VERSION ""

NS_ :

BS_:

BU_: AGSM BCM BSM CADM DMSM DTCM ECM EVCU2 GNMM HCP IPC RFHM SGW TCM
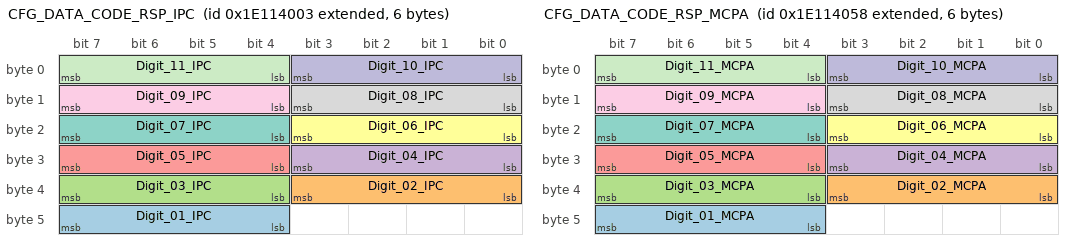
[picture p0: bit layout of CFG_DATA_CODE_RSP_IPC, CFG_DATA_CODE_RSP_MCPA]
BO_ 2651930627 CFG_DATA_CODE_RSP_IPC: 6 IPC
 SG_ Digit_01_IPC : 47|4@0+ (1,0) [0|15] "-" BCM
 SG_ Digit_02_IPC : 35|4@0+ (1,0) [0|15] "-" BCM
 SG_ Digit_03_IPC : 39|4@0+ (1,0) [0|15] "-" BCM
 SG_ Digit_04_IPC : 27|4@0+ (1,0) [0|15] "-" BCM
 SG_ Digit_05_IPC : 31|4@0+ (1,0) [0|15] "-" BCM
 SG_ Digit_06_IPC : 19|4@0+ (1,0) [0|15] "-" BCM
 SG_ Digit_07_IPC : 23|4@0+ (1,0) [0|15] "-" BCM
 SG_ Digit_08_IPC : 11|4@0+ (1,0) [0|15] "-" BCM
 SG_ Digit_09_IPC : 15|4@0+ (1,0) [0|15] "-" BCM
 SG_ Digit_10_IPC : 3|4@0+ (1,0) [0|15] "-" BCM
 SG_ Digit_11_IPC : 7|4@0+ (1,0) [0|15] "-" BCM

BO_ 2651930712 CFG_DATA_CODE_RSP_MCPA: 6 EVCU2
 SG_ Digit_01_MCPA : 47|4@0+ (1,0) [0|15] "-" BCM
 SG_ Digit_02_MCPA : 35|4@0+ (1,0) [0|15] "-" BCM
 SG_ Digit_03_MCPA : 39|4@0+ (1,0) [0|15] "-" BCM
 SG_ Digit_04_MCPA : 27|4@0+ (1,0) [0|15] "-" BCM
 SG_ Digit_05_MCPA : 31|4@0+ (1,0) [0|15] "-" BCM
 SG_ Digit_06_MCPA : 19|4@0+ (1,0) [0|15] "-" BCM
 SG_ Digit_07_MCPA : 23|4@0+ (1,0) [0|15] "-" BCM
 SG_ Digit_08_MCPA : 11|4@0+ (1,0) [0|15] "-" BCM
 SG_ Digit_09_MCPA : 15|4@0+ (1,0) [0|15] "-" BCM
 SG_ Digit_10_MCPA : 3|4@0+ (1,0) [0|15] "-" BCM
 SG_ Digit_11_MCPA : 7|4@0+ (1,0) [0|15] "-" BCM

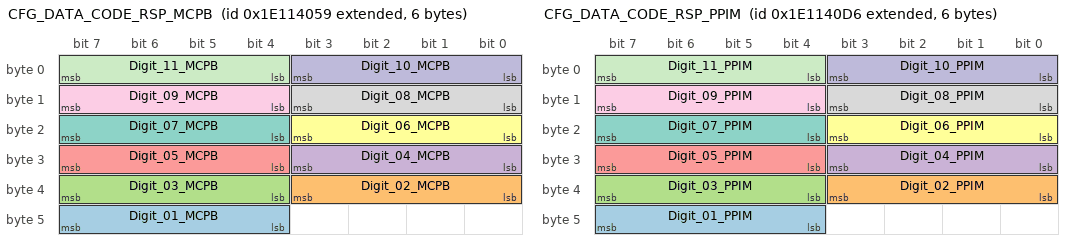
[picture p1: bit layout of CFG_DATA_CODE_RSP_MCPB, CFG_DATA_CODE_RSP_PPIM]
BO_ 2651930713 CFG_DATA_CODE_RSP_MCPB: 6 EVCU2
 SG_ Digit_01_MCPB : 47|4@0+ (1,0) [0|15] "-" BCM
 SG_ Digit_02_MCPB : 35|4@0+ (1,0) [0|15] "-" BCM
 SG_ Digit_03_MCPB : 39|4@0+ (1,0) [0|15] "-" BCM
 SG_ Digit_04_MCPB : 27|4@0+ (1,0) [0|15] "-" BCM
 SG_ Digit_05_MCPB : 31|4@0+ (1,0) [0|15] "-" BCM
 SG_ Digit_06_MCPB : 19|4@0+ (1,0) [0|15] "-" BCM
 SG_ Digit_07_MCPB : 23|4@0+ (1,0) [0|15] "-" BCM
 SG_ Digit_08_MCPB : 11|4@0+ (1,0) [0|15] "-" BCM
 SG_ Digit_09_MCPB : 15|4@0+ (1,0) [0|15] "-" BCM
 SG_ Digit_10_MCPB : 3|4@0+ (1,0) [0|15] "-" BCM
 SG_ Digit_11_MCPB : 7|4@0+ (1,0) [0|15] "-" BCM

BO_ 2651930838 CFG_DATA_CODE_RSP_PPIM: 6 EVCU2
 SG_ Digit_01_PPIM : 47|4@0+ (1,0) [0|15] "-" BCM
 SG_ Digit_02_PPIM : 35|4@0+ (1,0) [0|15] "-" BCM
 SG_ Digit_03_PPIM : 39|4@0+ (1,0) [0|15] "-" BCM
 SG_ Digit_04_PPIM : 27|4@0+ (1,0) [0|15] "-" BCM
 SG_ Digit_05_PPIM : 31|4@0+ (1,0) [0|15] "-" BCM
 SG_ Digit_06_PPIM : 19|4@0+ (1,0) [0|15] "-" BCM
 SG_ Digit_07_PPIM : 23|4@0+ (1,0) [0|15] "-" BCM
 SG_ Digit_08_PPIM : 11|4@0+ (1,0) [0|15] "-" BCM
 SG_ Digit_09_PPIM : 15|4@0+ (1,0) [0|15] "-" BCM
 SG_ Digit_10_PPIM : 3|4@0+ (1,0) [0|15] "-" BCM
 SG_ Digit_11_PPIM : 7|4@0+ (1,0) [0|15] "-" BCM

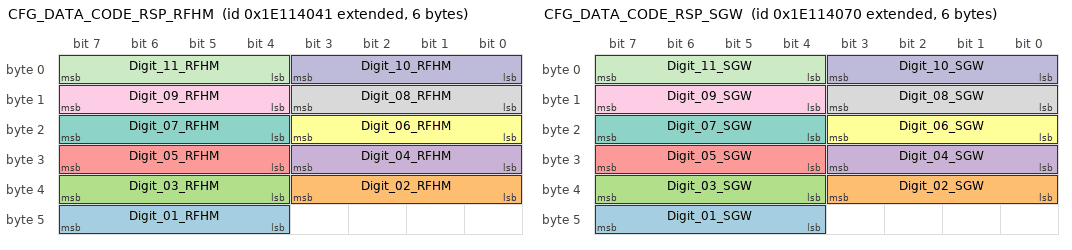
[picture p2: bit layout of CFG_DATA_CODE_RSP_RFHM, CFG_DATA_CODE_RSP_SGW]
BO_ 2651930689 CFG_DATA_CODE_RSP_RFHM: 6 RFHM
 SG_ Digit_01_RFHM : 47|4@0+ (1,0) [0|15] "-" BCM
 SG_ Digit_02_RFHM : 35|4@0+ (1,0) [0|15] "-" BCM
 SG_ Digit_03_RFHM : 39|4@0+ (1,0) [0|15] "-" BCM
 SG_ Digit_04_RFHM : 27|4@0+ (1,0) [0|15] "-" BCM
 SG_ Digit_05_RFHM : 31|4@0+ (1,0) [0|15] "-" BCM
 SG_ Digit_06_RFHM : 19|4@0+ (1,0) [0|15] "-" BCM
 SG_ Digit_07_RFHM : 23|4@0+ (1,0) [0|15] "-" BCM
 SG_ Digit_08_RFHM : 11|4@0+ (1,0) [0|15] "-" BCM
 SG_ Digit_09_RFHM : 15|4@0+ (1,0) [0|15] "-" BCM
 SG_ Digit_10_RFHM : 3|4@0+ (1,0) [0|15] "-" BCM
 SG_ Digit_11_RFHM : 7|4@0+ (1,0) [0|15] "-" BCM

BO_ 2651930736 CFG_DATA_CODE_RSP_SGW: 6 SGW
 SG_ Digit_01_SGW : 47|4@0+ (1,0) [0|15] "-" BCM
 SG_ Digit_02_SGW : 35|4@0+ (1,0) [0|15] "-" BCM
 SG_ Digit_03_SGW : 39|4@0+ (1,0) [0|15] "-" BCM
 SG_ Digit_04_SGW : 27|4@0+ (1,0) [0|15] "-" BCM
 SG_ Digit_05_SGW : 31|4@0+ (1,0) [0|15] "-" BCM
 SG_ Digit_06_SGW : 19|4@0+ (1,0) [0|15] "-" BCM
 SG_ Digit_07_SGW : 23|4@0+ (1,0) [0|15] "-" BCM
 SG_ Digit_08_SGW : 11|4@0+ (1,0) [0|15] "-" BCM
 SG_ Digit_09_SGW : 15|4@0+ (1,0) [0|15] "-" BCM
 SG_ Digit_10_SGW : 3|4@0+ (1,0) [0|15] "-" BCM
 SG_ Digit_11_SGW : 7|4@0+ (1,0) [0|15] "-" BCM

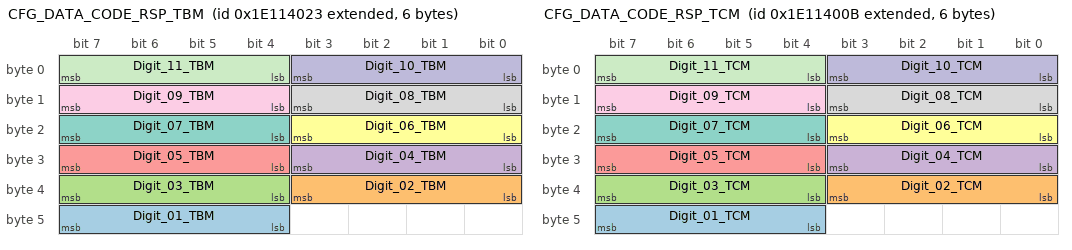
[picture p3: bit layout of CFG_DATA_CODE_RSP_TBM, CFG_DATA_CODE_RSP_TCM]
BO_ 2651930659 CFG_DATA_CODE_RSP_TBM: 6 SGW
 SG_ Digit_01_TBM : 47|4@0+ (1,0) [0|15] "-" BCM
 SG_ Digit_02_TBM : 35|4@0+ (1,0) [0|15] "-" BCM
 SG_ Digit_03_TBM : 39|4@0+ (1,0) [0|15] "-" BCM
 SG_ Digit_04_TBM : 27|4@0+ (1,0) [0|15] "-" BCM
 SG_ Digit_05_TBM : 31|4@0+ (1,0) [0|15] "-" BCM
 SG_ Digit_06_TBM : 19|4@0+ (1,0) [0|15] "-" BCM
 SG_ Digit_07_TBM : 23|4@0+ (1,0) [0|15] "-" BCM
 SG_ Digit_08_TBM : 11|4@0+ (1,0) [0|15] "-" BCM
 SG_ Digit_09_TBM : 15|4@0+ (1,0) [0|15] "-" BCM
 SG_ Digit_10_TBM : 3|4@0+ (1,0) [0|15] "-" BCM
 SG_ Digit_11_TBM : 7|4@0+ (1,0) [0|15] "-" BCM

BO_ 2651930635 CFG_DATA_CODE_RSP_TCM: 6 TCM
 SG_ Digit_01_TCM : 47|4@0+ (1,0) [0|15] "-" BCM
 SG_ Digit_02_TCM : 35|4@0+ (1,0) [0|15] "-" BCM
 SG_ Digit_03_TCM : 39|4@0+ (1,0) [0|15] "-" BCM
 SG_ Digit_04_TCM : 27|4@0+ (1,0) [0|15] "-" BCM
 SG_ Digit_05_TCM : 31|4@0+ (1,0) [0|15] "-" BCM
 SG_ Digit_06_TCM : 19|4@0+ (1,0) [0|15] "-" BCM
 SG_ Digit_07_TCM : 23|4@0+ (1,0) [0|15] "-" BCM
 SG_ Digit_08_TCM : 11|4@0+ (1,0) [0|15] "-" BCM
 SG_ Digit_09_TCM : 15|4@0+ (1,0) [0|15] "-" BCM
 SG_ Digit_10_TCM : 3|4@0+ (1,0) [0|15] "-" BCM
 SG_ Digit_11_TCM : 7|4@0+ (1,0) [0|15] "-" BCM

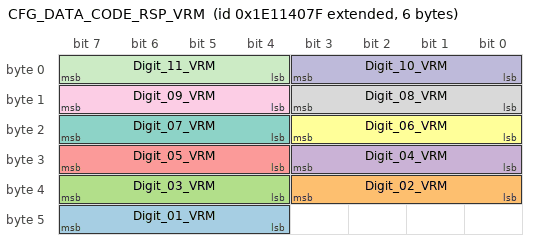
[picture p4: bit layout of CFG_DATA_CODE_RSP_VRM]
BO_ 2651930751 CFG_DATA_CODE_RSP_VRM: 6 SGW
 SG_ Digit_01_VRM : 47|4@0+ (1,0) [0|15] "-" BCM
 SG_ Digit_02_VRM : 35|4@0+ (1,0) [0|15] "-" BCM
 SG_ Digit_03_VRM : 39|4@0+ (1,0) [0|15] "-" BCM
 SG_ Digit_04_VRM : 27|4@0+ (1,0) [0|15] "-" BCM
 SG_ Digit_05_VRM : 31|4@0+ (1,0) [0|15] "-" BCM
 SG_ Digit_06_VRM : 19|4@0+ (1,0) [0|15] "-" BCM
 SG_ Digit_07_VRM : 23|4@0+ (1,0) [0|15] "-" BCM
 SG_ Digit_08_VRM : 11|4@0+ (1,0) [0|15] "-" BCM
 SG_ Digit_09_VRM : 15|4@0+ (1,0) [0|15] "-" BCM
 SG_ Digit_10_VRM : 3|4@0+ (1,0) [0|15] "-" BCM
 SG_ Digit_11_VRM : 7|4@0+ (1,0) [0|15] "-" BCM

BO_ 1457 CHARGE_SCHEDULE_HCP1: 32 EVCU2
 SG_ Charge_Schedule_Type1_Sts : 98|2@0+ (1,0) [0|3] "" SGW
 SG_ Charge_Schedule_Type2_Sts : 107|2@0+ (1,0) [0|3] "" SGW
 SG_ ChargeUntilFull1_Sts : 8|1@0+ (1,0) [0|1] "-" SGW
 SG_ ChargeUntilFull2_Sts : 32|1@0+ (1,0) [0|1] "-" SGW
 SG_ End_Time_Hr1_Sts : 39|5@0+ (1,0) [0|23] "Hours" SGW
 SG_ End_Time_Hr2_Sts : 71|5@0+ (1,0) [0|23] "Hours" SGW
 SG_ End_Time_Min1_Sts : 27|4@0+ (5,0) [0|55] "min" SGW
 SG_ End_Time_Min2_Sts : 79|4@0+ (5,0) [0|55] "min" SGW
 SG_ External_ChargeTarget1_Sts : 120|4@0+ (5,50) [50|125] "%" SGW
 SG_ External_ChargeTarget2_Sts : 132|4@0+ (5,50) [50|125] "%" SGW
 SG_ Immediate_ChargeTarget1_Sts : 117|4@0+ (5,0) [0|15] "%" SGW
 SG_ Immediate_ChargeTarget2_Sts : 124|4@0+ (5,0) [0|15] "%" SGW
 SG_ Schedule_Confirmed1 : 16|1@0+ (1,0) [0|1] "-" SGW
 SG_ Schedule_Confirmed2 : 48|1@0+ (1,0) [0|1] "-" SGW
 SG_ Schedule_Day1_Sts : 7|8@0+ (1,0) [0|255] "-" SGW
 SG_ Schedule_Day2_Sts : 47|8@0+ (1,0) [0|255] "-" SGW
 SG_ Start_Time_Hr1_Sts : 22|5@0+ (1,0) [0|23] "Hours" SGW
 SG_ Start_Time_Hr2_Sts : 54|5@0+ (1,0) [0|23] "Hours" SGW
 SG_ Start_Time_Min1_Sts : 31|4@0+ (5,0) [0|55] "min" SGW
 SG_ Start_Time_Min2_Sts : 63|4@0+ (5,0) [0|55] "min" SGW

BO_ 1464 CHARGE_SCHEDULE_HU1: 32 SGW
 SG_ Charge_Schedule_Type1 : 98|2@0+ (1,0) [0|3] "" EVCU2
 SG_ Charge_Schedule_Type2 : 106|2@0+ (1,0) [0|3] "" EVCU2
 SG_ ChargeUntilFull1 : 8|1@0+ (1,0) [0|1] "-" EVCU2
 SG_ ChargeUntilFull2 : 32|1@0+ (1,0) [0|1] "-" EVCU2
 SG_ Enable_Schedule1 : 72|1@0+ (1,0) [0|1] "-" EVCU2
 SG_ Enable_Schedule2 : 73|1@0+ (1,0) [0|1] "-" EVCU2
 SG_ End_Time_Hr1 : 39|5@0+ (1,0) [0|23] "Hours" EVCU2
 SG_ End_Time_Hr2 : 71|5@0+ (1,0) [0|23] "Hours" EVCU2
 SG_ End_Time_Min1 : 27|4@0+ (5,0) [0|55] "min" EVCU2
 SG_ End_Time_Min2 : 79|4@0+ (5,0) [0|55] "min" EVCU2
 SG_ External_ChargeTarget1 : 143|4@0+ (5,50) [50|125] "%" EVCU2
 SG_ External_ChargeTarget2 : 139|4@0+ (5,50) [50|125] "%" EVCU2
 SG_ Immediate_ChargeTarget1 : 135|4@0+ (5,0) [0|75] "%" EVCU2
 SG_ Immediate_ChargeTarget2 : 131|4@0+ (5,0) [0|75] "%" EVCU2
 SG_ Schedule_Day1 : 7|8@0+ (1,0) [0|255] "-" EVCU2
 SG_ Schedule_Day2 : 47|8@0+ (1,0) [0|255] "-" EVCU2
 SG_ Start_Time_Hr1 : 22|5@0+ (1,0) [0|23] "Hours" EVCU2
 SG_ Start_Time_Hr2 : 54|5@0+ (1,0) [0|23] "Hours" EVCU2
 SG_ Start_Time_Min1 : 31|4@0+ (5,0) [0|55] "min" EVCU2
 SG_ Start_Time_Min2 : 63|4@0+ (5,0) [0|55] "min" EVCU2
 SG_ Submit_Schedule1 : 16|1@0+ (1,0) [0|1] "-" EVCU2
 SG_ Submit_Schedule2 : 48|1@0+ (1,0) [0|1] "-" EVCU2

BO_ 1459 CHARGE_SCHEDULE_NEXT: 32 EVCU2
 SG_ Next_Charge_End_Time_Hr : 12|5@0+ (1,0) [0|30] "Hours" IPC,SGW
 SG_ Next_Charge_End_Time_Min : 39|4@0+ (5,0) [0|55] "min" IPC,SGW
 SG_ Next_Charge_EndDay : 31|4@0+ (1,0) [0|15] "-" IPC,SGW
 SG_ Next_Charge_Start_Time_Hr : 20|5@0+ (1,0) [0|23] "Hours" IPC,SGW
 SG_ Next_Charge_Start_Time_Min : 35|4@0+ (5,0) [0|55] "min" IPC,SGW
 SG_ Next_Charge_StartDay : 27|4@0+ (1,0) [0|15] "-" IPC,SGW
 SG_ Next_Climate_Day : 183|4@0+ (1,0) [0|15] "" SGW
 SG_ Next_Climate_Time_Hr : 172|5@0+ (1,0) [0|23] "Hours" SGW
 SG_ Next_Climate_Time_Min : 163|4@0+ (5,0) [0|55] "min" SGW
 SG_ Next_SchCabin_Temp : 4|5@0+ (0.5,16) [16|31] "°C" Vector__XXX
 SG_ Nxt_Charge_Schedule_Type : 58|2@0+ (1,0) [0|3] "" SGW
 SG_ Nxt_Ext_Charge_End_Time_Hr : 63|5@0+ (1,0) [0|31] "hours" SGW
 SG_ Nxt_Ext_Charge_End_Time_Min : 51|4@0+ (5,0) [0|75] "minutes" SGW
 SG_ Nxt_External_Charge_EndDay : 55|4@0+ (1,0) [0|15] "" SGW
 SG_ Nxt_External_Charge_ExternalTgt : 43|4@0+ (5,50) [50|125] "%" SGW
 SG_ Nxt_External_Charge_ImmediateTgt : 47|4@0+ (5,0) [0|75] "%" SGW

BO_ 1468 CLIMATE_SCHEDULE_HCP1: 32 EVCU2
 SG_ AllowClimateSchd1_Sts : 3|2@0+ (1,0) [0|2] "-" SGW
 SG_ AllowClimateSchd2_Sts : 1|2@0+ (1,0) [0|2] "-" SGW
 SG_ Climate_Cabin_Temp1_Sts : 39|5@0+ (0.5,16) [16|31] "°C" SGW
 SG_ Climate_Cabin_Temp2_Sts : 63|5@0+ (0.5,16) [16|31] "°C" SGW
 SG_ ClimateSchd1_Day_Sts : 47|8@0+ (1,0) [0|254] "-" SGW
 SG_ ClimateSchd1_Departure_Hr_Sts : 23|5@0+ (1,0) [0|30] "Hours" SGW
 SG_ ClimateSchd1_Departure_Min_Sts : 15|4@0+ (5,0) [0|70] "min" SGW
 SG_ ClimateSchd2_Day_Sts : 55|8@0+ (1,0) [0|254] "-" SGW
 SG_ ClimateSchd2_Departure_Hr_Sts : 31|5@0+ (1,0) [0|30] "Hours" SGW
 SG_ ClimateSchd2_Departure_Min_Sts : 11|4@0+ (5,0) [0|70] "min" SGW
 SG_ Enable_ClimateSchd1_Sts : 7|1@0+ (1,0) [0|1] "-" SGW
 SG_ Enable_ClimateSchd2_Sts : 6|1@0+ (1,0) [0|1] "-" SGW

BO_ 1471 CLIMATE_SCHEDULE_HU1: 32 SGW
 SG_ AllowClimateSchd1 : 3|2@0+ (1,0) [0|2] "-" EVCU2
 SG_ AllowClimateSchd2 : 1|2@0+ (1,0) [0|2] "-" EVCU2
 SG_ Climate_Cabin_Temp1 : 39|5@0+ (0.5,16) [16|31] "°C" EVCU2
 SG_ Climate_Cabin_Temp2 : 63|5@0+ (0.5,16) [16|31] "°C" EVCU2
 SG_ ClimateSchd1_Day : 47|8@0+ (1,0) [0|254] "-" EVCU2
 SG_ ClimateSchd1_Departure_Hr : 23|5@0+ (1,0) [0|30] "Hours" EVCU2
 SG_ ClimateSchd1_Departure_Min : 15|4@0+ (5,0) [0|70] "min" EVCU2
 SG_ ClimateSchd2_Day : 55|8@0+ (1,0) [0|254] "-" EVCU2
 SG_ ClimateSchd2_Departure_Hr : 31|5@0+ (1,0) [0|30] "Hours" EVCU2
 SG_ ClimateSchd2_Departure_Min : 11|4@0+ (5,0) [0|70] "min" EVCU2
 SG_ Enable_ClimateSchd1 : 7|1@0+ (1,0) [0|1] "-" EVCU2
 SG_ Enable_ClimateSchd2 : 6|1@0+ (1,0) [0|1] "-" EVCU2
 SG_ Submit_ClimateSchd1 : 5|1@0+ (1,0) [0|1] "-" EVCU2
 SG_ Submit_ClimateSchd2 : 4|1@0+ (1,0) [0|1] "-" EVCU2

CM_ SG_ 1457 Charge_Schedule_Type1_Sts "ECVU/HCP Schedule 1 Currently Set Charge Schedule Type";
CM_ SG_ 1457 Charge_Schedule_Type2_Sts "ECVU/HCP Schedule 2 Currently Set Charge Schedule Type";
CM_ SG_ 1457 ChargeUntilFull1_Sts "Charge until battery is fully charged with schedule 1";
CM_ SG_ 1457 ChargeUntilFull2_Sts "Charge until battery is fully charged with schedule 2 confirmation";
CM_ SG_ 1457 End_Time_Hr1_Sts "End Time of schedule 1 (hours in 24 hrs. format)";
CM_ SG_ 1457 End_Time_Hr2_Sts "End Time of schedule  2 (hours in 24 hrs. format) feedback";
CM_ SG_ 1457 End_Time_Min1_Sts "End Time of schedule 1(Minutes)";
CM_ SG_ 1457 End_Time_Min2_Sts "End Time of schedule  2 (Minutes) feedback";
CM_ SG_ 1457 External_ChargeTarget1_Sts "ECVU/HCP Schedule 1 Currently Set External Charge Target Value";
CM_ SG_ 1457 External_ChargeTarget2_Sts "ECVU/HCP Schedule 2 Currently Set External Charge Target Value";
CM_ SG_ 1457 Immediate_ChargeTarget1_Sts "ECVU/HCP Schedule 1 Currently Set Immediate Charge Target Value";
CM_ SG_ 1457 Immediate_ChargeTarget2_Sts "ECVU/HCP Schedule 2 Currently Set Immediate Charge Target Value
0 to 50% with 5% Increment";
CM_ SG_ 1457 Schedule_Confirmed1 "Confirm the requested schedule 1";
CM_ SG_ 1457 Schedule_Confirmed2 "Confirm the requested schedule 2";
CM_ SG_ 1457 Schedule_Day1_Sts "Schedule#1 Day for charging or cabin conditioning";
CM_ SG_ 1457 Schedule_Day2_Sts "Scheduled#2 Day for charging or cabin conditioning confirmation";
CM_ SG_ 1457 Start_Time_Hr1_Sts "Start Time of schedule  1 (hours in 24 hrs. format)";
CM_ SG_ 1457 Start_Time_Hr2_Sts "Start Time of schedule  2(hours in 24 hrs. format) feedback";
CM_ SG_ 1457 Start_Time_Min1_Sts "Start Time of schedule  1 (minutes)";
CM_ SG_ 1457 Start_Time_Min2_Sts "Start Time of schedule  2 (minutes) feedback";
CM_ SG_ 1464 Charge_Schedule_Type1 "HU Schedule 1 Setter Signal for Changing the Current Charge Schedule Type";
CM_ SG_ 1464 Charge_Schedule_Type2 "HU Schedule 2 Setter Signal for Changing the Current Charge Schedule Type";
CM_ SG_ 1464 ChargeUntilFull1 "Charge until battery is fully charged with schedule 1";
CM_ SG_ 1464 ChargeUntilFull2 "Charge until battery is fully charged with schedule 2";
CM_ SG_ 1464 Enable_Schedule1 "Schedule 1 checkbox enabled";
CM_ SG_ 1464 Enable_Schedule2 "Schedule 2 checkbox enabled";
CM_ SG_ 1464 End_Time_Hr1 "End Time of schedule 1 (hours in 24 hrs. format)";
CM_ SG_ 1464 End_Time_Hr2 "End Time of schedule  2 (hours in 24 hrs. format)";
CM_ SG_ 1464 End_Time_Min1 "End Time of schedule 1(Minutes)";
CM_ SG_ 1464 End_Time_Min2 "End Time of schedule  2(Minutes)";
CM_ SG_ 1464 External_ChargeTarget1 "HU Schedule 1 Setter Signal for Changing the Current External Charge Target Value 50 to 100% with 5% Increment";
CM_ SG_ 1464 External_ChargeTarget2 "HU Schedule 2 Setter Signal for Changing the Current External Charge Target Value";
CM_ SG_ 1464 Immediate_ChargeTarget1 "HU Schedule 1 Setter Signal for Changing the Current Immediate Charge Target Value";
CM_ SG_ 1464 Immediate_ChargeTarget2 "HU Schedule 2 Setter Signal for Changing the Current Immediate Charge Target Value";
CM_ SG_ 1464 Schedule_Day1 "Schedule#1 Day for charging or cabin conditioning";
CM_ SG_ 1464 Schedule_Day2 "Schedule#2 Day for charging or cabin conditioning";
CM_ SG_ 1464 Start_Time_Hr1 "Start Time of schedule  1 (hours in 24 hrs. format)";
CM_ SG_ 1464 Start_Time_Hr2 "Start Time of schedule  2(hours in 24 hrs. format)";
CM_ SG_ 1464 Start_Time_Min1 "Start Time of schedule  1 (minutes)";
CM_ SG_ 1464 Start_Time_Min2 "Start Time of schedule  2 (minutes)";
CM_ SG_ 1464 Submit_Schedule1 "Schedule 1 submitted";
CM_ SG_ 1464 Submit_Schedule2 "Schedule 2 submitted";
CM_ SG_ 1459 Next_Charge_End_Time_Hr "End time of next charge schedule window (hours, in 24hr format).";
CM_ SG_ 1459 Next_Charge_End_Time_Min "End time of next charge schedule window (in minutes).";
CM_ SG_ 1459 Next_Charge_EndDay "Next schedule end day to stop charging.";
CM_ SG_ 1459 Next_Charge_Start_Time_Hr "Start time of next charge schedule window (hours, in 24hr format).";
CM_ SG_ 1459 Next_Charge_Start_Time_Min "Start time of next charge schedule window (in minutes).";
CM_ SG_ 1459 Next_Charge_StartDay "Next schedule start day for charging.";
CM_ SG_ 1459 Next_Climate_Day "Next climate scheduled departure day";
CM_ SG_ 1459 Next_Climate_Time_Hr "Next climate scheduled departure time (hours, in 24hr format).";
CM_ SG_ 1459 Next_Climate_Time_Min "Next climate scheduled departure time (minutes).";
CM_ SG_ 1459 Next_SchCabin_Temp "Next Schedule cabin temperature";
CM_ SG_ 1459 Nxt_Charge_Schedule_Type "Standard, External or Both Charging of the Next Schedule";
CM_ SG_ 1459 Nxt_Ext_Charge_End_Time_Hr "End Hour for Next available External Charge";
CM_ SG_ 1459 Nxt_Ext_Charge_End_Time_Min "End Min for Next available External Charge";
CM_ SG_ 1459 Nxt_External_Charge_EndDay "End Day for Next available External Charge";
CM_ SG_ 1459 Nxt_External_Charge_ExternalTgt "Next Charge Display for Customer set External Target Display 50 to 100% with 5% Increment";
CM_ SG_ 1459 Nxt_External_Charge_ImmediateTgt "Next Charge Display for Customer set Immediate Target Display";
CM_ SG_ 1468 AllowClimateSchd1_Sts "Climate Scheduling1 Options";
CM_ SG_ 1468 AllowClimateSchd2_Sts "Climate Scheduling2 Options";
CM_ SG_ 1468 Climate_Cabin_Temp1_Sts "Schedule1 cabin temperature";
CM_ SG_ 1468 Climate_Cabin_Temp2_Sts "Schedule1 cabin temperature";
CM_ SG_ 1468 ClimateSchd1_Day_Sts "Scheduled#1 Day for cabin conditioning confirmation";
CM_ SG_ 1468 ClimateSchd1_Departure_Hr_Sts "Departure time of schedule 1 (hours in 24 hrs. format)";
CM_ SG_ 1468 ClimateSchd1_Departure_Min_Sts "Departure time of schedule 1(Minutes)";
CM_ SG_ 1468 ClimateSchd2_Day_Sts "Scheduled#2 Day for cabin conditioning confirmation";
CM_ SG_ 1468 ClimateSchd2_Departure_Hr_Sts "Departure time of schedule 2 (hours in 24 hrs. format)";
CM_ SG_ 1468 ClimateSchd2_Departure_Min_Sts "Departure time of schedule 2(Minutes)";
CM_ SG_ 1468 Enable_ClimateSchd1_Sts "Climate Schedule 1 checkbox enable status";
CM_ SG_ 1468 Enable_ClimateSchd2_Sts "Climate Schedule 2 checkbox enable status";
CM_ SG_ 1471 AllowClimateSchd1 "Climate Scheduling1 Options";
CM_ SG_ 1471 AllowClimateSchd2 "Climate Scheduling2 Options";
CM_ SG_ 1471 Climate_Cabin_Temp1 "Schedule1 cabin temperature";
CM_ SG_ 1471 Climate_Cabin_Temp2 "Schedule2 cabin temperature";
CM_ SG_ 1471 ClimateSchd1_Day "Schedule#1 Day for cabin conditioning";
CM_ SG_ 1471 ClimateSchd1_Departure_Hr "Departure time of schedule 1 (hours in 24 hrs. format)";
CM_ SG_ 1471 ClimateSchd1_Departure_Min "Departure time of schedule 1(Minutes)";
CM_ SG_ 1471 ClimateSchd2_Day "Scheduled#2 Day for cabin conditioning";
CM_ SG_ 1471 ClimateSchd2_Departure_Hr "Departure time of schedule 2 (hours in 24 hrs. format)";
CM_ SG_ 1471 ClimateSchd2_Departure_Min "Departure time of schedule 2(Minutes)";
CM_ SG_ 1471 Enable_ClimateSchd1 "Climate Schedule 1 checkbox enabled";
CM_ SG_ 1471 Enable_ClimateSchd2 "Climate Schedule 2 checkbox enabled";
CM_ SG_ 1471 Submit_ClimateSchd1 "Climate Schedule 1 submitted";
CM_ SG_ 1471 Submit_ClimateSchd2 "Climate Schedule 2 submitted";

BA_DEF_ SG_ "GenSigStartValue" INT 0 2147483647;
BA_DEF_ SG_ "GenSigInactiveValue" INT 0 2147483647;
BA_DEF_ SG_ "GenSigSendType" ENUM "NotUsed","OnWrite","OnWriteWithRepetition","OnChange","OnChangeWithRepetition","IfActive","IfActiveWithRepetition","NoSigSendType";
BA_DEF_ SG_ "SystemSignalLongSymbol" STRING ;
BA_DEF_ SG_ "GenSigTimeoutTime_AGSM" INT 0 65535;
BA_DEF_ SG_ "GenSigTimeoutTime_BCM" INT 0 65535;
BA_DEF_ SG_ "GenSigTimeoutTime_BSM" INT 0 65535;
BA_DEF_ SG_ "GenSigTimeoutTime_CADM" INT 0 65535;
BA_DEF_ SG_ "GenSigTimeoutTime_DMSM" INT 0 65535;
BA_DEF_ SG_ "GenSigTimeoutTime_DTCM" INT 0 65535;
BA_DEF_ SG_ "GenSigTimeoutTime_ECM" INT 0 65535;
BA_DEF_ SG_ "GenSigTimeoutTime_EVCU2" INT 0 65535;
BA_DEF_ SG_ "GenSigTimeoutTime_GNMM" INT 0 65535;
BA_DEF_ SG_ "GenSigTimeoutTime_HCP" INT 0 65535;
BA_DEF_ SG_ "GenSigTimeoutTime_IPC" INT 0 65535;
BA_DEF_ SG_ "GenSigTimeoutTime_RFHM" INT 0 65535;
BA_DEF_ SG_ "GenSigTimeoutTime_SGW" INT 0 65535;
BA_DEF_ SG_ "GenSigTimeoutTime_TCM" INT 0 65535;
BA_DEF_ BO_ "DiagRequest" ENUM "No","Yes";
BA_DEF_ BO_ "Type" ENUM "P","C","PE","COC","PE_Cntrl","E","E_Cntrl","OC","S","BAF","DC","EM","MM","ISO-TP","-";
BA_DEF_ BO_ "DiagResponse" ENUM "No","Yes";
BA_DEF_ BO_ "NmMessage" ENUM "No","Yes";
BA_DEF_ BO_ "GenMsgSendType" ENUM "Cyclic","NotUsed","NotUsed","NotUsed","NotUsed","NotUsed","NotUsed","NotUsed","NoMsgSendType";
BA_DEF_ BO_ "GenMsgNrOfRepetition" INT 0 255;
BA_DEF_ BO_ "GenMsgILSupport" ENUM "No","Yes";
BA_DEF_ BO_ "GenMsgStartDelayTime" INT 0 65535;
BA_DEF_ BO_ "GenMsgCycleTimeFast" INT 0 65535;
BA_DEF_ BO_ "GenMsgCycleTime" INT 0 65535;
BA_DEF_ BO_ "GenMsgDelayTime" INT 0 65535;
BA_DEF_ BO_ "NmAsrMessage" ENUM "No","Yes";
BA_DEF_ BO_ "DiagState" ENUM "No","Yes";
BA_DEF_ BO_ "DiagConnection" HEX 0 65535;
BA_DEF_ BO_ "VFrameFormat" ENUM "StandardCAN","ExtendedCAN","reserved","reserved","reserved","reserved","reserved","reserved","reserved","reserved","reserved","reserved","reserved","reserved","StandardCAN_FD","ExtendedCAN_FD";
BA_DEF_ BO_ "CANFD_BRS" ENUM "No","Yes";
BA_DEF_DEF_ "DiagRequest" "No";
BA_DEF_DEF_ "Type" "-";
BA_DEF_DEF_ "DiagResponse" "No";
BA_DEF_DEF_ "NmMessage" "No";
BA_DEF_DEF_ "GenMsgSendType" "NoMsgSendType";
BA_DEF_DEF_ "GenMsgNrOfRepetition" 0;
BA_DEF_DEF_ "GenMsgILSupport" "No";
BA_DEF_DEF_ "GenMsgStartDelayTime" 0;
BA_DEF_DEF_ "GenMsgCycleTimeFast" 0;
BA_DEF_DEF_ "GenMsgCycleTime" 0;
BA_DEF_DEF_ "GenMsgDelayTime" 0;
BA_DEF_DEF_ "NmAsrMessage" "No";
BA_DEF_DEF_ "DiagState" "No";
BA_DEF_DEF_ "DiagConnection" 0;
BA_DEF_DEF_ "VFrameFormat" "StandardCAN_FD";
BA_DEF_DEF_ "CANFD_BRS" "No";
BA_DEF_DEF_ "GenSigStartValue" 0;
BA_DEF_DEF_ "GenSigInactiveValue" 0;
BA_DEF_DEF_ "GenSigSendType" "NoSigSendType";
BA_DEF_DEF_ "SystemSignalLongSymbol" "";
BA_DEF_DEF_ "GenSigTimeoutTime_AGSM" 2500;
BA_DEF_DEF_ "GenSigTimeoutTime_BCM" 2500;
BA_DEF_DEF_ "GenSigTimeoutTime_BSM" 2500;
BA_DEF_DEF_ "GenSigTimeoutTime_CADM" 2500;
BA_DEF_DEF_ "GenSigTimeoutTime_DMSM" 2500;
BA_DEF_DEF_ "GenSigTimeoutTime_DTCM" 2500;
BA_DEF_DEF_ "GenSigTimeoutTime_ECM" 2500;
BA_DEF_DEF_ "GenSigTimeoutTime_EVCU2" 2500;
BA_DEF_DEF_ "GenSigTimeoutTime_GNMM" 2500;
BA_DEF_DEF_ "GenSigTimeoutTime_HCP" 2500;
BA_DEF_DEF_ "GenSigTimeoutTime_IPC" 2500;
BA_DEF_DEF_ "GenSigTimeoutTime_RFHM" 2500;
BA_DEF_DEF_ "GenSigTimeoutTime_SGW" 2500;
BA_DEF_DEF_ "GenSigTimeoutTime_TCM" 2500;
BA_ "Type" BO_ 2651930627 11;
BA_ "GenMsgILSupport" BO_ 2651930627 1;
BA_ "VFrameFormat" BO_ 2651930627 15;
BA_ "CANFD_BRS" BO_ 2651930627 1;
BA_ "Type" BO_ 2651930712 11;
BA_ "GenMsgILSupport" BO_ 2651930712 1;
BA_ "VFrameFormat" BO_ 2651930712 15;
BA_ "CANFD_BRS" BO_ 2651930712 1;
BA_ "Type" BO_ 2651930713 11;
BA_ "GenMsgILSupport" BO_ 2651930713 1;
BA_ "VFrameFormat" BO_ 2651930713 15;
BA_ "CANFD_BRS" BO_ 2651930713 1;
BA_ "Type" BO_ 2651930838 11;
BA_ "GenMsgILSupport" BO_ 2651930838 1;
BA_ "VFrameFormat" BO_ 2651930838 15;
BA_ "CANFD_BRS" BO_ 2651930838 1;
BA_ "Type" BO_ 2651930689 11;
BA_ "GenMsgILSupport" BO_ 2651930689 1;
BA_ "VFrameFormat" BO_ 2651930689 15;
BA_ "CANFD_BRS" BO_ 2651930689 1;
BA_ "Type" BO_ 2651930736 11;
BA_ "GenMsgILSupport" BO_ 2651930736 1;
BA_ "VFrameFormat" BO_ 2651930736 15;
BA_ "CANFD_BRS" BO_ 2651930736 1;
BA_ "Type" BO_ 2651930659 11;
BA_ "GenMsgILSupport" BO_ 2651930659 1;
BA_ "VFrameFormat" BO_ 2651930659 15;
BA_ "CANFD_BRS" BO_ 2651930659 1;
BA_ "Type" BO_ 2651930635 11;
BA_ "GenMsgILSupport" BO_ 2651930635 1;
BA_ "VFrameFormat" BO_ 2651930635 15;
BA_ "CANFD_BRS" BO_ 2651930635 1;
BA_ "Type" BO_ 2651930751 11;
BA_ "GenMsgILSupport" BO_ 2651930751 1;
BA_ "VFrameFormat" BO_ 2651930751 15;
BA_ "CANFD_BRS" BO_ 2651930751 1;
BA_ "Type" BO_ 1457 3;
BA_ "GenMsgSendType" BO_ 1457 0;
BA_ "GenMsgILSupport" BO_ 1457 1;
BA_ "GenMsgCycleTime" BO_ 1457 1000;
BA_ "GenMsgDelayTime" BO_ 1457 20;
BA_ "CANFD_BRS" BO_ 1457 1;
BA_ "Type" BO_ 1464 3;
BA_ "GenMsgSendType" BO_ 1464 0;
BA_ "GenMsgILSupport" BO_ 1464 1;
BA_ "GenMsgStartDelayTime" BO_ 1464 230;
BA_ "GenMsgCycleTime" BO_ 1464 1000;
BA_ "GenMsgDelayTime" BO_ 1464 20;
BA_ "CANFD_BRS" BO_ 1464 1;
BA_ "Type" BO_ 1459 3;
BA_ "GenMsgSendType" BO_ 1459 0;
BA_ "GenMsgILSupport" BO_ 1459 1;
BA_ "GenMsgCycleTime" BO_ 1459 1000;
BA_ "GenMsgDelayTime" BO_ 1459 20;
BA_ "CANFD_BRS" BO_ 1459 1;
BA_ "Type" BO_ 1468 3;
BA_ "GenMsgSendType" BO_ 1468 0;
BA_ "GenMsgILSupport" BO_ 1468 1;
BA_ "GenMsgCycleTime" BO_ 1468 1000;
BA_ "CANFD_BRS" BO_ 1468 1;
BA_ "Type" BO_ 1471 3;
BA_ "GenMsgSendType" BO_ 1471 0;
BA_ "GenMsgILSupport" BO_ 1471 1;
BA_ "GenMsgCycleTime" BO_ 1471 1000;
BA_ "CANFD_BRS" BO_ 1471 1;
BA_ "GenSigSendType" SG_ 2651930627 Digit_01_IPC 1;
BA_ "GenSigTimeoutTime_AGSM" SG_ 2651930627 Digit_01_IPC 0;
BA_ "GenSigTimeoutTime_BSM" SG_ 2651930627 Digit_01_IPC 0;
BA_ "GenSigTimeoutTime_CADM" SG_ 2651930627 Digit_01_IPC 0;
BA_ "GenSigTimeoutTime_DMSM" SG_ 2651930627 Digit_01_IPC 0;
BA_ "GenSigTimeoutTime_DTCM" SG_ 2651930627 Digit_01_IPC 0;
BA_ "GenSigTimeoutTime_ECM" SG_ 2651930627 Digit_01_IPC 0;
BA_ "GenSigTimeoutTime_EVCU2" SG_ 2651930627 Digit_01_IPC 0;
BA_ "GenSigTimeoutTime_GNMM" SG_ 2651930627 Digit_01_IPC 0;
BA_ "GenSigTimeoutTime_HCP" SG_ 2651930627 Digit_01_IPC 0;
BA_ "GenSigTimeoutTime_IPC" SG_ 2651930627 Digit_01_IPC 0;
BA_ "GenSigTimeoutTime_RFHM" SG_ 2651930627 Digit_01_IPC 0;
BA_ "GenSigTimeoutTime_SGW" SG_ 2651930627 Digit_01_IPC 0;
BA_ "GenSigTimeoutTime_TCM" SG_ 2651930627 Digit_01_IPC 0;
BA_ "GenSigTimeoutTime_AGSM" SG_ 2651930627 Digit_02_IPC 0;
BA_ "GenSigTimeoutTime_BSM" SG_ 2651930627 Digit_02_IPC 0;
BA_ "GenSigTimeoutTime_CADM" SG_ 2651930627 Digit_02_IPC 0;
BA_ "GenSigTimeoutTime_DMSM" SG_ 2651930627 Digit_02_IPC 0;
BA_ "GenSigTimeoutTime_DTCM" SG_ 2651930627 Digit_02_IPC 0;
BA_ "GenSigTimeoutTime_ECM" SG_ 2651930627 Digit_02_IPC 0;
BA_ "GenSigTimeoutTime_EVCU2" SG_ 2651930627 Digit_02_IPC 0;
BA_ "GenSigTimeoutTime_GNMM" SG_ 2651930627 Digit_02_IPC 0;
BA_ "GenSigTimeoutTime_HCP" SG_ 2651930627 Digit_02_IPC 0;
BA_ "GenSigTimeoutTime_IPC" SG_ 2651930627 Digit_02_IPC 0;
BA_ "GenSigTimeoutTime_RFHM" SG_ 2651930627 Digit_02_IPC 0;
BA_ "GenSigTimeoutTime_SGW" SG_ 2651930627 Digit_02_IPC 0;
BA_ "GenSigTimeoutTime_TCM" SG_ 2651930627 Digit_02_IPC 0;
BA_ "GenSigTimeoutTime_AGSM" SG_ 2651930627 Digit_03_IPC 0;
BA_ "GenSigTimeoutTime_BSM" SG_ 2651930627 Digit_03_IPC 0;
BA_ "GenSigTimeoutTime_CADM" SG_ 2651930627 Digit_03_IPC 0;
BA_ "GenSigTimeoutTime_DMSM" SG_ 2651930627 Digit_03_IPC 0;
BA_ "GenSigTimeoutTime_DTCM" SG_ 2651930627 Digit_03_IPC 0;
BA_ "GenSigTimeoutTime_ECM" SG_ 2651930627 Digit_03_IPC 0;
BA_ "GenSigTimeoutTime_EVCU2" SG_ 2651930627 Digit_03_IPC 0;
BA_ "GenSigTimeoutTime_GNMM" SG_ 2651930627 Digit_03_IPC 0;
BA_ "GenSigTimeoutTime_HCP" SG_ 2651930627 Digit_03_IPC 0;
BA_ "GenSigTimeoutTime_IPC" SG_ 2651930627 Digit_03_IPC 0;
BA_ "GenSigTimeoutTime_RFHM" SG_ 2651930627 Digit_03_IPC 0;
BA_ "GenSigTimeoutTime_SGW" SG_ 2651930627 Digit_03_IPC 0;
BA_ "GenSigTimeoutTime_TCM" SG_ 2651930627 Digit_03_IPC 0;
BA_ "GenSigTimeoutTime_AGSM" SG_ 2651930627 Digit_04_IPC 0;
BA_ "GenSigTimeoutTime_BSM" SG_ 2651930627 Digit_04_IPC 0;
BA_ "GenSigTimeoutTime_CADM" SG_ 2651930627 Digit_04_IPC 0;
BA_ "GenSigTimeoutTime_DMSM" SG_ 2651930627 Digit_04_IPC 0;
BA_ "GenSigTimeoutTime_DTCM" SG_ 2651930627 Digit_04_IPC 0;
BA_ "GenSigTimeoutTime_ECM" SG_ 2651930627 Digit_04_IPC 0;
BA_ "GenSigTimeoutTime_EVCU2" SG_ 2651930627 Digit_04_IPC 0;
BA_ "GenSigTimeoutTime_GNMM" SG_ 2651930627 Digit_04_IPC 0;
BA_ "GenSigTimeoutTime_HCP" SG_ 2651930627 Digit_04_IPC 0;
BA_ "GenSigTimeoutTime_IPC" SG_ 2651930627 Digit_04_IPC 0;
BA_ "GenSigTimeoutTime_RFHM" SG_ 2651930627 Digit_04_IPC 0;
BA_ "GenSigTimeoutTime_SGW" SG_ 2651930627 Digit_04_IPC 0;
BA_ "GenSigTimeoutTime_TCM" SG_ 2651930627 Digit_04_IPC 0;
BA_ "GenSigTimeoutTime_AGSM" SG_ 2651930627 Digit_05_IPC 0;
BA_ "GenSigTimeoutTime_BSM" SG_ 2651930627 Digit_05_IPC 0;
BA_ "GenSigTimeoutTime_CADM" SG_ 2651930627 Digit_05_IPC 0;
BA_ "GenSigTimeoutTime_DMSM" SG_ 2651930627 Digit_05_IPC 0;
BA_ "GenSigTimeoutTime_DTCM" SG_ 2651930627 Digit_05_IPC 0;
BA_ "GenSigTimeoutTime_ECM" SG_ 2651930627 Digit_05_IPC 0;
BA_ "GenSigTimeoutTime_EVCU2" SG_ 2651930627 Digit_05_IPC 0;
BA_ "GenSigTimeoutTime_GNMM" SG_ 2651930627 Digit_05_IPC 0;
BA_ "GenSigTimeoutTime_HCP" SG_ 2651930627 Digit_05_IPC 0;
BA_ "GenSigTimeoutTime_IPC" SG_ 2651930627 Digit_05_IPC 0;
BA_ "GenSigTimeoutTime_RFHM" SG_ 2651930627 Digit_05_IPC 0;
BA_ "GenSigTimeoutTime_SGW" SG_ 2651930627 Digit_05_IPC 0;
BA_ "GenSigTimeoutTime_TCM" SG_ 2651930627 Digit_05_IPC 0;
BA_ "GenSigTimeoutTime_AGSM" SG_ 2651930627 Digit_06_IPC 0;
BA_ "GenSigTimeoutTime_BSM" SG_ 2651930627 Digit_06_IPC 0;
BA_ "GenSigTimeoutTime_CADM" SG_ 2651930627 Digit_06_IPC 0;
BA_ "GenSigTimeoutTime_DMSM" SG_ 2651930627 Digit_06_IPC 0;
BA_ "GenSigTimeoutTime_DTCM" SG_ 2651930627 Digit_06_IPC 0;
BA_ "GenSigTimeoutTime_ECM" SG_ 2651930627 Digit_06_IPC 0;
BA_ "GenSigTimeoutTime_EVCU2" SG_ 2651930627 Digit_06_IPC 0;
BA_ "GenSigTimeoutTime_GNMM" SG_ 2651930627 Digit_06_IPC 0;
BA_ "GenSigTimeoutTime_HCP" SG_ 2651930627 Digit_06_IPC 0;
BA_ "GenSigTimeoutTime_IPC" SG_ 2651930627 Digit_06_IPC 0;
BA_ "GenSigTimeoutTime_RFHM" SG_ 2651930627 Digit_06_IPC 0;
BA_ "GenSigTimeoutTime_SGW" SG_ 2651930627 Digit_06_IPC 0;
BA_ "GenSigTimeoutTime_TCM" SG_ 2651930627 Digit_06_IPC 0;
BA_ "GenSigTimeoutTime_AGSM" SG_ 2651930627 Digit_07_IPC 0;
BA_ "GenSigTimeoutTime_BSM" SG_ 2651930627 Digit_07_IPC 0;
BA_ "GenSigTimeoutTime_CADM" SG_ 2651930627 Digit_07_IPC 0;
BA_ "GenSigTimeoutTime_DMSM" SG_ 2651930627 Digit_07_IPC 0;
BA_ "GenSigTimeoutTime_DTCM" SG_ 2651930627 Digit_07_IPC 0;
BA_ "GenSigTimeoutTime_ECM" SG_ 2651930627 Digit_07_IPC 0;
BA_ "GenSigTimeoutTime_EVCU2" SG_ 2651930627 Digit_07_IPC 0;
BA_ "GenSigTimeoutTime_GNMM" SG_ 2651930627 Digit_07_IPC 0;
BA_ "GenSigTimeoutTime_HCP" SG_ 2651930627 Digit_07_IPC 0;
BA_ "GenSigTimeoutTime_IPC" SG_ 2651930627 Digit_07_IPC 0;
BA_ "GenSigTimeoutTime_RFHM" SG_ 2651930627 Digit_07_IPC 0;
BA_ "GenSigTimeoutTime_SGW" SG_ 2651930627 Digit_07_IPC 0;
BA_ "GenSigTimeoutTime_TCM" SG_ 2651930627 Digit_07_IPC 0;
BA_ "GenSigTimeoutTime_AGSM" SG_ 2651930627 Digit_08_IPC 0;
BA_ "GenSigTimeoutTime_BSM" SG_ 2651930627 Digit_08_IPC 0;
BA_ "GenSigTimeoutTime_CADM" SG_ 2651930627 Digit_08_IPC 0;
BA_ "GenSigTimeoutTime_DMSM" SG_ 2651930627 Digit_08_IPC 0;
BA_ "GenSigTimeoutTime_DTCM" SG_ 2651930627 Digit_08_IPC 0;
BA_ "GenSigTimeoutTime_ECM" SG_ 2651930627 Digit_08_IPC 0;
BA_ "GenSigTimeoutTime_EVCU2" SG_ 2651930627 Digit_08_IPC 0;
BA_ "GenSigTimeoutTime_GNMM" SG_ 2651930627 Digit_08_IPC 0;
BA_ "GenSigTimeoutTime_HCP" SG_ 2651930627 Digit_08_IPC 0;
BA_ "GenSigTimeoutTime_IPC" SG_ 2651930627 Digit_08_IPC 0;
BA_ "GenSigTimeoutTime_RFHM" SG_ 2651930627 Digit_08_IPC 0;
BA_ "GenSigTimeoutTime_SGW" SG_ 2651930627 Digit_08_IPC 0;
BA_ "GenSigTimeoutTime_TCM" SG_ 2651930627 Digit_08_IPC 0;
BA_ "GenSigTimeoutTime_AGSM" SG_ 2651930627 Digit_09_IPC 0;
BA_ "GenSigTimeoutTime_BSM" SG_ 2651930627 Digit_09_IPC 0;
BA_ "GenSigTimeoutTime_CADM" SG_ 2651930627 Digit_09_IPC 0;
BA_ "GenSigTimeoutTime_DMSM" SG_ 2651930627 Digit_09_IPC 0;
BA_ "GenSigTimeoutTime_DTCM" SG_ 2651930627 Digit_09_IPC 0;
BA_ "GenSigTimeoutTime_ECM" SG_ 2651930627 Digit_09_IPC 0;
BA_ "GenSigTimeoutTime_EVCU2" SG_ 2651930627 Digit_09_IPC 0;
BA_ "GenSigTimeoutTime_GNMM" SG_ 2651930627 Digit_09_IPC 0;
BA_ "GenSigTimeoutTime_HCP" SG_ 2651930627 Digit_09_IPC 0;
BA_ "GenSigTimeoutTime_IPC" SG_ 2651930627 Digit_09_IPC 0;
BA_ "GenSigTimeoutTime_RFHM" SG_ 2651930627 Digit_09_IPC 0;
BA_ "GenSigTimeoutTime_SGW" SG_ 2651930627 Digit_09_IPC 0;
BA_ "GenSigTimeoutTime_TCM" SG_ 2651930627 Digit_09_IPC 0;
BA_ "GenSigTimeoutTime_AGSM" SG_ 2651930627 Digit_10_IPC 0;
BA_ "GenSigTimeoutTime_BSM" SG_ 2651930627 Digit_10_IPC 0;
BA_ "GenSigTimeoutTime_CADM" SG_ 2651930627 Digit_10_IPC 0;
BA_ "GenSigTimeoutTime_DMSM" SG_ 2651930627 Digit_10_IPC 0;
BA_ "GenSigTimeoutTime_DTCM" SG_ 2651930627 Digit_10_IPC 0;
BA_ "GenSigTimeoutTime_ECM" SG_ 2651930627 Digit_10_IPC 0;
BA_ "GenSigTimeoutTime_EVCU2" SG_ 2651930627 Digit_10_IPC 0;
BA_ "GenSigTimeoutTime_GNMM" SG_ 2651930627 Digit_10_IPC 0;
BA_ "GenSigTimeoutTime_HCP" SG_ 2651930627 Digit_10_IPC 0;
BA_ "GenSigTimeoutTime_IPC" SG_ 2651930627 Digit_10_IPC 0;
BA_ "GenSigTimeoutTime_RFHM" SG_ 2651930627 Digit_10_IPC 0;
BA_ "GenSigTimeoutTime_SGW" SG_ 2651930627 Digit_10_IPC 0;
BA_ "GenSigTimeoutTime_TCM" SG_ 2651930627 Digit_10_IPC 0;
BA_ "GenSigTimeoutTime_AGSM" SG_ 2651930627 Digit_11_IPC 0;
BA_ "GenSigTimeoutTime_BSM" SG_ 2651930627 Digit_11_IPC 0;
BA_ "GenSigTimeoutTime_CADM" SG_ 2651930627 Digit_11_IPC 0;
BA_ "GenSigTimeoutTime_DMSM" SG_ 2651930627 Digit_11_IPC 0;
BA_ "GenSigTimeoutTime_DTCM" SG_ 2651930627 Digit_11_IPC 0;
BA_ "GenSigTimeoutTime_ECM" SG_ 2651930627 Digit_11_IPC 0;
BA_ "GenSigTimeoutTime_EVCU2" SG_ 2651930627 Digit_11_IPC 0;
BA_ "GenSigTimeoutTime_GNMM" SG_ 2651930627 Digit_11_IPC 0;
BA_ "GenSigTimeoutTime_HCP" SG_ 2651930627 Digit_11_IPC 0;
BA_ "GenSigTimeoutTime_IPC" SG_ 2651930627 Digit_11_IPC 0;
BA_ "GenSigTimeoutTime_RFHM" SG_ 2651930627 Digit_11_IPC 0;
BA_ "GenSigTimeoutTime_SGW" SG_ 2651930627 Digit_11_IPC 0;
BA_ "GenSigTimeoutTime_TCM" SG_ 2651930627 Digit_11_IPC 0;
BA_ "GenSigSendType" SG_ 2651930712 Digit_01_MCPA 1;
BA_ "GenSigTimeoutTime_AGSM" SG_ 2651930712 Digit_01_MCPA 0;
BA_ "GenSigTimeoutTime_BSM" SG_ 2651930712 Digit_01_MCPA 0;
BA_ "GenSigTimeoutTime_CADM" SG_ 2651930712 Digit_01_MCPA 0;
BA_ "GenSigTimeoutTime_DMSM" SG_ 2651930712 Digit_01_MCPA 0;
BA_ "GenSigTimeoutTime_DTCM" SG_ 2651930712 Digit_01_MCPA 0;
BA_ "GenSigTimeoutTime_ECM" SG_ 2651930712 Digit_01_MCPA 0;
BA_ "GenSigTimeoutTime_EVCU2" SG_ 2651930712 Digit_01_MCPA 0;
BA_ "GenSigTimeoutTime_GNMM" SG_ 2651930712 Digit_01_MCPA 0;
BA_ "GenSigTimeoutTime_HCP" SG_ 2651930712 Digit_01_MCPA 0;
BA_ "GenSigTimeoutTime_IPC" SG_ 2651930712 Digit_01_MCPA 0;
BA_ "GenSigTimeoutTime_RFHM" SG_ 2651930712 Digit_01_MCPA 0;
BA_ "GenSigTimeoutTime_SGW" SG_ 2651930712 Digit_01_MCPA 0;
BA_ "GenSigTimeoutTime_TCM" SG_ 2651930712 Digit_01_MCPA 0;
BA_ "GenSigTimeoutTime_AGSM" SG_ 2651930712 Digit_02_MCPA 0;
BA_ "GenSigTimeoutTime_BSM" SG_ 2651930712 Digit_02_MCPA 0;
BA_ "GenSigTimeoutTime_CADM" SG_ 2651930712 Digit_02_MCPA 0;
BA_ "GenSigTimeoutTime_DMSM" SG_ 2651930712 Digit_02_MCPA 0;
BA_ "GenSigTimeoutTime_DTCM" SG_ 2651930712 Digit_02_MCPA 0;
BA_ "GenSigTimeoutTime_ECM" SG_ 2651930712 Digit_02_MCPA 0;
BA_ "GenSigTimeoutTime_EVCU2" SG_ 2651930712 Digit_02_MCPA 0;
BA_ "GenSigTimeoutTime_GNMM" SG_ 2651930712 Digit_02_MCPA 0;
BA_ "GenSigTimeoutTime_HCP" SG_ 2651930712 Digit_02_MCPA 0;
BA_ "GenSigTimeoutTime_IPC" SG_ 2651930712 Digit_02_MCPA 0;
BA_ "GenSigTimeoutTime_RFHM" SG_ 2651930712 Digit_02_MCPA 0;
BA_ "GenSigTimeoutTime_SGW" SG_ 2651930712 Digit_02_MCPA 0;
BA_ "GenSigTimeoutTime_TCM" SG_ 2651930712 Digit_02_MCPA 0;
BA_ "GenSigTimeoutTime_AGSM" SG_ 2651930712 Digit_03_MCPA 0;
BA_ "GenSigTimeoutTime_BSM" SG_ 2651930712 Digit_03_MCPA 0;
BA_ "GenSigTimeoutTime_CADM" SG_ 2651930712 Digit_03_MCPA 0;
BA_ "GenSigTimeoutTime_DMSM" SG_ 2651930712 Digit_03_MCPA 0;
BA_ "GenSigTimeoutTime_DTCM" SG_ 2651930712 Digit_03_MCPA 0;
BA_ "GenSigTimeoutTime_ECM" SG_ 2651930712 Digit_03_MCPA 0;
BA_ "GenSigTimeoutTime_EVCU2" SG_ 2651930712 Digit_03_MCPA 0;
BA_ "GenSigTimeoutTime_GNMM" SG_ 2651930712 Digit_03_MCPA 0;
BA_ "GenSigTimeoutTime_HCP" SG_ 2651930712 Digit_03_MCPA 0;
BA_ "GenSigTimeoutTime_IPC" SG_ 2651930712 Digit_03_MCPA 0;
BA_ "GenSigTimeoutTime_RFHM" SG_ 2651930712 Digit_03_MCPA 0;
BA_ "GenSigTimeoutTime_SGW" SG_ 2651930712 Digit_03_MCPA 0;
BA_ "GenSigTimeoutTime_TCM" SG_ 2651930712 Digit_03_MCPA 0;
BA_ "GenSigTimeoutTime_AGSM" SG_ 2651930712 Digit_04_MCPA 0;
BA_ "GenSigTimeoutTime_BSM" SG_ 2651930712 Digit_04_MCPA 0;
BA_ "GenSigTimeoutTime_CADM" SG_ 2651930712 Digit_04_MCPA 0;
BA_ "GenSigTimeoutTime_DMSM" SG_ 2651930712 Digit_04_MCPA 0;
BA_ "GenSigTimeoutTime_DTCM" SG_ 2651930712 Digit_04_MCPA 0;
BA_ "GenSigTimeoutTime_ECM" SG_ 2651930712 Digit_04_MCPA 0;
BA_ "GenSigTimeoutTime_EVCU2" SG_ 2651930712 Digit_04_MCPA 0;
BA_ "GenSigTimeoutTime_GNMM" SG_ 2651930712 Digit_04_MCPA 0;
BA_ "GenSigTimeoutTime_HCP" SG_ 2651930712 Digit_04_MCPA 0;
BA_ "GenSigTimeoutTime_IPC" SG_ 2651930712 Digit_04_MCPA 0;
BA_ "GenSigTimeoutTime_RFHM" SG_ 2651930712 Digit_04_MCPA 0;
BA_ "GenSigTimeoutTime_SGW" SG_ 2651930712 Digit_04_MCPA 0;
BA_ "GenSigTimeoutTime_TCM" SG_ 2651930712 Digit_04_MCPA 0;
BA_ "GenSigTimeoutTime_AGSM" SG_ 2651930712 Digit_05_MCPA 0;
BA_ "GenSigTimeoutTime_BSM" SG_ 2651930712 Digit_05_MCPA 0;
BA_ "GenSigTimeoutTime_CADM" SG_ 2651930712 Digit_05_MCPA 0;
BA_ "GenSigTimeoutTime_DMSM" SG_ 2651930712 Digit_05_MCPA 0;
BA_ "GenSigTimeoutTime_DTCM" SG_ 2651930712 Digit_05_MCPA 0;
BA_ "GenSigTimeoutTime_ECM" SG_ 2651930712 Digit_05_MCPA 0;
BA_ "GenSigTimeoutTime_EVCU2" SG_ 2651930712 Digit_05_MCPA 0;
BA_ "GenSigTimeoutTime_GNMM" SG_ 2651930712 Digit_05_MCPA 0;
BA_ "GenSigTimeoutTime_HCP" SG_ 2651930712 Digit_05_MCPA 0;
BA_ "GenSigTimeoutTime_IPC" SG_ 2651930712 Digit_05_MCPA 0;
BA_ "GenSigTimeoutTime_RFHM" SG_ 2651930712 Digit_05_MCPA 0;
BA_ "GenSigTimeoutTime_SGW" SG_ 2651930712 Digit_05_MCPA 0;
BA_ "GenSigTimeoutTime_TCM" SG_ 2651930712 Digit_05_MCPA 0;
BA_ "GenSigTimeoutTime_AGSM" SG_ 2651930712 Digit_06_MCPA 0;
BA_ "GenSigTimeoutTime_BSM" SG_ 2651930712 Digit_06_MCPA 0;
BA_ "GenSigTimeoutTime_CADM" SG_ 2651930712 Digit_06_MCPA 0;
BA_ "GenSigTimeoutTime_DMSM" SG_ 2651930712 Digit_06_MCPA 0;
BA_ "GenSigTimeoutTime_DTCM" SG_ 2651930712 Digit_06_MCPA 0;
BA_ "GenSigTimeoutTime_ECM" SG_ 2651930712 Digit_06_MCPA 0;
BA_ "GenSigTimeoutTime_EVCU2" SG_ 2651930712 Digit_06_MCPA 0;
BA_ "GenSigTimeoutTime_GNMM" SG_ 2651930712 Digit_06_MCPA 0;
BA_ "GenSigTimeoutTime_HCP" SG_ 2651930712 Digit_06_MCPA 0;
BA_ "GenSigTimeoutTime_IPC" SG_ 2651930712 Digit_06_MCPA 0;
BA_ "GenSigTimeoutTime_RFHM" SG_ 2651930712 Digit_06_MCPA 0;
BA_ "GenSigTimeoutTime_SGW" SG_ 2651930712 Digit_06_MCPA 0;
BA_ "GenSigTimeoutTime_TCM" SG_ 2651930712 Digit_06_MCPA 0;
BA_ "GenSigTimeoutTime_AGSM" SG_ 2651930712 Digit_07_MCPA 0;
BA_ "GenSigTimeoutTime_BSM" SG_ 2651930712 Digit_07_MCPA 0;
BA_ "GenSigTimeoutTime_CADM" SG_ 2651930712 Digit_07_MCPA 0;
BA_ "GenSigTimeoutTime_DMSM" SG_ 2651930712 Digit_07_MCPA 0;
BA_ "GenSigTimeoutTime_DTCM" SG_ 2651930712 Digit_07_MCPA 0;
BA_ "GenSigTimeoutTime_ECM" SG_ 2651930712 Digit_07_MCPA 0;
BA_ "GenSigTimeoutTime_EVCU2" SG_ 2651930712 Digit_07_MCPA 0;
BA_ "GenSigTimeoutTime_GNMM" SG_ 2651930712 Digit_07_MCPA 0;
BA_ "GenSigTimeoutTime_HCP" SG_ 2651930712 Digit_07_MCPA 0;
BA_ "GenSigTimeoutTime_IPC" SG_ 2651930712 Digit_07_MCPA 0;
BA_ "GenSigTimeoutTime_RFHM" SG_ 2651930712 Digit_07_MCPA 0;
BA_ "GenSigTimeoutTime_SGW" SG_ 2651930712 Digit_07_MCPA 0;
BA_ "GenSigTimeoutTime_TCM" SG_ 2651930712 Digit_07_MCPA 0;
BA_ "GenSigTimeoutTime_AGSM" SG_ 2651930712 Digit_08_MCPA 0;
BA_ "GenSigTimeoutTime_BSM" SG_ 2651930712 Digit_08_MCPA 0;
BA_ "GenSigTimeoutTime_CADM" SG_ 2651930712 Digit_08_MCPA 0;
BA_ "GenSigTimeoutTime_DMSM" SG_ 2651930712 Digit_08_MCPA 0;
BA_ "GenSigTimeoutTime_DTCM" SG_ 2651930712 Digit_08_MCPA 0;
BA_ "GenSigTimeoutTime_ECM" SG_ 2651930712 Digit_08_MCPA 0;
BA_ "GenSigTimeoutTime_EVCU2" SG_ 2651930712 Digit_08_MCPA 0;
BA_ "GenSigTimeoutTime_GNMM" SG_ 2651930712 Digit_08_MCPA 0;
BA_ "GenSigTimeoutTime_HCP" SG_ 2651930712 Digit_08_MCPA 0;
BA_ "GenSigTimeoutTime_IPC" SG_ 2651930712 Digit_08_MCPA 0;
BA_ "GenSigTimeoutTime_RFHM" SG_ 2651930712 Digit_08_MCPA 0;
BA_ "GenSigTimeoutTime_SGW" SG_ 2651930712 Digit_08_MCPA 0;
BA_ "GenSigTimeoutTime_TCM" SG_ 2651930712 Digit_08_MCPA 0;
BA_ "GenSigTimeoutTime_AGSM" SG_ 2651930712 Digit_09_MCPA 0;
BA_ "GenSigTimeoutTime_BSM" SG_ 2651930712 Digit_09_MCPA 0;
BA_ "GenSigTimeoutTime_CADM" SG_ 2651930712 Digit_09_MCPA 0;
BA_ "GenSigTimeoutTime_DMSM" SG_ 2651930712 Digit_09_MCPA 0;
BA_ "GenSigTimeoutTime_DTCM" SG_ 2651930712 Digit_09_MCPA 0;
BA_ "GenSigTimeoutTime_ECM" SG_ 2651930712 Digit_09_MCPA 0;
BA_ "GenSigTimeoutTime_EVCU2" SG_ 2651930712 Digit_09_MCPA 0;
BA_ "GenSigTimeoutTime_GNMM" SG_ 2651930712 Digit_09_MCPA 0;
BA_ "GenSigTimeoutTime_HCP" SG_ 2651930712 Digit_09_MCPA 0;
BA_ "GenSigTimeoutTime_IPC" SG_ 2651930712 Digit_09_MCPA 0;
BA_ "GenSigTimeoutTime_RFHM" SG_ 2651930712 Digit_09_MCPA 0;
BA_ "GenSigTimeoutTime_SGW" SG_ 2651930712 Digit_09_MCPA 0;
BA_ "GenSigTimeoutTime_TCM" SG_ 2651930712 Digit_09_MCPA 0;
BA_ "GenSigTimeoutTime_AGSM" SG_ 2651930712 Digit_10_MCPA 0;
BA_ "GenSigTimeoutTime_BSM" SG_ 2651930712 Digit_10_MCPA 0;
BA_ "GenSigTimeoutTime_CADM" SG_ 2651930712 Digit_10_MCPA 0;
BA_ "GenSigTimeoutTime_DMSM" SG_ 2651930712 Digit_10_MCPA 0;
BA_ "GenSigTimeoutTime_DTCM" SG_ 2651930712 Digit_10_MCPA 0;
BA_ "GenSigTimeoutTime_ECM" SG_ 2651930712 Digit_10_MCPA 0;
BA_ "GenSigTimeoutTime_EVCU2" SG_ 2651930712 Digit_10_MCPA 0;
BA_ "GenSigTimeoutTime_GNMM" SG_ 2651930712 Digit_10_MCPA 0;
BA_ "GenSigTimeoutTime_HCP" SG_ 2651930712 Digit_10_MCPA 0;
BA_ "GenSigTimeoutTime_IPC" SG_ 2651930712 Digit_10_MCPA 0;
BA_ "GenSigTimeoutTime_RFHM" SG_ 2651930712 Digit_10_MCPA 0;
BA_ "GenSigTimeoutTime_SGW" SG_ 2651930712 Digit_10_MCPA 0;
BA_ "GenSigTimeoutTime_TCM" SG_ 2651930712 Digit_10_MCPA 0;
BA_ "GenSigTimeoutTime_AGSM" SG_ 2651930712 Digit_11_MCPA 0;
BA_ "GenSigTimeoutTime_BSM" SG_ 2651930712 Digit_11_MCPA 0;
BA_ "GenSigTimeoutTime_CADM" SG_ 2651930712 Digit_11_MCPA 0;
BA_ "GenSigTimeoutTime_DMSM" SG_ 2651930712 Digit_11_MCPA 0;
BA_ "GenSigTimeoutTime_DTCM" SG_ 2651930712 Digit_11_MCPA 0;
BA_ "GenSigTimeoutTime_ECM" SG_ 2651930712 Digit_11_MCPA 0;
BA_ "GenSigTimeoutTime_EVCU2" SG_ 2651930712 Digit_11_MCPA 0;
BA_ "GenSigTimeoutTime_GNMM" SG_ 2651930712 Digit_11_MCPA 0;
BA_ "GenSigTimeoutTime_HCP" SG_ 2651930712 Digit_11_MCPA 0;
BA_ "GenSigTimeoutTime_IPC" SG_ 2651930712 Digit_11_MCPA 0;
BA_ "GenSigTimeoutTime_RFHM" SG_ 2651930712 Digit_11_MCPA 0;
BA_ "GenSigTimeoutTime_SGW" SG_ 2651930712 Digit_11_MCPA 0;
BA_ "GenSigTimeoutTime_TCM" SG_ 2651930712 Digit_11_MCPA 0;
BA_ "GenSigSendType" SG_ 2651930713 Digit_01_MCPB 1;
BA_ "GenSigTimeoutTime_AGSM" SG_ 2651930713 Digit_01_MCPB 0;
BA_ "GenSigTimeoutTime_BSM" SG_ 2651930713 Digit_01_MCPB 0;
BA_ "GenSigTimeoutTime_CADM" SG_ 2651930713 Digit_01_MCPB 0;
BA_ "GenSigTimeoutTime_DMSM" SG_ 2651930713 Digit_01_MCPB 0;
BA_ "GenSigTimeoutTime_DTCM" SG_ 2651930713 Digit_01_MCPB 0;
BA_ "GenSigTimeoutTime_ECM" SG_ 2651930713 Digit_01_MCPB 0;
BA_ "GenSigTimeoutTime_EVCU2" SG_ 2651930713 Digit_01_MCPB 0;
BA_ "GenSigTimeoutTime_GNMM" SG_ 2651930713 Digit_01_MCPB 0;
BA_ "GenSigTimeoutTime_HCP" SG_ 2651930713 Digit_01_MCPB 0;
BA_ "GenSigTimeoutTime_IPC" SG_ 2651930713 Digit_01_MCPB 0;
BA_ "GenSigTimeoutTime_RFHM" SG_ 2651930713 Digit_01_MCPB 0;
BA_ "GenSigTimeoutTime_SGW" SG_ 2651930713 Digit_01_MCPB 0;
BA_ "GenSigTimeoutTime_TCM" SG_ 2651930713 Digit_01_MCPB 0;
BA_ "GenSigTimeoutTime_AGSM" SG_ 2651930713 Digit_02_MCPB 0;
BA_ "GenSigTimeoutTime_BSM" SG_ 2651930713 Digit_02_MCPB 0;
BA_ "GenSigTimeoutTime_CADM" SG_ 2651930713 Digit_02_MCPB 0;
BA_ "GenSigTimeoutTime_DMSM" SG_ 2651930713 Digit_02_MCPB 0;
BA_ "GenSigTimeoutTime_DTCM" SG_ 2651930713 Digit_02_MCPB 0;
BA_ "GenSigTimeoutTime_ECM" SG_ 2651930713 Digit_02_MCPB 0;
BA_ "GenSigTimeoutTime_EVCU2" SG_ 2651930713 Digit_02_MCPB 0;
BA_ "GenSigTimeoutTime_GNMM" SG_ 2651930713 Digit_02_MCPB 0;
BA_ "GenSigTimeoutTime_HCP" SG_ 2651930713 Digit_02_MCPB 0;
BA_ "GenSigTimeoutTime_IPC" SG_ 2651930713 Digit_02_MCPB 0;
BA_ "GenSigTimeoutTime_RFHM" SG_ 2651930713 Digit_02_MCPB 0;
BA_ "GenSigTimeoutTime_SGW" SG_ 2651930713 Digit_02_MCPB 0;
BA_ "GenSigTimeoutTime_TCM" SG_ 2651930713 Digit_02_MCPB 0;
BA_ "GenSigTimeoutTime_AGSM" SG_ 2651930713 Digit_03_MCPB 0;
BA_ "GenSigTimeoutTime_BSM" SG_ 2651930713 Digit_03_MCPB 0;
BA_ "GenSigTimeoutTime_CADM" SG_ 2651930713 Digit_03_MCPB 0;
BA_ "GenSigTimeoutTime_DMSM" SG_ 2651930713 Digit_03_MCPB 0;
BA_ "GenSigTimeoutTime_DTCM" SG_ 2651930713 Digit_03_MCPB 0;
BA_ "GenSigTimeoutTime_ECM" SG_ 2651930713 Digit_03_MCPB 0;
BA_ "GenSigTimeoutTime_EVCU2" SG_ 2651930713 Digit_03_MCPB 0;
BA_ "GenSigTimeoutTime_GNMM" SG_ 2651930713 Digit_03_MCPB 0;
BA_ "GenSigTimeoutTime_HCP" SG_ 2651930713 Digit_03_MCPB 0;
BA_ "GenSigTimeoutTime_IPC" SG_ 2651930713 Digit_03_MCPB 0;
BA_ "GenSigTimeoutTime_RFHM" SG_ 2651930713 Digit_03_MCPB 0;
BA_ "GenSigTimeoutTime_SGW" SG_ 2651930713 Digit_03_MCPB 0;
BA_ "GenSigTimeoutTime_TCM" SG_ 2651930713 Digit_03_MCPB 0;
BA_ "GenSigTimeoutTime_AGSM" SG_ 2651930713 Digit_04_MCPB 0;
BA_ "GenSigTimeoutTime_BSM" SG_ 2651930713 Digit_04_MCPB 0;
BA_ "GenSigTimeoutTime_CADM" SG_ 2651930713 Digit_04_MCPB 0;
BA_ "GenSigTimeoutTime_DMSM" SG_ 2651930713 Digit_04_MCPB 0;
BA_ "GenSigTimeoutTime_DTCM" SG_ 2651930713 Digit_04_MCPB 0;
BA_ "GenSigTimeoutTime_ECM" SG_ 2651930713 Digit_04_MCPB 0;
BA_ "GenSigTimeoutTime_EVCU2" SG_ 2651930713 Digit_04_MCPB 0;
BA_ "GenSigTimeoutTime_GNMM" SG_ 2651930713 Digit_04_MCPB 0;
BA_ "GenSigTimeoutTime_HCP" SG_ 2651930713 Digit_04_MCPB 0;
BA_ "GenSigTimeoutTime_IPC" SG_ 2651930713 Digit_04_MCPB 0;
BA_ "GenSigTimeoutTime_RFHM" SG_ 2651930713 Digit_04_MCPB 0;
BA_ "GenSigTimeoutTime_SGW" SG_ 2651930713 Digit_04_MCPB 0;
BA_ "GenSigTimeoutTime_TCM" SG_ 2651930713 Digit_04_MCPB 0;
BA_ "GenSigTimeoutTime_AGSM" SG_ 2651930713 Digit_05_MCPB 0;
BA_ "GenSigTimeoutTime_BSM" SG_ 2651930713 Digit_05_MCPB 0;
BA_ "GenSigTimeoutTime_CADM" SG_ 2651930713 Digit_05_MCPB 0;
BA_ "GenSigTimeoutTime_DMSM" SG_ 2651930713 Digit_05_MCPB 0;
BA_ "GenSigTimeoutTime_DTCM" SG_ 2651930713 Digit_05_MCPB 0;
BA_ "GenSigTimeoutTime_ECM" SG_ 2651930713 Digit_05_MCPB 0;
BA_ "GenSigTimeoutTime_EVCU2" SG_ 2651930713 Digit_05_MCPB 0;
BA_ "GenSigTimeoutTime_GNMM" SG_ 2651930713 Digit_05_MCPB 0;
BA_ "GenSigTimeoutTime_HCP" SG_ 2651930713 Digit_05_MCPB 0;
BA_ "GenSigTimeoutTime_IPC" SG_ 2651930713 Digit_05_MCPB 0;
BA_ "GenSigTimeoutTime_RFHM" SG_ 2651930713 Digit_05_MCPB 0;
BA_ "GenSigTimeoutTime_SGW" SG_ 2651930713 Digit_05_MCPB 0;
BA_ "GenSigTimeoutTime_TCM" SG_ 2651930713 Digit_05_MCPB 0;
BA_ "GenSigTimeoutTime_AGSM" SG_ 2651930713 Digit_06_MCPB 0;
BA_ "GenSigTimeoutTime_BSM" SG_ 2651930713 Digit_06_MCPB 0;
BA_ "GenSigTimeoutTime_CADM" SG_ 2651930713 Digit_06_MCPB 0;
BA_ "GenSigTimeoutTime_DMSM" SG_ 2651930713 Digit_06_MCPB 0;
BA_ "GenSigTimeoutTime_DTCM" SG_ 2651930713 Digit_06_MCPB 0;
BA_ "GenSigTimeoutTime_ECM" SG_ 2651930713 Digit_06_MCPB 0;
BA_ "GenSigTimeoutTime_EVCU2" SG_ 2651930713 Digit_06_MCPB 0;
BA_ "GenSigTimeoutTime_GNMM" SG_ 2651930713 Digit_06_MCPB 0;
BA_ "GenSigTimeoutTime_HCP" SG_ 2651930713 Digit_06_MCPB 0;
BA_ "GenSigTimeoutTime_IPC" SG_ 2651930713 Digit_06_MCPB 0;
BA_ "GenSigTimeoutTime_RFHM" SG_ 2651930713 Digit_06_MCPB 0;
BA_ "GenSigTimeoutTime_SGW" SG_ 2651930713 Digit_06_MCPB 0;
BA_ "GenSigTimeoutTime_TCM" SG_ 2651930713 Digit_06_MCPB 0;
BA_ "GenSigTimeoutTime_AGSM" SG_ 2651930713 Digit_07_MCPB 0;
BA_ "GenSigTimeoutTime_BSM" SG_ 2651930713 Digit_07_MCPB 0;
BA_ "GenSigTimeoutTime_CADM" SG_ 2651930713 Digit_07_MCPB 0;
BA_ "GenSigTimeoutTime_DMSM" SG_ 2651930713 Digit_07_MCPB 0;
BA_ "GenSigTimeoutTime_DTCM" SG_ 2651930713 Digit_07_MCPB 0;
BA_ "GenSigTimeoutTime_ECM" SG_ 2651930713 Digit_07_MCPB 0;
BA_ "GenSigTimeoutTime_EVCU2" SG_ 2651930713 Digit_07_MCPB 0;
BA_ "GenSigTimeoutTime_GNMM" SG_ 2651930713 Digit_07_MCPB 0;
BA_ "GenSigTimeoutTime_HCP" SG_ 2651930713 Digit_07_MCPB 0;
BA_ "GenSigTimeoutTime_IPC" SG_ 2651930713 Digit_07_MCPB 0;
BA_ "GenSigTimeoutTime_RFHM" SG_ 2651930713 Digit_07_MCPB 0;
BA_ "GenSigTimeoutTime_SGW" SG_ 2651930713 Digit_07_MCPB 0;
BA_ "GenSigTimeoutTime_TCM" SG_ 2651930713 Digit_07_MCPB 0;
BA_ "GenSigTimeoutTime_AGSM" SG_ 2651930713 Digit_08_MCPB 0;
BA_ "GenSigTimeoutTime_BSM" SG_ 2651930713 Digit_08_MCPB 0;
BA_ "GenSigTimeoutTime_CADM" SG_ 2651930713 Digit_08_MCPB 0;
BA_ "GenSigTimeoutTime_DMSM" SG_ 2651930713 Digit_08_MCPB 0;
BA_ "GenSigTimeoutTime_DTCM" SG_ 2651930713 Digit_08_MCPB 0;
BA_ "GenSigTimeoutTime_ECM" SG_ 2651930713 Digit_08_MCPB 0;
BA_ "GenSigTimeoutTime_EVCU2" SG_ 2651930713 Digit_08_MCPB 0;
BA_ "GenSigTimeoutTime_GNMM" SG_ 2651930713 Digit_08_MCPB 0;
BA_ "GenSigTimeoutTime_HCP" SG_ 2651930713 Digit_08_MCPB 0;
BA_ "GenSigTimeoutTime_IPC" SG_ 2651930713 Digit_08_MCPB 0;
BA_ "GenSigTimeoutTime_RFHM" SG_ 2651930713 Digit_08_MCPB 0;
BA_ "GenSigTimeoutTime_SGW" SG_ 2651930713 Digit_08_MCPB 0;
BA_ "GenSigTimeoutTime_TCM" SG_ 2651930713 Digit_08_MCPB 0;
BA_ "GenSigTimeoutTime_AGSM" SG_ 2651930713 Digit_09_MCPB 0;
BA_ "GenSigTimeoutTime_BSM" SG_ 2651930713 Digit_09_MCPB 0;
BA_ "GenSigTimeoutTime_CADM" SG_ 2651930713 Digit_09_MCPB 0;
BA_ "GenSigTimeoutTime_DMSM" SG_ 2651930713 Digit_09_MCPB 0;
BA_ "GenSigTimeoutTime_DTCM" SG_ 2651930713 Digit_09_MCPB 0;
BA_ "GenSigTimeoutTime_ECM" SG_ 2651930713 Digit_09_MCPB 0;
BA_ "GenSigTimeoutTime_EVCU2" SG_ 2651930713 Digit_09_MCPB 0;
BA_ "GenSigTimeoutTime_GNMM" SG_ 2651930713 Digit_09_MCPB 0;
BA_ "GenSigTimeoutTime_HCP" SG_ 2651930713 Digit_09_MCPB 0;
BA_ "GenSigTimeoutTime_IPC" SG_ 2651930713 Digit_09_MCPB 0;
BA_ "GenSigTimeoutTime_RFHM" SG_ 2651930713 Digit_09_MCPB 0;
BA_ "GenSigTimeoutTime_SGW" SG_ 2651930713 Digit_09_MCPB 0;
BA_ "GenSigTimeoutTime_TCM" SG_ 2651930713 Digit_09_MCPB 0;
BA_ "GenSigTimeoutTime_AGSM" SG_ 2651930713 Digit_10_MCPB 0;
BA_ "GenSigTimeoutTime_BSM" SG_ 2651930713 Digit_10_MCPB 0;
BA_ "GenSigTimeoutTime_CADM" SG_ 2651930713 Digit_10_MCPB 0;
BA_ "GenSigTimeoutTime_DMSM" SG_ 2651930713 Digit_10_MCPB 0;
BA_ "GenSigTimeoutTime_DTCM" SG_ 2651930713 Digit_10_MCPB 0;
BA_ "GenSigTimeoutTime_ECM" SG_ 2651930713 Digit_10_MCPB 0;
BA_ "GenSigTimeoutTime_EVCU2" SG_ 2651930713 Digit_10_MCPB 0;
BA_ "GenSigTimeoutTime_GNMM" SG_ 2651930713 Digit_10_MCPB 0;
BA_ "GenSigTimeoutTime_HCP" SG_ 2651930713 Digit_10_MCPB 0;
BA_ "GenSigTimeoutTime_IPC" SG_ 2651930713 Digit_10_MCPB 0;
BA_ "GenSigTimeoutTime_RFHM" SG_ 2651930713 Digit_10_MCPB 0;
BA_ "GenSigTimeoutTime_SGW" SG_ 2651930713 Digit_10_MCPB 0;
BA_ "GenSigTimeoutTime_TCM" SG_ 2651930713 Digit_10_MCPB 0;
BA_ "GenSigTimeoutTime_AGSM" SG_ 2651930713 Digit_11_MCPB 0;
BA_ "GenSigTimeoutTime_BSM" SG_ 2651930713 Digit_11_MCPB 0;
BA_ "GenSigTimeoutTime_CADM" SG_ 2651930713 Digit_11_MCPB 0;
BA_ "GenSigTimeoutTime_DMSM" SG_ 2651930713 Digit_11_MCPB 0;
BA_ "GenSigTimeoutTime_DTCM" SG_ 2651930713 Digit_11_MCPB 0;
BA_ "GenSigTimeoutTime_ECM" SG_ 2651930713 Digit_11_MCPB 0;
BA_ "GenSigTimeoutTime_EVCU2" SG_ 2651930713 Digit_11_MCPB 0;
BA_ "GenSigTimeoutTime_GNMM" SG_ 2651930713 Digit_11_MCPB 0;
BA_ "GenSigTimeoutTime_HCP" SG_ 2651930713 Digit_11_MCPB 0;
BA_ "GenSigTimeoutTime_IPC" SG_ 2651930713 Digit_11_MCPB 0;
BA_ "GenSigTimeoutTime_RFHM" SG_ 2651930713 Digit_11_MCPB 0;
BA_ "GenSigTimeoutTime_SGW" SG_ 2651930713 Digit_11_MCPB 0;
BA_ "GenSigTimeoutTime_TCM" SG_ 2651930713 Digit_11_MCPB 0;
BA_ "GenSigSendType" SG_ 2651930838 Digit_01_PPIM 1;
BA_ "GenSigTimeoutTime_AGSM" SG_ 2651930838 Digit_01_PPIM 0;
BA_ "GenSigTimeoutTime_BSM" SG_ 2651930838 Digit_01_PPIM 0;
BA_ "GenSigTimeoutTime_CADM" SG_ 2651930838 Digit_01_PPIM 0;
BA_ "GenSigTimeoutTime_DMSM" SG_ 2651930838 Digit_01_PPIM 0;
BA_ "GenSigTimeoutTime_DTCM" SG_ 2651930838 Digit_01_PPIM 0;
BA_ "GenSigTimeoutTime_ECM" SG_ 2651930838 Digit_01_PPIM 0;
BA_ "GenSigTimeoutTime_EVCU2" SG_ 2651930838 Digit_01_PPIM 0;
BA_ "GenSigTimeoutTime_GNMM" SG_ 2651930838 Digit_01_PPIM 0;
BA_ "GenSigTimeoutTime_HCP" SG_ 2651930838 Digit_01_PPIM 0;
BA_ "GenSigTimeoutTime_IPC" SG_ 2651930838 Digit_01_PPIM 0;
BA_ "GenSigTimeoutTime_RFHM" SG_ 2651930838 Digit_01_PPIM 0;
BA_ "GenSigTimeoutTime_SGW" SG_ 2651930838 Digit_01_PPIM 0;
BA_ "GenSigTimeoutTime_TCM" SG_ 2651930838 Digit_01_PPIM 0;
BA_ "GenSigTimeoutTime_AGSM" SG_ 2651930838 Digit_02_PPIM 0;
BA_ "GenSigTimeoutTime_BSM" SG_ 2651930838 Digit_02_PPIM 0;
BA_ "GenSigTimeoutTime_CADM" SG_ 2651930838 Digit_02_PPIM 0;
BA_ "GenSigTimeoutTime_DMSM" SG_ 2651930838 Digit_02_PPIM 0;
BA_ "GenSigTimeoutTime_DTCM" SG_ 2651930838 Digit_02_PPIM 0;
BA_ "GenSigTimeoutTime_ECM" SG_ 2651930838 Digit_02_PPIM 0;
BA_ "GenSigTimeoutTime_EVCU2" SG_ 2651930838 Digit_02_PPIM 0;
BA_ "GenSigTimeoutTime_GNMM" SG_ 2651930838 Digit_02_PPIM 0;
BA_ "GenSigTimeoutTime_HCP" SG_ 2651930838 Digit_02_PPIM 0;
BA_ "GenSigTimeoutTime_IPC" SG_ 2651930838 Digit_02_PPIM 0;
BA_ "GenSigTimeoutTime_RFHM" SG_ 2651930838 Digit_02_PPIM 0;
BA_ "GenSigTimeoutTime_SGW" SG_ 2651930838 Digit_02_PPIM 0;
BA_ "GenSigTimeoutTime_TCM" SG_ 2651930838 Digit_02_PPIM 0;
BA_ "GenSigTimeoutTime_AGSM" SG_ 2651930838 Digit_03_PPIM 0;
BA_ "GenSigTimeoutTime_BSM" SG_ 2651930838 Digit_03_PPIM 0;
BA_ "GenSigTimeoutTime_CADM" SG_ 2651930838 Digit_03_PPIM 0;
BA_ "GenSigTimeoutTime_DMSM" SG_ 2651930838 Digit_03_PPIM 0;
BA_ "GenSigTimeoutTime_DTCM" SG_ 2651930838 Digit_03_PPIM 0;
BA_ "GenSigTimeoutTime_ECM" SG_ 2651930838 Digit_03_PPIM 0;
BA_ "GenSigTimeoutTime_EVCU2" SG_ 2651930838 Digit_03_PPIM 0;
BA_ "GenSigTimeoutTime_GNMM" SG_ 2651930838 Digit_03_PPIM 0;
BA_ "GenSigTimeoutTime_HCP" SG_ 2651930838 Digit_03_PPIM 0;
BA_ "GenSigTimeoutTime_IPC" SG_ 2651930838 Digit_03_PPIM 0;
BA_ "GenSigTimeoutTime_RFHM" SG_ 2651930838 Digit_03_PPIM 0;
BA_ "GenSigTimeoutTime_SGW" SG_ 2651930838 Digit_03_PPIM 0;
BA_ "GenSigTimeoutTime_TCM" SG_ 2651930838 Digit_03_PPIM 0;
BA_ "GenSigTimeoutTime_AGSM" SG_ 2651930838 Digit_04_PPIM 0;
BA_ "GenSigTimeoutTime_BSM" SG_ 2651930838 Digit_04_PPIM 0;
BA_ "GenSigTimeoutTime_CADM" SG_ 2651930838 Digit_04_PPIM 0;
BA_ "GenSigTimeoutTime_DMSM" SG_ 2651930838 Digit_04_PPIM 0;
BA_ "GenSigTimeoutTime_DTCM" SG_ 2651930838 Digit_04_PPIM 0;
BA_ "GenSigTimeoutTime_ECM" SG_ 2651930838 Digit_04_PPIM 0;
BA_ "GenSigTimeoutTime_EVCU2" SG_ 2651930838 Digit_04_PPIM 0;
BA_ "GenSigTimeoutTime_GNMM" SG_ 2651930838 Digit_04_PPIM 0;
BA_ "GenSigTimeoutTime_HCP" SG_ 2651930838 Digit_04_PPIM 0;
BA_ "GenSigTimeoutTime_IPC" SG_ 2651930838 Digit_04_PPIM 0;
BA_ "GenSigTimeoutTime_RFHM" SG_ 2651930838 Digit_04_PPIM 0;
BA_ "GenSigTimeoutTime_SGW" SG_ 2651930838 Digit_04_PPIM 0;
BA_ "GenSigTimeoutTime_TCM" SG_ 2651930838 Digit_04_PPIM 0;
BA_ "GenSigTimeoutTime_AGSM" SG_ 2651930838 Digit_05_PPIM 0;
BA_ "GenSigTimeoutTime_BSM" SG_ 2651930838 Digit_05_PPIM 0;
BA_ "GenSigTimeoutTime_CADM" SG_ 2651930838 Digit_05_PPIM 0;
BA_ "GenSigTimeoutTime_DMSM" SG_ 2651930838 Digit_05_PPIM 0;
BA_ "GenSigTimeoutTime_DTCM" SG_ 2651930838 Digit_05_PPIM 0;
BA_ "GenSigTimeoutTime_ECM" SG_ 2651930838 Digit_05_PPIM 0;
BA_ "GenSigTimeoutTime_EVCU2" SG_ 2651930838 Digit_05_PPIM 0;
BA_ "GenSigTimeoutTime_GNMM" SG_ 2651930838 Digit_05_PPIM 0;
BA_ "GenSigTimeoutTime_HCP" SG_ 2651930838 Digit_05_PPIM 0;
BA_ "GenSigTimeoutTime_IPC" SG_ 2651930838 Digit_05_PPIM 0;
BA_ "GenSigTimeoutTime_RFHM" SG_ 2651930838 Digit_05_PPIM 0;
BA_ "GenSigTimeoutTime_SGW" SG_ 2651930838 Digit_05_PPIM 0;
BA_ "GenSigTimeoutTime_TCM" SG_ 2651930838 Digit_05_PPIM 0;
BA_ "GenSigTimeoutTime_AGSM" SG_ 2651930838 Digit_06_PPIM 0;
BA_ "GenSigTimeoutTime_BSM" SG_ 2651930838 Digit_06_PPIM 0;
BA_ "GenSigTimeoutTime_CADM" SG_ 2651930838 Digit_06_PPIM 0;
BA_ "GenSigTimeoutTime_DMSM" SG_ 2651930838 Digit_06_PPIM 0;
BA_ "GenSigTimeoutTime_DTCM" SG_ 2651930838 Digit_06_PPIM 0;
BA_ "GenSigTimeoutTime_ECM" SG_ 2651930838 Digit_06_PPIM 0;
BA_ "GenSigTimeoutTime_EVCU2" SG_ 2651930838 Digit_06_PPIM 0;
BA_ "GenSigTimeoutTime_GNMM" SG_ 2651930838 Digit_06_PPIM 0;
BA_ "GenSigTimeoutTime_HCP" SG_ 2651930838 Digit_06_PPIM 0;
BA_ "GenSigTimeoutTime_IPC" SG_ 2651930838 Digit_06_PPIM 0;
BA_ "GenSigTimeoutTime_RFHM" SG_ 2651930838 Digit_06_PPIM 0;
BA_ "GenSigTimeoutTime_SGW" SG_ 2651930838 Digit_06_PPIM 0;
BA_ "GenSigTimeoutTime_TCM" SG_ 2651930838 Digit_06_PPIM 0;
BA_ "GenSigTimeoutTime_AGSM" SG_ 2651930838 Digit_07_PPIM 0;
BA_ "GenSigTimeoutTime_BSM" SG_ 2651930838 Digit_07_PPIM 0;
BA_ "GenSigTimeoutTime_CADM" SG_ 2651930838 Digit_07_PPIM 0;
BA_ "GenSigTimeoutTime_DMSM" SG_ 2651930838 Digit_07_PPIM 0;
BA_ "GenSigTimeoutTime_DTCM" SG_ 2651930838 Digit_07_PPIM 0;
BA_ "GenSigTimeoutTime_ECM" SG_ 2651930838 Digit_07_PPIM 0;
BA_ "GenSigTimeoutTime_EVCU2" SG_ 2651930838 Digit_07_PPIM 0;
BA_ "GenSigTimeoutTime_GNMM" SG_ 2651930838 Digit_07_PPIM 0;
BA_ "GenSigTimeoutTime_HCP" SG_ 2651930838 Digit_07_PPIM 0;
BA_ "GenSigTimeoutTime_IPC" SG_ 2651930838 Digit_07_PPIM 0;
BA_ "GenSigTimeoutTime_RFHM" SG_ 2651930838 Digit_07_PPIM 0;
BA_ "GenSigTimeoutTime_SGW" SG_ 2651930838 Digit_07_PPIM 0;
BA_ "GenSigTimeoutTime_TCM" SG_ 2651930838 Digit_07_PPIM 0;
BA_ "GenSigTimeoutTime_AGSM" SG_ 2651930838 Digit_08_PPIM 0;
BA_ "GenSigTimeoutTime_BSM" SG_ 2651930838 Digit_08_PPIM 0;
BA_ "GenSigTimeoutTime_CADM" SG_ 2651930838 Digit_08_PPIM 0;
BA_ "GenSigTimeoutTime_DMSM" SG_ 2651930838 Digit_08_PPIM 0;
BA_ "GenSigTimeoutTime_DTCM" SG_ 2651930838 Digit_08_PPIM 0;
BA_ "GenSigTimeoutTime_ECM" SG_ 2651930838 Digit_08_PPIM 0;
BA_ "GenSigTimeoutTime_EVCU2" SG_ 2651930838 Digit_08_PPIM 0;
BA_ "GenSigTimeoutTime_GNMM" SG_ 2651930838 Digit_08_PPIM 0;
BA_ "GenSigTimeoutTime_HCP" SG_ 2651930838 Digit_08_PPIM 0;
BA_ "GenSigTimeoutTime_IPC" SG_ 2651930838 Digit_08_PPIM 0;
BA_ "GenSigTimeoutTime_RFHM" SG_ 2651930838 Digit_08_PPIM 0;
BA_ "GenSigTimeoutTime_SGW" SG_ 2651930838 Digit_08_PPIM 0;
BA_ "GenSigTimeoutTime_TCM" SG_ 2651930838 Digit_08_PPIM 0;
BA_ "GenSigTimeoutTime_AGSM" SG_ 2651930838 Digit_09_PPIM 0;
BA_ "GenSigTimeoutTime_BSM" SG_ 2651930838 Digit_09_PPIM 0;
BA_ "GenSigTimeoutTime_CADM" SG_ 2651930838 Digit_09_PPIM 0;
BA_ "GenSigTimeoutTime_DMSM" SG_ 2651930838 Digit_09_PPIM 0;
BA_ "GenSigTimeoutTime_DTCM" SG_ 2651930838 Digit_09_PPIM 0;
BA_ "GenSigTimeoutTime_ECM" SG_ 2651930838 Digit_09_PPIM 0;
BA_ "GenSigTimeoutTime_EVCU2" SG_ 2651930838 Digit_09_PPIM 0;
BA_ "GenSigTimeoutTime_GNMM" SG_ 2651930838 Digit_09_PPIM 0;
BA_ "GenSigTimeoutTime_HCP" SG_ 2651930838 Digit_09_PPIM 0;
BA_ "GenSigTimeoutTime_IPC" SG_ 2651930838 Digit_09_PPIM 0;
BA_ "GenSigTimeoutTime_RFHM" SG_ 2651930838 Digit_09_PPIM 0;
BA_ "GenSigTimeoutTime_SGW" SG_ 2651930838 Digit_09_PPIM 0;
BA_ "GenSigTimeoutTime_TCM" SG_ 2651930838 Digit_09_PPIM 0;
BA_ "GenSigTimeoutTime_AGSM" SG_ 2651930838 Digit_10_PPIM 0;
BA_ "GenSigTimeoutTime_BSM" SG_ 2651930838 Digit_10_PPIM 0;
BA_ "GenSigTimeoutTime_CADM" SG_ 2651930838 Digit_10_PPIM 0;
BA_ "GenSigTimeoutTime_DMSM" SG_ 2651930838 Digit_10_PPIM 0;
BA_ "GenSigTimeoutTime_DTCM" SG_ 2651930838 Digit_10_PPIM 0;
BA_ "GenSigTimeoutTime_ECM" SG_ 2651930838 Digit_10_PPIM 0;
BA_ "GenSigTimeoutTime_EVCU2" SG_ 2651930838 Digit_10_PPIM 0;
BA_ "GenSigTimeoutTime_GNMM" SG_ 2651930838 Digit_10_PPIM 0;
BA_ "GenSigTimeoutTime_HCP" SG_ 2651930838 Digit_10_PPIM 0;
BA_ "GenSigTimeoutTime_IPC" SG_ 2651930838 Digit_10_PPIM 0;
BA_ "GenSigTimeoutTime_RFHM" SG_ 2651930838 Digit_10_PPIM 0;
BA_ "GenSigTimeoutTime_SGW" SG_ 2651930838 Digit_10_PPIM 0;
BA_ "GenSigTimeoutTime_TCM" SG_ 2651930838 Digit_10_PPIM 0;
BA_ "GenSigTimeoutTime_AGSM" SG_ 2651930838 Digit_11_PPIM 0;
BA_ "GenSigTimeoutTime_BSM" SG_ 2651930838 Digit_11_PPIM 0;
BA_ "GenSigTimeoutTime_CADM" SG_ 2651930838 Digit_11_PPIM 0;
BA_ "GenSigTimeoutTime_DMSM" SG_ 2651930838 Digit_11_PPIM 0;
BA_ "GenSigTimeoutTime_DTCM" SG_ 2651930838 Digit_11_PPIM 0;
BA_ "GenSigTimeoutTime_ECM" SG_ 2651930838 Digit_11_PPIM 0;
BA_ "GenSigTimeoutTime_EVCU2" SG_ 2651930838 Digit_11_PPIM 0;
BA_ "GenSigTimeoutTime_GNMM" SG_ 2651930838 Digit_11_PPIM 0;
BA_ "GenSigTimeoutTime_HCP" SG_ 2651930838 Digit_11_PPIM 0;
BA_ "GenSigTimeoutTime_IPC" SG_ 2651930838 Digit_11_PPIM 0;
BA_ "GenSigTimeoutTime_RFHM" SG_ 2651930838 Digit_11_PPIM 0;
BA_ "GenSigTimeoutTime_SGW" SG_ 2651930838 Digit_11_PPIM 0;
BA_ "GenSigTimeoutTime_TCM" SG_ 2651930838 Digit_11_PPIM 0;
BA_ "GenSigSendType" SG_ 2651930689 Digit_01_RFHM 1;
BA_ "GenSigTimeoutTime_AGSM" SG_ 2651930689 Digit_01_RFHM 0;
BA_ "GenSigTimeoutTime_BSM" SG_ 2651930689 Digit_01_RFHM 0;
BA_ "GenSigTimeoutTime_CADM" SG_ 2651930689 Digit_01_RFHM 0;
BA_ "GenSigTimeoutTime_DMSM" SG_ 2651930689 Digit_01_RFHM 0;
BA_ "GenSigTimeoutTime_DTCM" SG_ 2651930689 Digit_01_RFHM 0;
BA_ "GenSigTimeoutTime_ECM" SG_ 2651930689 Digit_01_RFHM 0;
BA_ "GenSigTimeoutTime_EVCU2" SG_ 2651930689 Digit_01_RFHM 0;
BA_ "GenSigTimeoutTime_GNMM" SG_ 2651930689 Digit_01_RFHM 0;
BA_ "GenSigTimeoutTime_HCP" SG_ 2651930689 Digit_01_RFHM 0;
BA_ "GenSigTimeoutTime_IPC" SG_ 2651930689 Digit_01_RFHM 0;
BA_ "GenSigTimeoutTime_RFHM" SG_ 2651930689 Digit_01_RFHM 0;
BA_ "GenSigTimeoutTime_SGW" SG_ 2651930689 Digit_01_RFHM 0;
BA_ "GenSigTimeoutTime_TCM" SG_ 2651930689 Digit_01_RFHM 0;
BA_ "GenSigTimeoutTime_AGSM" SG_ 2651930689 Digit_02_RFHM 0;
BA_ "GenSigTimeoutTime_BSM" SG_ 2651930689 Digit_02_RFHM 0;
BA_ "GenSigTimeoutTime_CADM" SG_ 2651930689 Digit_02_RFHM 0;
BA_ "GenSigTimeoutTime_DMSM" SG_ 2651930689 Digit_02_RFHM 0;
BA_ "GenSigTimeoutTime_DTCM" SG_ 2651930689 Digit_02_RFHM 0;
BA_ "GenSigTimeoutTime_ECM" SG_ 2651930689 Digit_02_RFHM 0;
BA_ "GenSigTimeoutTime_EVCU2" SG_ 2651930689 Digit_02_RFHM 0;
BA_ "GenSigTimeoutTime_GNMM" SG_ 2651930689 Digit_02_RFHM 0;
BA_ "GenSigTimeoutTime_HCP" SG_ 2651930689 Digit_02_RFHM 0;
BA_ "GenSigTimeoutTime_IPC" SG_ 2651930689 Digit_02_RFHM 0;
BA_ "GenSigTimeoutTime_RFHM" SG_ 2651930689 Digit_02_RFHM 0;
BA_ "GenSigTimeoutTime_SGW" SG_ 2651930689 Digit_02_RFHM 0;
BA_ "GenSigTimeoutTime_TCM" SG_ 2651930689 Digit_02_RFHM 0;
BA_ "GenSigTimeoutTime_AGSM" SG_ 2651930689 Digit_03_RFHM 0;
BA_ "GenSigTimeoutTime_BSM" SG_ 2651930689 Digit_03_RFHM 0;
BA_ "GenSigTimeoutTime_CADM" SG_ 2651930689 Digit_03_RFHM 0;
BA_ "GenSigTimeoutTime_DMSM" SG_ 2651930689 Digit_03_RFHM 0;
BA_ "GenSigTimeoutTime_DTCM" SG_ 2651930689 Digit_03_RFHM 0;
BA_ "GenSigTimeoutTime_ECM" SG_ 2651930689 Digit_03_RFHM 0;
BA_ "GenSigTimeoutTime_EVCU2" SG_ 2651930689 Digit_03_RFHM 0;
BA_ "GenSigTimeoutTime_GNMM" SG_ 2651930689 Digit_03_RFHM 0;
BA_ "GenSigTimeoutTime_HCP" SG_ 2651930689 Digit_03_RFHM 0;
BA_ "GenSigTimeoutTime_IPC" SG_ 2651930689 Digit_03_RFHM 0;
BA_ "GenSigTimeoutTime_RFHM" SG_ 2651930689 Digit_03_RFHM 0;
BA_ "GenSigTimeoutTime_SGW" SG_ 2651930689 Digit_03_RFHM 0;
BA_ "GenSigTimeoutTime_TCM" SG_ 2651930689 Digit_03_RFHM 0;
BA_ "GenSigTimeoutTime_AGSM" SG_ 2651930689 Digit_04_RFHM 0;
BA_ "GenSigTimeoutTime_BSM" SG_ 2651930689 Digit_04_RFHM 0;
BA_ "GenSigTimeoutTime_CADM" SG_ 2651930689 Digit_04_RFHM 0;
BA_ "GenSigTimeoutTime_DMSM" SG_ 2651930689 Digit_04_RFHM 0;
BA_ "GenSigTimeoutTime_DTCM" SG_ 2651930689 Digit_04_RFHM 0;
BA_ "GenSigTimeoutTime_ECM" SG_ 2651930689 Digit_04_RFHM 0;
BA_ "GenSigTimeoutTime_EVCU2" SG_ 2651930689 Digit_04_RFHM 0;
BA_ "GenSigTimeoutTime_GNMM" SG_ 2651930689 Digit_04_RFHM 0;
BA_ "GenSigTimeoutTime_HCP" SG_ 2651930689 Digit_04_RFHM 0;
BA_ "GenSigTimeoutTime_IPC" SG_ 2651930689 Digit_04_RFHM 0;
BA_ "GenSigTimeoutTime_RFHM" SG_ 2651930689 Digit_04_RFHM 0;
BA_ "GenSigTimeoutTime_SGW" SG_ 2651930689 Digit_04_RFHM 0;
BA_ "GenSigTimeoutTime_TCM" SG_ 2651930689 Digit_04_RFHM 0;
BA_ "GenSigTimeoutTime_AGSM" SG_ 2651930689 Digit_05_RFHM 0;
BA_ "GenSigTimeoutTime_BSM" SG_ 2651930689 Digit_05_RFHM 0;
BA_ "GenSigTimeoutTime_CADM" SG_ 2651930689 Digit_05_RFHM 0;
BA_ "GenSigTimeoutTime_DMSM" SG_ 2651930689 Digit_05_RFHM 0;
BA_ "GenSigTimeoutTime_DTCM" SG_ 2651930689 Digit_05_RFHM 0;
BA_ "GenSigTimeoutTime_ECM" SG_ 2651930689 Digit_05_RFHM 0;
BA_ "GenSigTimeoutTime_EVCU2" SG_ 2651930689 Digit_05_RFHM 0;
BA_ "GenSigTimeoutTime_GNMM" SG_ 2651930689 Digit_05_RFHM 0;
BA_ "GenSigTimeoutTime_HCP" SG_ 2651930689 Digit_05_RFHM 0;
BA_ "GenSigTimeoutTime_IPC" SG_ 2651930689 Digit_05_RFHM 0;
BA_ "GenSigTimeoutTime_RFHM" SG_ 2651930689 Digit_05_RFHM 0;
BA_ "GenSigTimeoutTime_SGW" SG_ 2651930689 Digit_05_RFHM 0;
BA_ "GenSigTimeoutTime_TCM" SG_ 2651930689 Digit_05_RFHM 0;
BA_ "GenSigTimeoutTime_AGSM" SG_ 2651930689 Digit_06_RFHM 0;
BA_ "GenSigTimeoutTime_BSM" SG_ 2651930689 Digit_06_RFHM 0;
BA_ "GenSigTimeoutTime_CADM" SG_ 2651930689 Digit_06_RFHM 0;
BA_ "GenSigTimeoutTime_DMSM" SG_ 2651930689 Digit_06_RFHM 0;
BA_ "GenSigTimeoutTime_DTCM" SG_ 2651930689 Digit_06_RFHM 0;
BA_ "GenSigTimeoutTime_ECM" SG_ 2651930689 Digit_06_RFHM 0;
BA_ "GenSigTimeoutTime_EVCU2" SG_ 2651930689 Digit_06_RFHM 0;
BA_ "GenSigTimeoutTime_GNMM" SG_ 2651930689 Digit_06_RFHM 0;
BA_ "GenSigTimeoutTime_HCP" SG_ 2651930689 Digit_06_RFHM 0;
BA_ "GenSigTimeoutTime_IPC" SG_ 2651930689 Digit_06_RFHM 0;
BA_ "GenSigTimeoutTime_RFHM" SG_ 2651930689 Digit_06_RFHM 0;
BA_ "GenSigTimeoutTime_SGW" SG_ 2651930689 Digit_06_RFHM 0;
BA_ "GenSigTimeoutTime_TCM" SG_ 2651930689 Digit_06_RFHM 0;
BA_ "GenSigTimeoutTime_AGSM" SG_ 2651930689 Digit_07_RFHM 0;
BA_ "GenSigTimeoutTime_BSM" SG_ 2651930689 Digit_07_RFHM 0;
BA_ "GenSigTimeoutTime_CADM" SG_ 2651930689 Digit_07_RFHM 0;
BA_ "GenSigTimeoutTime_DMSM" SG_ 2651930689 Digit_07_RFHM 0;
BA_ "GenSigTimeoutTime_DTCM" SG_ 2651930689 Digit_07_RFHM 0;
BA_ "GenSigTimeoutTime_ECM" SG_ 2651930689 Digit_07_RFHM 0;
BA_ "GenSigTimeoutTime_EVCU2" SG_ 2651930689 Digit_07_RFHM 0;
BA_ "GenSigTimeoutTime_GNMM" SG_ 2651930689 Digit_07_RFHM 0;
BA_ "GenSigTimeoutTime_HCP" SG_ 2651930689 Digit_07_RFHM 0;
BA_ "GenSigTimeoutTime_IPC" SG_ 2651930689 Digit_07_RFHM 0;
BA_ "GenSigTimeoutTime_RFHM" SG_ 2651930689 Digit_07_RFHM 0;
BA_ "GenSigTimeoutTime_SGW" SG_ 2651930689 Digit_07_RFHM 0;
BA_ "GenSigTimeoutTime_TCM" SG_ 2651930689 Digit_07_RFHM 0;
BA_ "GenSigTimeoutTime_AGSM" SG_ 2651930689 Digit_08_RFHM 0;
BA_ "GenSigTimeoutTime_BSM" SG_ 2651930689 Digit_08_RFHM 0;
BA_ "GenSigTimeoutTime_CADM" SG_ 2651930689 Digit_08_RFHM 0;
BA_ "GenSigTimeoutTime_DMSM" SG_ 2651930689 Digit_08_RFHM 0;
BA_ "GenSigTimeoutTime_DTCM" SG_ 2651930689 Digit_08_RFHM 0;
BA_ "GenSigTimeoutTime_ECM" SG_ 2651930689 Digit_08_RFHM 0;
BA_ "GenSigTimeoutTime_EVCU2" SG_ 2651930689 Digit_08_RFHM 0;
BA_ "GenSigTimeoutTime_GNMM" SG_ 2651930689 Digit_08_RFHM 0;
BA_ "GenSigTimeoutTime_HCP" SG_ 2651930689 Digit_08_RFHM 0;
BA_ "GenSigTimeoutTime_IPC" SG_ 2651930689 Digit_08_RFHM 0;
BA_ "GenSigTimeoutTime_RFHM" SG_ 2651930689 Digit_08_RFHM 0;
BA_ "GenSigTimeoutTime_SGW" SG_ 2651930689 Digit_08_RFHM 0;
BA_ "GenSigTimeoutTime_TCM" SG_ 2651930689 Digit_08_RFHM 0;
BA_ "GenSigTimeoutTime_AGSM" SG_ 2651930689 Digit_09_RFHM 0;
BA_ "GenSigTimeoutTime_BSM" SG_ 2651930689 Digit_09_RFHM 0;
BA_ "GenSigTimeoutTime_CADM" SG_ 2651930689 Digit_09_RFHM 0;
BA_ "GenSigTimeoutTime_DMSM" SG_ 2651930689 Digit_09_RFHM 0;
BA_ "GenSigTimeoutTime_DTCM" SG_ 2651930689 Digit_09_RFHM 0;
BA_ "GenSigTimeoutTime_ECM" SG_ 2651930689 Digit_09_RFHM 0;
BA_ "GenSigTimeoutTime_EVCU2" SG_ 2651930689 Digit_09_RFHM 0;
BA_ "GenSigTimeoutTime_GNMM" SG_ 2651930689 Digit_09_RFHM 0;
BA_ "GenSigTimeoutTime_HCP" SG_ 2651930689 Digit_09_RFHM 0;
BA_ "GenSigTimeoutTime_IPC" SG_ 2651930689 Digit_09_RFHM 0;
BA_ "GenSigTimeoutTime_RFHM" SG_ 2651930689 Digit_09_RFHM 0;
BA_ "GenSigTimeoutTime_SGW" SG_ 2651930689 Digit_09_RFHM 0;
BA_ "GenSigTimeoutTime_TCM" SG_ 2651930689 Digit_09_RFHM 0;
BA_ "GenSigTimeoutTime_AGSM" SG_ 2651930689 Digit_10_RFHM 0;
BA_ "GenSigTimeoutTime_BSM" SG_ 2651930689 Digit_10_RFHM 0;
BA_ "GenSigTimeoutTime_CADM" SG_ 2651930689 Digit_10_RFHM 0;
BA_ "GenSigTimeoutTime_DMSM" SG_ 2651930689 Digit_10_RFHM 0;
BA_ "GenSigTimeoutTime_DTCM" SG_ 2651930689 Digit_10_RFHM 0;
BA_ "GenSigTimeoutTime_ECM" SG_ 2651930689 Digit_10_RFHM 0;
BA_ "GenSigTimeoutTime_EVCU2" SG_ 2651930689 Digit_10_RFHM 0;
BA_ "GenSigTimeoutTime_GNMM" SG_ 2651930689 Digit_10_RFHM 0;
BA_ "GenSigTimeoutTime_HCP" SG_ 2651930689 Digit_10_RFHM 0;
BA_ "GenSigTimeoutTime_IPC" SG_ 2651930689 Digit_10_RFHM 0;
BA_ "GenSigTimeoutTime_RFHM" SG_ 2651930689 Digit_10_RFHM 0;
BA_ "GenSigTimeoutTime_SGW" SG_ 2651930689 Digit_10_RFHM 0;
BA_ "GenSigTimeoutTime_TCM" SG_ 2651930689 Digit_10_RFHM 0;
BA_ "GenSigTimeoutTime_AGSM" SG_ 2651930689 Digit_11_RFHM 0;
BA_ "GenSigTimeoutTime_BSM" SG_ 2651930689 Digit_11_RFHM 0;
BA_ "GenSigTimeoutTime_CADM" SG_ 2651930689 Digit_11_RFHM 0;
BA_ "GenSigTimeoutTime_DMSM" SG_ 2651930689 Digit_11_RFHM 0;
BA_ "GenSigTimeoutTime_DTCM" SG_ 2651930689 Digit_11_RFHM 0;
BA_ "GenSigTimeoutTime_ECM" SG_ 2651930689 Digit_11_RFHM 0;
BA_ "GenSigTimeoutTime_EVCU2" SG_ 2651930689 Digit_11_RFHM 0;
BA_ "GenSigTimeoutTime_GNMM" SG_ 2651930689 Digit_11_RFHM 0;
BA_ "GenSigTimeoutTime_HCP" SG_ 2651930689 Digit_11_RFHM 0;
BA_ "GenSigTimeoutTime_IPC" SG_ 2651930689 Digit_11_RFHM 0;
BA_ "GenSigTimeoutTime_RFHM" SG_ 2651930689 Digit_11_RFHM 0;
BA_ "GenSigTimeoutTime_SGW" SG_ 2651930689 Digit_11_RFHM 0;
BA_ "GenSigTimeoutTime_TCM" SG_ 2651930689 Digit_11_RFHM 0;
BA_ "GenSigSendType" SG_ 2651930736 Digit_01_SGW 1;
BA_ "GenSigTimeoutTime_AGSM" SG_ 2651930736 Digit_01_SGW 0;
BA_ "GenSigTimeoutTime_BSM" SG_ 2651930736 Digit_01_SGW 0;
BA_ "GenSigTimeoutTime_CADM" SG_ 2651930736 Digit_01_SGW 0;
BA_ "GenSigTimeoutTime_DMSM" SG_ 2651930736 Digit_01_SGW 0;
BA_ "GenSigTimeoutTime_DTCM" SG_ 2651930736 Digit_01_SGW 0;
BA_ "GenSigTimeoutTime_ECM" SG_ 2651930736 Digit_01_SGW 0;
BA_ "GenSigTimeoutTime_EVCU2" SG_ 2651930736 Digit_01_SGW 0;
BA_ "GenSigTimeoutTime_GNMM" SG_ 2651930736 Digit_01_SGW 0;
BA_ "GenSigTimeoutTime_HCP" SG_ 2651930736 Digit_01_SGW 0;
BA_ "GenSigTimeoutTime_IPC" SG_ 2651930736 Digit_01_SGW 0;
BA_ "GenSigTimeoutTime_RFHM" SG_ 2651930736 Digit_01_SGW 0;
BA_ "GenSigTimeoutTime_SGW" SG_ 2651930736 Digit_01_SGW 0;
BA_ "GenSigTimeoutTime_TCM" SG_ 2651930736 Digit_01_SGW 0;
BA_ "GenSigTimeoutTime_AGSM" SG_ 2651930736 Digit_02_SGW 0;
BA_ "GenSigTimeoutTime_BSM" SG_ 2651930736 Digit_02_SGW 0;
BA_ "GenSigTimeoutTime_CADM" SG_ 2651930736 Digit_02_SGW 0;
BA_ "GenSigTimeoutTime_DMSM" SG_ 2651930736 Digit_02_SGW 0;
BA_ "GenSigTimeoutTime_DTCM" SG_ 2651930736 Digit_02_SGW 0;
BA_ "GenSigTimeoutTime_ECM" SG_ 2651930736 Digit_02_SGW 0;
BA_ "GenSigTimeoutTime_EVCU2" SG_ 2651930736 Digit_02_SGW 0;
BA_ "GenSigTimeoutTime_GNMM" SG_ 2651930736 Digit_02_SGW 0;
BA_ "GenSigTimeoutTime_HCP" SG_ 2651930736 Digit_02_SGW 0;
BA_ "GenSigTimeoutTime_IPC" SG_ 2651930736 Digit_02_SGW 0;
BA_ "GenSigTimeoutTime_RFHM" SG_ 2651930736 Digit_02_SGW 0;
BA_ "GenSigTimeoutTime_SGW" SG_ 2651930736 Digit_02_SGW 0;
BA_ "GenSigTimeoutTime_TCM" SG_ 2651930736 Digit_02_SGW 0;
BA_ "GenSigTimeoutTime_AGSM" SG_ 2651930736 Digit_03_SGW 0;
BA_ "GenSigTimeoutTime_BSM" SG_ 2651930736 Digit_03_SGW 0;
BA_ "GenSigTimeoutTime_CADM" SG_ 2651930736 Digit_03_SGW 0;
BA_ "GenSigTimeoutTime_DMSM" SG_ 2651930736 Digit_03_SGW 0;
BA_ "GenSigTimeoutTime_DTCM" SG_ 2651930736 Digit_03_SGW 0;
BA_ "GenSigTimeoutTime_ECM" SG_ 2651930736 Digit_03_SGW 0;
BA_ "GenSigTimeoutTime_EVCU2" SG_ 2651930736 Digit_03_SGW 0;
BA_ "GenSigTimeoutTime_GNMM" SG_ 2651930736 Digit_03_SGW 0;
BA_ "GenSigTimeoutTime_HCP" SG_ 2651930736 Digit_03_SGW 0;
BA_ "GenSigTimeoutTime_IPC" SG_ 2651930736 Digit_03_SGW 0;
BA_ "GenSigTimeoutTime_RFHM" SG_ 2651930736 Digit_03_SGW 0;
BA_ "GenSigTimeoutTime_SGW" SG_ 2651930736 Digit_03_SGW 0;
BA_ "GenSigTimeoutTime_TCM" SG_ 2651930736 Digit_03_SGW 0;
BA_ "GenSigTimeoutTime_AGSM" SG_ 2651930736 Digit_04_SGW 0;
BA_ "GenSigTimeoutTime_BSM" SG_ 2651930736 Digit_04_SGW 0;
BA_ "GenSigTimeoutTime_CADM" SG_ 2651930736 Digit_04_SGW 0;
BA_ "GenSigTimeoutTime_DMSM" SG_ 2651930736 Digit_04_SGW 0;
BA_ "GenSigTimeoutTime_DTCM" SG_ 2651930736 Digit_04_SGW 0;
BA_ "GenSigTimeoutTime_ECM" SG_ 2651930736 Digit_04_SGW 0;
BA_ "GenSigTimeoutTime_EVCU2" SG_ 2651930736 Digit_04_SGW 0;
BA_ "GenSigTimeoutTime_GNMM" SG_ 2651930736 Digit_04_SGW 0;
BA_ "GenSigTimeoutTime_HCP" SG_ 2651930736 Digit_04_SGW 0;
BA_ "GenSigTimeoutTime_IPC" SG_ 2651930736 Digit_04_SGW 0;
BA_ "GenSigTimeoutTime_RFHM" SG_ 2651930736 Digit_04_SGW 0;
BA_ "GenSigTimeoutTime_SGW" SG_ 2651930736 Digit_04_SGW 0;
BA_ "GenSigTimeoutTime_TCM" SG_ 2651930736 Digit_04_SGW 0;
BA_ "GenSigTimeoutTime_AGSM" SG_ 2651930736 Digit_05_SGW 0;
BA_ "GenSigTimeoutTime_BSM" SG_ 2651930736 Digit_05_SGW 0;
BA_ "GenSigTimeoutTime_CADM" SG_ 2651930736 Digit_05_SGW 0;
BA_ "GenSigTimeoutTime_DMSM" SG_ 2651930736 Digit_05_SGW 0;
BA_ "GenSigTimeoutTime_DTCM" SG_ 2651930736 Digit_05_SGW 0;
BA_ "GenSigTimeoutTime_ECM" SG_ 2651930736 Digit_05_SGW 0;
BA_ "GenSigTimeoutTime_EVCU2" SG_ 2651930736 Digit_05_SGW 0;
BA_ "GenSigTimeoutTime_GNMM" SG_ 2651930736 Digit_05_SGW 0;
BA_ "GenSigTimeoutTime_HCP" SG_ 2651930736 Digit_05_SGW 0;
BA_ "GenSigTimeoutTime_IPC" SG_ 2651930736 Digit_05_SGW 0;
BA_ "GenSigTimeoutTime_RFHM" SG_ 2651930736 Digit_05_SGW 0;
BA_ "GenSigTimeoutTime_SGW" SG_ 2651930736 Digit_05_SGW 0;
BA_ "GenSigTimeoutTime_TCM" SG_ 2651930736 Digit_05_SGW 0;
BA_ "GenSigTimeoutTime_AGSM" SG_ 2651930736 Digit_06_SGW 0;
BA_ "GenSigTimeoutTime_BSM" SG_ 2651930736 Digit_06_SGW 0;
BA_ "GenSigTimeoutTime_CADM" SG_ 2651930736 Digit_06_SGW 0;
BA_ "GenSigTimeoutTime_DMSM" SG_ 2651930736 Digit_06_SGW 0;
BA_ "GenSigTimeoutTime_DTCM" SG_ 2651930736 Digit_06_SGW 0;
BA_ "GenSigTimeoutTime_ECM" SG_ 2651930736 Digit_06_SGW 0;
BA_ "GenSigTimeoutTime_EVCU2" SG_ 2651930736 Digit_06_SGW 0;
BA_ "GenSigTimeoutTime_GNMM" SG_ 2651930736 Digit_06_SGW 0;
BA_ "GenSigTimeoutTime_HCP" SG_ 2651930736 Digit_06_SGW 0;
BA_ "GenSigTimeoutTime_IPC" SG_ 2651930736 Digit_06_SGW 0;
BA_ "GenSigTimeoutTime_RFHM" SG_ 2651930736 Digit_06_SGW 0;
BA_ "GenSigTimeoutTime_SGW" SG_ 2651930736 Digit_06_SGW 0;
BA_ "GenSigTimeoutTime_TCM" SG_ 2651930736 Digit_06_SGW 0;
BA_ "GenSigTimeoutTime_AGSM" SG_ 2651930736 Digit_07_SGW 0;
BA_ "GenSigTimeoutTime_BSM" SG_ 2651930736 Digit_07_SGW 0;
BA_ "GenSigTimeoutTime_CADM" SG_ 2651930736 Digit_07_SGW 0;
BA_ "GenSigTimeoutTime_DMSM" SG_ 2651930736 Digit_07_SGW 0;
BA_ "GenSigTimeoutTime_DTCM" SG_ 2651930736 Digit_07_SGW 0;
BA_ "GenSigTimeoutTime_ECM" SG_ 2651930736 Digit_07_SGW 0;
BA_ "GenSigTimeoutTime_EVCU2" SG_ 2651930736 Digit_07_SGW 0;
BA_ "GenSigTimeoutTime_GNMM" SG_ 2651930736 Digit_07_SGW 0;
BA_ "GenSigTimeoutTime_HCP" SG_ 2651930736 Digit_07_SGW 0;
BA_ "GenSigTimeoutTime_IPC" SG_ 2651930736 Digit_07_SGW 0;
BA_ "GenSigTimeoutTime_RFHM" SG_ 2651930736 Digit_07_SGW 0;
BA_ "GenSigTimeoutTime_SGW" SG_ 2651930736 Digit_07_SGW 0;
BA_ "GenSigTimeoutTime_TCM" SG_ 2651930736 Digit_07_SGW 0;
BA_ "GenSigTimeoutTime_AGSM" SG_ 2651930736 Digit_08_SGW 0;
BA_ "GenSigTimeoutTime_BSM" SG_ 2651930736 Digit_08_SGW 0;
BA_ "GenSigTimeoutTime_CADM" SG_ 2651930736 Digit_08_SGW 0;
BA_ "GenSigTimeoutTime_DMSM" SG_ 2651930736 Digit_08_SGW 0;
BA_ "GenSigTimeoutTime_DTCM" SG_ 2651930736 Digit_08_SGW 0;
BA_ "GenSigTimeoutTime_ECM" SG_ 2651930736 Digit_08_SGW 0;
BA_ "GenSigTimeoutTime_EVCU2" SG_ 2651930736 Digit_08_SGW 0;
BA_ "GenSigTimeoutTime_GNMM" SG_ 2651930736 Digit_08_SGW 0;
BA_ "GenSigTimeoutTime_HCP" SG_ 2651930736 Digit_08_SGW 0;
BA_ "GenSigTimeoutTime_IPC" SG_ 2651930736 Digit_08_SGW 0;
BA_ "GenSigTimeoutTime_RFHM" SG_ 2651930736 Digit_08_SGW 0;
BA_ "GenSigTimeoutTime_SGW" SG_ 2651930736 Digit_08_SGW 0;
BA_ "GenSigTimeoutTime_TCM" SG_ 2651930736 Digit_08_SGW 0;
BA_ "GenSigTimeoutTime_AGSM" SG_ 2651930736 Digit_09_SGW 0;
BA_ "GenSigTimeoutTime_BSM" SG_ 2651930736 Digit_09_SGW 0;
BA_ "GenSigTimeoutTime_CADM" SG_ 2651930736 Digit_09_SGW 0;
BA_ "GenSigTimeoutTime_DMSM" SG_ 2651930736 Digit_09_SGW 0;
BA_ "GenSigTimeoutTime_DTCM" SG_ 2651930736 Digit_09_SGW 0;
BA_ "GenSigTimeoutTime_ECM" SG_ 2651930736 Digit_09_SGW 0;
BA_ "GenSigTimeoutTime_EVCU2" SG_ 2651930736 Digit_09_SGW 0;
BA_ "GenSigTimeoutTime_GNMM" SG_ 2651930736 Digit_09_SGW 0;
BA_ "GenSigTimeoutTime_HCP" SG_ 2651930736 Digit_09_SGW 0;
BA_ "GenSigTimeoutTime_IPC" SG_ 2651930736 Digit_09_SGW 0;
BA_ "GenSigTimeoutTime_RFHM" SG_ 2651930736 Digit_09_SGW 0;
BA_ "GenSigTimeoutTime_SGW" SG_ 2651930736 Digit_09_SGW 0;
BA_ "GenSigTimeoutTime_TCM" SG_ 2651930736 Digit_09_SGW 0;
BA_ "GenSigTimeoutTime_AGSM" SG_ 2651930736 Digit_10_SGW 0;
BA_ "GenSigTimeoutTime_BSM" SG_ 2651930736 Digit_10_SGW 0;
BA_ "GenSigTimeoutTime_CADM" SG_ 2651930736 Digit_10_SGW 0;
BA_ "GenSigTimeoutTime_DMSM" SG_ 2651930736 Digit_10_SGW 0;
BA_ "GenSigTimeoutTime_DTCM" SG_ 2651930736 Digit_10_SGW 0;
BA_ "GenSigTimeoutTime_ECM" SG_ 2651930736 Digit_10_SGW 0;
BA_ "GenSigTimeoutTime_EVCU2" SG_ 2651930736 Digit_10_SGW 0;
BA_ "GenSigTimeoutTime_GNMM" SG_ 2651930736 Digit_10_SGW 0;
BA_ "GenSigTimeoutTime_HCP" SG_ 2651930736 Digit_10_SGW 0;
BA_ "GenSigTimeoutTime_IPC" SG_ 2651930736 Digit_10_SGW 0;
BA_ "GenSigTimeoutTime_RFHM" SG_ 2651930736 Digit_10_SGW 0;
BA_ "GenSigTimeoutTime_SGW" SG_ 2651930736 Digit_10_SGW 0;
BA_ "GenSigTimeoutTime_TCM" SG_ 2651930736 Digit_10_SGW 0;
BA_ "GenSigTimeoutTime_AGSM" SG_ 2651930736 Digit_11_SGW 0;
BA_ "GenSigTimeoutTime_BSM" SG_ 2651930736 Digit_11_SGW 0;
BA_ "GenSigTimeoutTime_CADM" SG_ 2651930736 Digit_11_SGW 0;
BA_ "GenSigTimeoutTime_DMSM" SG_ 2651930736 Digit_11_SGW 0;
BA_ "GenSigTimeoutTime_DTCM" SG_ 2651930736 Digit_11_SGW 0;
BA_ "GenSigTimeoutTime_ECM" SG_ 2651930736 Digit_11_SGW 0;
BA_ "GenSigTimeoutTime_EVCU2" SG_ 2651930736 Digit_11_SGW 0;
BA_ "GenSigTimeoutTime_GNMM" SG_ 2651930736 Digit_11_SGW 0;
BA_ "GenSigTimeoutTime_HCP" SG_ 2651930736 Digit_11_SGW 0;
BA_ "GenSigTimeoutTime_IPC" SG_ 2651930736 Digit_11_SGW 0;
BA_ "GenSigTimeoutTime_RFHM" SG_ 2651930736 Digit_11_SGW 0;
BA_ "GenSigTimeoutTime_SGW" SG_ 2651930736 Digit_11_SGW 0;
BA_ "GenSigTimeoutTime_TCM" SG_ 2651930736 Digit_11_SGW 0;
BA_ "GenSigSendType" SG_ 2651930659 Digit_01_TBM 1;
BA_ "GenSigTimeoutTime_AGSM" SG_ 2651930659 Digit_01_TBM 0;
BA_ "GenSigTimeoutTime_BSM" SG_ 2651930659 Digit_01_TBM 0;
BA_ "GenSigTimeoutTime_CADM" SG_ 2651930659 Digit_01_TBM 0;
BA_ "GenSigTimeoutTime_DMSM" SG_ 2651930659 Digit_01_TBM 0;
BA_ "GenSigTimeoutTime_DTCM" SG_ 2651930659 Digit_01_TBM 0;
BA_ "GenSigTimeoutTime_ECM" SG_ 2651930659 Digit_01_TBM 0;
BA_ "GenSigTimeoutTime_EVCU2" SG_ 2651930659 Digit_01_TBM 0;
BA_ "GenSigTimeoutTime_GNMM" SG_ 2651930659 Digit_01_TBM 0;
BA_ "GenSigTimeoutTime_HCP" SG_ 2651930659 Digit_01_TBM 0;
BA_ "GenSigTimeoutTime_IPC" SG_ 2651930659 Digit_01_TBM 0;
BA_ "GenSigTimeoutTime_RFHM" SG_ 2651930659 Digit_01_TBM 0;
BA_ "GenSigTimeoutTime_SGW" SG_ 2651930659 Digit_01_TBM 0;
BA_ "GenSigTimeoutTime_TCM" SG_ 2651930659 Digit_01_TBM 0;
BA_ "GenSigTimeoutTime_AGSM" SG_ 2651930659 Digit_02_TBM 0;
BA_ "GenSigTimeoutTime_BSM" SG_ 2651930659 Digit_02_TBM 0;
BA_ "GenSigTimeoutTime_CADM" SG_ 2651930659 Digit_02_TBM 0;
BA_ "GenSigTimeoutTime_DMSM" SG_ 2651930659 Digit_02_TBM 0;
BA_ "GenSigTimeoutTime_DTCM" SG_ 2651930659 Digit_02_TBM 0;
BA_ "GenSigTimeoutTime_ECM" SG_ 2651930659 Digit_02_TBM 0;
BA_ "GenSigTimeoutTime_EVCU2" SG_ 2651930659 Digit_02_TBM 0;
BA_ "GenSigTimeoutTime_GNMM" SG_ 2651930659 Digit_02_TBM 0;
BA_ "GenSigTimeoutTime_HCP" SG_ 2651930659 Digit_02_TBM 0;
BA_ "GenSigTimeoutTime_IPC" SG_ 2651930659 Digit_02_TBM 0;
BA_ "GenSigTimeoutTime_RFHM" SG_ 2651930659 Digit_02_TBM 0;
BA_ "GenSigTimeoutTime_SGW" SG_ 2651930659 Digit_02_TBM 0;
BA_ "GenSigTimeoutTime_TCM" SG_ 2651930659 Digit_02_TBM 0;
BA_ "GenSigTimeoutTime_AGSM" SG_ 2651930659 Digit_03_TBM 0;
BA_ "GenSigTimeoutTime_BSM" SG_ 2651930659 Digit_03_TBM 0;
BA_ "GenSigTimeoutTime_CADM" SG_ 2651930659 Digit_03_TBM 0;
BA_ "GenSigTimeoutTime_DMSM" SG_ 2651930659 Digit_03_TBM 0;
BA_ "GenSigTimeoutTime_DTCM" SG_ 2651930659 Digit_03_TBM 0;
BA_ "GenSigTimeoutTime_ECM" SG_ 2651930659 Digit_03_TBM 0;
BA_ "GenSigTimeoutTime_EVCU2" SG_ 2651930659 Digit_03_TBM 0;
BA_ "GenSigTimeoutTime_GNMM" SG_ 2651930659 Digit_03_TBM 0;
BA_ "GenSigTimeoutTime_HCP" SG_ 2651930659 Digit_03_TBM 0;
BA_ "GenSigTimeoutTime_IPC" SG_ 2651930659 Digit_03_TBM 0;
BA_ "GenSigTimeoutTime_RFHM" SG_ 2651930659 Digit_03_TBM 0;
BA_ "GenSigTimeoutTime_SGW" SG_ 2651930659 Digit_03_TBM 0;
BA_ "GenSigTimeoutTime_TCM" SG_ 2651930659 Digit_03_TBM 0;
BA_ "GenSigTimeoutTime_AGSM" SG_ 2651930659 Digit_04_TBM 0;
BA_ "GenSigTimeoutTime_BSM" SG_ 2651930659 Digit_04_TBM 0;
BA_ "GenSigTimeoutTime_CADM" SG_ 2651930659 Digit_04_TBM 0;
BA_ "GenSigTimeoutTime_DMSM" SG_ 2651930659 Digit_04_TBM 0;
BA_ "GenSigTimeoutTime_DTCM" SG_ 2651930659 Digit_04_TBM 0;
BA_ "GenSigTimeoutTime_ECM" SG_ 2651930659 Digit_04_TBM 0;
BA_ "GenSigTimeoutTime_EVCU2" SG_ 2651930659 Digit_04_TBM 0;
BA_ "GenSigTimeoutTime_GNMM" SG_ 2651930659 Digit_04_TBM 0;
BA_ "GenSigTimeoutTime_HCP" SG_ 2651930659 Digit_04_TBM 0;
BA_ "GenSigTimeoutTime_IPC" SG_ 2651930659 Digit_04_TBM 0;
BA_ "GenSigTimeoutTime_RFHM" SG_ 2651930659 Digit_04_TBM 0;
BA_ "GenSigTimeoutTime_SGW" SG_ 2651930659 Digit_04_TBM 0;
BA_ "GenSigTimeoutTime_TCM" SG_ 2651930659 Digit_04_TBM 0;
BA_ "GenSigTimeoutTime_AGSM" SG_ 2651930659 Digit_05_TBM 0;
BA_ "GenSigTimeoutTime_BSM" SG_ 2651930659 Digit_05_TBM 0;
BA_ "GenSigTimeoutTime_CADM" SG_ 2651930659 Digit_05_TBM 0;
BA_ "GenSigTimeoutTime_DMSM" SG_ 2651930659 Digit_05_TBM 0;
BA_ "GenSigTimeoutTime_DTCM" SG_ 2651930659 Digit_05_TBM 0;
BA_ "GenSigTimeoutTime_ECM" SG_ 2651930659 Digit_05_TBM 0;
BA_ "GenSigTimeoutTime_EVCU2" SG_ 2651930659 Digit_05_TBM 0;
BA_ "GenSigTimeoutTime_GNMM" SG_ 2651930659 Digit_05_TBM 0;
BA_ "GenSigTimeoutTime_HCP" SG_ 2651930659 Digit_05_TBM 0;
BA_ "GenSigTimeoutTime_IPC" SG_ 2651930659 Digit_05_TBM 0;
BA_ "GenSigTimeoutTime_RFHM" SG_ 2651930659 Digit_05_TBM 0;
BA_ "GenSigTimeoutTime_SGW" SG_ 2651930659 Digit_05_TBM 0;
BA_ "GenSigTimeoutTime_TCM" SG_ 2651930659 Digit_05_TBM 0;
BA_ "GenSigTimeoutTime_AGSM" SG_ 2651930659 Digit_06_TBM 0;
BA_ "GenSigTimeoutTime_BSM" SG_ 2651930659 Digit_06_TBM 0;
BA_ "GenSigTimeoutTime_CADM" SG_ 2651930659 Digit_06_TBM 0;
BA_ "GenSigTimeoutTime_DMSM" SG_ 2651930659 Digit_06_TBM 0;
BA_ "GenSigTimeoutTime_DTCM" SG_ 2651930659 Digit_06_TBM 0;
BA_ "GenSigTimeoutTime_ECM" SG_ 2651930659 Digit_06_TBM 0;
BA_ "GenSigTimeoutTime_EVCU2" SG_ 2651930659 Digit_06_TBM 0;
BA_ "GenSigTimeoutTime_GNMM" SG_ 2651930659 Digit_06_TBM 0;
BA_ "GenSigTimeoutTime_HCP" SG_ 2651930659 Digit_06_TBM 0;
BA_ "GenSigTimeoutTime_IPC" SG_ 2651930659 Digit_06_TBM 0;
BA_ "GenSigTimeoutTime_RFHM" SG_ 2651930659 Digit_06_TBM 0;
BA_ "GenSigTimeoutTime_SGW" SG_ 2651930659 Digit_06_TBM 0;
BA_ "GenSigTimeoutTime_TCM" SG_ 2651930659 Digit_06_TBM 0;
BA_ "GenSigTimeoutTime_AGSM" SG_ 2651930659 Digit_07_TBM 0;
BA_ "GenSigTimeoutTime_BSM" SG_ 2651930659 Digit_07_TBM 0;
BA_ "GenSigTimeoutTime_CADM" SG_ 2651930659 Digit_07_TBM 0;
BA_ "GenSigTimeoutTime_DMSM" SG_ 2651930659 Digit_07_TBM 0;
BA_ "GenSigTimeoutTime_DTCM" SG_ 2651930659 Digit_07_TBM 0;
BA_ "GenSigTimeoutTime_ECM" SG_ 2651930659 Digit_07_TBM 0;
BA_ "GenSigTimeoutTime_EVCU2" SG_ 2651930659 Digit_07_TBM 0;
BA_ "GenSigTimeoutTime_GNMM" SG_ 2651930659 Digit_07_TBM 0;
BA_ "GenSigTimeoutTime_HCP" SG_ 2651930659 Digit_07_TBM 0;
BA_ "GenSigTimeoutTime_IPC" SG_ 2651930659 Digit_07_TBM 0;
BA_ "GenSigTimeoutTime_RFHM" SG_ 2651930659 Digit_07_TBM 0;
BA_ "GenSigTimeoutTime_SGW" SG_ 2651930659 Digit_07_TBM 0;
BA_ "GenSigTimeoutTime_TCM" SG_ 2651930659 Digit_07_TBM 0;
BA_ "GenSigTimeoutTime_AGSM" SG_ 2651930659 Digit_08_TBM 0;
BA_ "GenSigTimeoutTime_BSM" SG_ 2651930659 Digit_08_TBM 0;
BA_ "GenSigTimeoutTime_CADM" SG_ 2651930659 Digit_08_TBM 0;
BA_ "GenSigTimeoutTime_DMSM" SG_ 2651930659 Digit_08_TBM 0;
BA_ "GenSigTimeoutTime_DTCM" SG_ 2651930659 Digit_08_TBM 0;
BA_ "GenSigTimeoutTime_ECM" SG_ 2651930659 Digit_08_TBM 0;
BA_ "GenSigTimeoutTime_EVCU2" SG_ 2651930659 Digit_08_TBM 0;
BA_ "GenSigTimeoutTime_GNMM" SG_ 2651930659 Digit_08_TBM 0;
BA_ "GenSigTimeoutTime_HCP" SG_ 2651930659 Digit_08_TBM 0;
BA_ "GenSigTimeoutTime_IPC" SG_ 2651930659 Digit_08_TBM 0;
BA_ "GenSigTimeoutTime_RFHM" SG_ 2651930659 Digit_08_TBM 0;
BA_ "GenSigTimeoutTime_SGW" SG_ 2651930659 Digit_08_TBM 0;
BA_ "GenSigTimeoutTime_TCM" SG_ 2651930659 Digit_08_TBM 0;
BA_ "GenSigTimeoutTime_AGSM" SG_ 2651930659 Digit_09_TBM 0;
BA_ "GenSigTimeoutTime_BSM" SG_ 2651930659 Digit_09_TBM 0;
BA_ "GenSigTimeoutTime_CADM" SG_ 2651930659 Digit_09_TBM 0;
BA_ "GenSigTimeoutTime_DMSM" SG_ 2651930659 Digit_09_TBM 0;
BA_ "GenSigTimeoutTime_DTCM" SG_ 2651930659 Digit_09_TBM 0;
BA_ "GenSigTimeoutTime_ECM" SG_ 2651930659 Digit_09_TBM 0;
BA_ "GenSigTimeoutTime_EVCU2" SG_ 2651930659 Digit_09_TBM 0;
BA_ "GenSigTimeoutTime_GNMM" SG_ 2651930659 Digit_09_TBM 0;
BA_ "GenSigTimeoutTime_HCP" SG_ 2651930659 Digit_09_TBM 0;
BA_ "GenSigTimeoutTime_IPC" SG_ 2651930659 Digit_09_TBM 0;
BA_ "GenSigTimeoutTime_RFHM" SG_ 2651930659 Digit_09_TBM 0;
BA_ "GenSigTimeoutTime_SGW" SG_ 2651930659 Digit_09_TBM 0;
BA_ "GenSigTimeoutTime_TCM" SG_ 2651930659 Digit_09_TBM 0;
BA_ "GenSigTimeoutTime_AGSM" SG_ 2651930659 Digit_10_TBM 0;
BA_ "GenSigTimeoutTime_BSM" SG_ 2651930659 Digit_10_TBM 0;
BA_ "GenSigTimeoutTime_CADM" SG_ 2651930659 Digit_10_TBM 0;
BA_ "GenSigTimeoutTime_DMSM" SG_ 2651930659 Digit_10_TBM 0;
BA_ "GenSigTimeoutTime_DTCM" SG_ 2651930659 Digit_10_TBM 0;
BA_ "GenSigTimeoutTime_ECM" SG_ 2651930659 Digit_10_TBM 0;
BA_ "GenSigTimeoutTime_EVCU2" SG_ 2651930659 Digit_10_TBM 0;
BA_ "GenSigTimeoutTime_GNMM" SG_ 2651930659 Digit_10_TBM 0;
BA_ "GenSigTimeoutTime_HCP" SG_ 2651930659 Digit_10_TBM 0;
BA_ "GenSigTimeoutTime_IPC" SG_ 2651930659 Digit_10_TBM 0;
BA_ "GenSigTimeoutTime_RFHM" SG_ 2651930659 Digit_10_TBM 0;
BA_ "GenSigTimeoutTime_SGW" SG_ 2651930659 Digit_10_TBM 0;
BA_ "GenSigTimeoutTime_TCM" SG_ 2651930659 Digit_10_TBM 0;
BA_ "GenSigTimeoutTime_AGSM" SG_ 2651930659 Digit_11_TBM 0;
BA_ "GenSigTimeoutTime_BSM" SG_ 2651930659 Digit_11_TBM 0;
BA_ "GenSigTimeoutTime_CADM" SG_ 2651930659 Digit_11_TBM 0;
BA_ "GenSigTimeoutTime_DMSM" SG_ 2651930659 Digit_11_TBM 0;
BA_ "GenSigTimeoutTime_DTCM" SG_ 2651930659 Digit_11_TBM 0;
BA_ "GenSigTimeoutTime_ECM" SG_ 2651930659 Digit_11_TBM 0;
BA_ "GenSigTimeoutTime_EVCU2" SG_ 2651930659 Digit_11_TBM 0;
BA_ "GenSigTimeoutTime_GNMM" SG_ 2651930659 Digit_11_TBM 0;
BA_ "GenSigTimeoutTime_HCP" SG_ 2651930659 Digit_11_TBM 0;
BA_ "GenSigTimeoutTime_IPC" SG_ 2651930659 Digit_11_TBM 0;
BA_ "GenSigTimeoutTime_RFHM" SG_ 2651930659 Digit_11_TBM 0;
BA_ "GenSigTimeoutTime_SGW" SG_ 2651930659 Digit_11_TBM 0;
BA_ "GenSigTimeoutTime_TCM" SG_ 2651930659 Digit_11_TBM 0;
BA_ "GenSigSendType" SG_ 2651930635 Digit_01_TCM 1;
BA_ "GenSigTimeoutTime_AGSM" SG_ 2651930635 Digit_01_TCM 0;
BA_ "GenSigTimeoutTime_BSM" SG_ 2651930635 Digit_01_TCM 0;
BA_ "GenSigTimeoutTime_CADM" SG_ 2651930635 Digit_01_TCM 0;
BA_ "GenSigTimeoutTime_DMSM" SG_ 2651930635 Digit_01_TCM 0;
BA_ "GenSigTimeoutTime_DTCM" SG_ 2651930635 Digit_01_TCM 0;
BA_ "GenSigTimeoutTime_ECM" SG_ 2651930635 Digit_01_TCM 0;
BA_ "GenSigTimeoutTime_EVCU2" SG_ 2651930635 Digit_01_TCM 0;
BA_ "GenSigTimeoutTime_GNMM" SG_ 2651930635 Digit_01_TCM 0;
BA_ "GenSigTimeoutTime_HCP" SG_ 2651930635 Digit_01_TCM 0;
BA_ "GenSigTimeoutTime_IPC" SG_ 2651930635 Digit_01_TCM 0;
BA_ "GenSigTimeoutTime_RFHM" SG_ 2651930635 Digit_01_TCM 0;
BA_ "GenSigTimeoutTime_SGW" SG_ 2651930635 Digit_01_TCM 0;
BA_ "GenSigTimeoutTime_TCM" SG_ 2651930635 Digit_01_TCM 0;
BA_ "GenSigTimeoutTime_AGSM" SG_ 2651930635 Digit_02_TCM 0;
BA_ "GenSigTimeoutTime_BSM" SG_ 2651930635 Digit_02_TCM 0;
BA_ "GenSigTimeoutTime_CADM" SG_ 2651930635 Digit_02_TCM 0;
BA_ "GenSigTimeoutTime_DMSM" SG_ 2651930635 Digit_02_TCM 0;
BA_ "GenSigTimeoutTime_DTCM" SG_ 2651930635 Digit_02_TCM 0;
BA_ "GenSigTimeoutTime_ECM" SG_ 2651930635 Digit_02_TCM 0;
BA_ "GenSigTimeoutTime_EVCU2" SG_ 2651930635 Digit_02_TCM 0;
BA_ "GenSigTimeoutTime_GNMM" SG_ 2651930635 Digit_02_TCM 0;
BA_ "GenSigTimeoutTime_HCP" SG_ 2651930635 Digit_02_TCM 0;
BA_ "GenSigTimeoutTime_IPC" SG_ 2651930635 Digit_02_TCM 0;
BA_ "GenSigTimeoutTime_RFHM" SG_ 2651930635 Digit_02_TCM 0;
BA_ "GenSigTimeoutTime_SGW" SG_ 2651930635 Digit_02_TCM 0;
BA_ "GenSigTimeoutTime_TCM" SG_ 2651930635 Digit_02_TCM 0;
BA_ "GenSigTimeoutTime_AGSM" SG_ 2651930635 Digit_03_TCM 0;
BA_ "GenSigTimeoutTime_BSM" SG_ 2651930635 Digit_03_TCM 0;
BA_ "GenSigTimeoutTime_CADM" SG_ 2651930635 Digit_03_TCM 0;
BA_ "GenSigTimeoutTime_DMSM" SG_ 2651930635 Digit_03_TCM 0;
BA_ "GenSigTimeoutTime_DTCM" SG_ 2651930635 Digit_03_TCM 0;
BA_ "GenSigTimeoutTime_ECM" SG_ 2651930635 Digit_03_TCM 0;
BA_ "GenSigTimeoutTime_EVCU2" SG_ 2651930635 Digit_03_TCM 0;
BA_ "GenSigTimeoutTime_GNMM" SG_ 2651930635 Digit_03_TCM 0;
BA_ "GenSigTimeoutTime_HCP" SG_ 2651930635 Digit_03_TCM 0;
BA_ "GenSigTimeoutTime_IPC" SG_ 2651930635 Digit_03_TCM 0;
BA_ "GenSigTimeoutTime_RFHM" SG_ 2651930635 Digit_03_TCM 0;
BA_ "GenSigTimeoutTime_SGW" SG_ 2651930635 Digit_03_TCM 0;
BA_ "GenSigTimeoutTime_TCM" SG_ 2651930635 Digit_03_TCM 0;
BA_ "GenSigTimeoutTime_AGSM" SG_ 2651930635 Digit_04_TCM 0;
BA_ "GenSigTimeoutTime_BSM" SG_ 2651930635 Digit_04_TCM 0;
BA_ "GenSigTimeoutTime_CADM" SG_ 2651930635 Digit_04_TCM 0;
BA_ "GenSigTimeoutTime_DMSM" SG_ 2651930635 Digit_04_TCM 0;
BA_ "GenSigTimeoutTime_DTCM" SG_ 2651930635 Digit_04_TCM 0;
BA_ "GenSigTimeoutTime_ECM" SG_ 2651930635 Digit_04_TCM 0;
BA_ "GenSigTimeoutTime_EVCU2" SG_ 2651930635 Digit_04_TCM 0;
BA_ "GenSigTimeoutTime_GNMM" SG_ 2651930635 Digit_04_TCM 0;
BA_ "GenSigTimeoutTime_HCP" SG_ 2651930635 Digit_04_TCM 0;
BA_ "GenSigTimeoutTime_IPC" SG_ 2651930635 Digit_04_TCM 0;
BA_ "GenSigTimeoutTime_RFHM" SG_ 2651930635 Digit_04_TCM 0;
BA_ "GenSigTimeoutTime_SGW" SG_ 2651930635 Digit_04_TCM 0;
BA_ "GenSigTimeoutTime_TCM" SG_ 2651930635 Digit_04_TCM 0;
BA_ "GenSigTimeoutTime_AGSM" SG_ 2651930635 Digit_05_TCM 0;
BA_ "GenSigTimeoutTime_BSM" SG_ 2651930635 Digit_05_TCM 0;
BA_ "GenSigTimeoutTime_CADM" SG_ 2651930635 Digit_05_TCM 0;
BA_ "GenSigTimeoutTime_DMSM" SG_ 2651930635 Digit_05_TCM 0;
BA_ "GenSigTimeoutTime_DTCM" SG_ 2651930635 Digit_05_TCM 0;
BA_ "GenSigTimeoutTime_ECM" SG_ 2651930635 Digit_05_TCM 0;
BA_ "GenSigTimeoutTime_EVCU2" SG_ 2651930635 Digit_05_TCM 0;
BA_ "GenSigTimeoutTime_GNMM" SG_ 2651930635 Digit_05_TCM 0;
BA_ "GenSigTimeoutTime_HCP" SG_ 2651930635 Digit_05_TCM 0;
BA_ "GenSigTimeoutTime_IPC" SG_ 2651930635 Digit_05_TCM 0;
BA_ "GenSigTimeoutTime_RFHM" SG_ 2651930635 Digit_05_TCM 0;
BA_ "GenSigTimeoutTime_SGW" SG_ 2651930635 Digit_05_TCM 0;
BA_ "GenSigTimeoutTime_TCM" SG_ 2651930635 Digit_05_TCM 0;
BA_ "GenSigTimeoutTime_AGSM" SG_ 2651930635 Digit_06_TCM 0;
BA_ "GenSigTimeoutTime_BSM" SG_ 2651930635 Digit_06_TCM 0;
BA_ "GenSigTimeoutTime_CADM" SG_ 2651930635 Digit_06_TCM 0;
BA_ "GenSigTimeoutTime_DMSM" SG_ 2651930635 Digit_06_TCM 0;
BA_ "GenSigTimeoutTime_DTCM" SG_ 2651930635 Digit_06_TCM 0;
BA_ "GenSigTimeoutTime_ECM" SG_ 2651930635 Digit_06_TCM 0;
BA_ "GenSigTimeoutTime_EVCU2" SG_ 2651930635 Digit_06_TCM 0;
BA_ "GenSigTimeoutTime_GNMM" SG_ 2651930635 Digit_06_TCM 0;
BA_ "GenSigTimeoutTime_HCP" SG_ 2651930635 Digit_06_TCM 0;
BA_ "GenSigTimeoutTime_IPC" SG_ 2651930635 Digit_06_TCM 0;
BA_ "GenSigTimeoutTime_RFHM" SG_ 2651930635 Digit_06_TCM 0;
BA_ "GenSigTimeoutTime_SGW" SG_ 2651930635 Digit_06_TCM 0;
BA_ "GenSigTimeoutTime_TCM" SG_ 2651930635 Digit_06_TCM 0;
BA_ "GenSigTimeoutTime_AGSM" SG_ 2651930635 Digit_07_TCM 0;
BA_ "GenSigTimeoutTime_BSM" SG_ 2651930635 Digit_07_TCM 0;
BA_ "GenSigTimeoutTime_CADM" SG_ 2651930635 Digit_07_TCM 0;
BA_ "GenSigTimeoutTime_DMSM" SG_ 2651930635 Digit_07_TCM 0;
BA_ "GenSigTimeoutTime_DTCM" SG_ 2651930635 Digit_07_TCM 0;
BA_ "GenSigTimeoutTime_ECM" SG_ 2651930635 Digit_07_TCM 0;
BA_ "GenSigTimeoutTime_EVCU2" SG_ 2651930635 Digit_07_TCM 0;
BA_ "GenSigTimeoutTime_GNMM" SG_ 2651930635 Digit_07_TCM 0;
BA_ "GenSigTimeoutTime_HCP" SG_ 2651930635 Digit_07_TCM 0;
BA_ "GenSigTimeoutTime_IPC" SG_ 2651930635 Digit_07_TCM 0;
BA_ "GenSigTimeoutTime_RFHM" SG_ 2651930635 Digit_07_TCM 0;
BA_ "GenSigTimeoutTime_SGW" SG_ 2651930635 Digit_07_TCM 0;
BA_ "GenSigTimeoutTime_TCM" SG_ 2651930635 Digit_07_TCM 0;
BA_ "GenSigTimeoutTime_AGSM" SG_ 2651930635 Digit_08_TCM 0;
BA_ "GenSigTimeoutTime_BSM" SG_ 2651930635 Digit_08_TCM 0;
BA_ "GenSigTimeoutTime_CADM" SG_ 2651930635 Digit_08_TCM 0;
BA_ "GenSigTimeoutTime_DMSM" SG_ 2651930635 Digit_08_TCM 0;
BA_ "GenSigTimeoutTime_DTCM" SG_ 2651930635 Digit_08_TCM 0;
BA_ "GenSigTimeoutTime_ECM" SG_ 2651930635 Digit_08_TCM 0;
BA_ "GenSigTimeoutTime_EVCU2" SG_ 2651930635 Digit_08_TCM 0;
BA_ "GenSigTimeoutTime_GNMM" SG_ 2651930635 Digit_08_TCM 0;
BA_ "GenSigTimeoutTime_HCP" SG_ 2651930635 Digit_08_TCM 0;
BA_ "GenSigTimeoutTime_IPC" SG_ 2651930635 Digit_08_TCM 0;
BA_ "GenSigTimeoutTime_RFHM" SG_ 2651930635 Digit_08_TCM 0;
BA_ "GenSigTimeoutTime_SGW" SG_ 2651930635 Digit_08_TCM 0;
BA_ "GenSigTimeoutTime_TCM" SG_ 2651930635 Digit_08_TCM 0;
BA_ "GenSigTimeoutTime_AGSM" SG_ 2651930635 Digit_09_TCM 0;
BA_ "GenSigTimeoutTime_BSM" SG_ 2651930635 Digit_09_TCM 0;
BA_ "GenSigTimeoutTime_CADM" SG_ 2651930635 Digit_09_TCM 0;
BA_ "GenSigTimeoutTime_DMSM" SG_ 2651930635 Digit_09_TCM 0;
BA_ "GenSigTimeoutTime_DTCM" SG_ 2651930635 Digit_09_TCM 0;
BA_ "GenSigTimeoutTime_ECM" SG_ 2651930635 Digit_09_TCM 0;
BA_ "GenSigTimeoutTime_EVCU2" SG_ 2651930635 Digit_09_TCM 0;
BA_ "GenSigTimeoutTime_GNMM" SG_ 2651930635 Digit_09_TCM 0;
BA_ "GenSigTimeoutTime_HCP" SG_ 2651930635 Digit_09_TCM 0;
BA_ "GenSigTimeoutTime_IPC" SG_ 2651930635 Digit_09_TCM 0;
BA_ "GenSigTimeoutTime_RFHM" SG_ 2651930635 Digit_09_TCM 0;
BA_ "GenSigTimeoutTime_SGW" SG_ 2651930635 Digit_09_TCM 0;
BA_ "GenSigTimeoutTime_TCM" SG_ 2651930635 Digit_09_TCM 0;
BA_ "GenSigTimeoutTime_AGSM" SG_ 2651930635 Digit_10_TCM 0;
BA_ "GenSigTimeoutTime_BSM" SG_ 2651930635 Digit_10_TCM 0;
BA_ "GenSigTimeoutTime_CADM" SG_ 2651930635 Digit_10_TCM 0;
BA_ "GenSigTimeoutTime_DMSM" SG_ 2651930635 Digit_10_TCM 0;
BA_ "GenSigTimeoutTime_DTCM" SG_ 2651930635 Digit_10_TCM 0;
BA_ "GenSigTimeoutTime_ECM" SG_ 2651930635 Digit_10_TCM 0;
BA_ "GenSigTimeoutTime_EVCU2" SG_ 2651930635 Digit_10_TCM 0;
BA_ "GenSigTimeoutTime_GNMM" SG_ 2651930635 Digit_10_TCM 0;
BA_ "GenSigTimeoutTime_HCP" SG_ 2651930635 Digit_10_TCM 0;
BA_ "GenSigTimeoutTime_IPC" SG_ 2651930635 Digit_10_TCM 0;
BA_ "GenSigTimeoutTime_RFHM" SG_ 2651930635 Digit_10_TCM 0;
BA_ "GenSigTimeoutTime_SGW" SG_ 2651930635 Digit_10_TCM 0;
BA_ "GenSigTimeoutTime_TCM" SG_ 2651930635 Digit_10_TCM 0;
BA_ "GenSigTimeoutTime_AGSM" SG_ 2651930635 Digit_11_TCM 0;
BA_ "GenSigTimeoutTime_BSM" SG_ 2651930635 Digit_11_TCM 0;
BA_ "GenSigTimeoutTime_CADM" SG_ 2651930635 Digit_11_TCM 0;
BA_ "GenSigTimeoutTime_DMSM" SG_ 2651930635 Digit_11_TCM 0;
BA_ "GenSigTimeoutTime_DTCM" SG_ 2651930635 Digit_11_TCM 0;
BA_ "GenSigTimeoutTime_ECM" SG_ 2651930635 Digit_11_TCM 0;
BA_ "GenSigTimeoutTime_EVCU2" SG_ 2651930635 Digit_11_TCM 0;
BA_ "GenSigTimeoutTime_GNMM" SG_ 2651930635 Digit_11_TCM 0;
BA_ "GenSigTimeoutTime_HCP" SG_ 2651930635 Digit_11_TCM 0;
BA_ "GenSigTimeoutTime_IPC" SG_ 2651930635 Digit_11_TCM 0;
BA_ "GenSigTimeoutTime_RFHM" SG_ 2651930635 Digit_11_TCM 0;
BA_ "GenSigTimeoutTime_SGW" SG_ 2651930635 Digit_11_TCM 0;
BA_ "GenSigTimeoutTime_TCM" SG_ 2651930635 Digit_11_TCM 0;
BA_ "GenSigSendType" SG_ 2651930751 Digit_01_VRM 1;
BA_ "GenSigTimeoutTime_AGSM" SG_ 2651930751 Digit_01_VRM 0;
BA_ "GenSigTimeoutTime_BSM" SG_ 2651930751 Digit_01_VRM 0;
BA_ "GenSigTimeoutTime_CADM" SG_ 2651930751 Digit_01_VRM 0;
BA_ "GenSigTimeoutTime_DMSM" SG_ 2651930751 Digit_01_VRM 0;
BA_ "GenSigTimeoutTime_DTCM" SG_ 2651930751 Digit_01_VRM 0;
BA_ "GenSigTimeoutTime_ECM" SG_ 2651930751 Digit_01_VRM 0;
BA_ "GenSigTimeoutTime_EVCU2" SG_ 2651930751 Digit_01_VRM 0;
BA_ "GenSigTimeoutTime_GNMM" SG_ 2651930751 Digit_01_VRM 0;
BA_ "GenSigTimeoutTime_HCP" SG_ 2651930751 Digit_01_VRM 0;
BA_ "GenSigTimeoutTime_IPC" SG_ 2651930751 Digit_01_VRM 0;
BA_ "GenSigTimeoutTime_RFHM" SG_ 2651930751 Digit_01_VRM 0;
BA_ "GenSigTimeoutTime_SGW" SG_ 2651930751 Digit_01_VRM 0;
BA_ "GenSigTimeoutTime_TCM" SG_ 2651930751 Digit_01_VRM 0;
BA_ "GenSigTimeoutTime_AGSM" SG_ 2651930751 Digit_02_VRM 0;
BA_ "GenSigTimeoutTime_BSM" SG_ 2651930751 Digit_02_VRM 0;
BA_ "GenSigTimeoutTime_CADM" SG_ 2651930751 Digit_02_VRM 0;
BA_ "GenSigTimeoutTime_DMSM" SG_ 2651930751 Digit_02_VRM 0;
BA_ "GenSigTimeoutTime_DTCM" SG_ 2651930751 Digit_02_VRM 0;
BA_ "GenSigTimeoutTime_ECM" SG_ 2651930751 Digit_02_VRM 0;
BA_ "GenSigTimeoutTime_EVCU2" SG_ 2651930751 Digit_02_VRM 0;
BA_ "GenSigTimeoutTime_GNMM" SG_ 2651930751 Digit_02_VRM 0;
BA_ "GenSigTimeoutTime_HCP" SG_ 2651930751 Digit_02_VRM 0;
BA_ "GenSigTimeoutTime_IPC" SG_ 2651930751 Digit_02_VRM 0;
BA_ "GenSigTimeoutTime_RFHM" SG_ 2651930751 Digit_02_VRM 0;
BA_ "GenSigTimeoutTime_SGW" SG_ 2651930751 Digit_02_VRM 0;
BA_ "GenSigTimeoutTime_TCM" SG_ 2651930751 Digit_02_VRM 0;
BA_ "GenSigTimeoutTime_AGSM" SG_ 2651930751 Digit_03_VRM 0;
BA_ "GenSigTimeoutTime_BSM" SG_ 2651930751 Digit_03_VRM 0;
BA_ "GenSigTimeoutTime_CADM" SG_ 2651930751 Digit_03_VRM 0;
BA_ "GenSigTimeoutTime_DMSM" SG_ 2651930751 Digit_03_VRM 0;
BA_ "GenSigTimeoutTime_DTCM" SG_ 2651930751 Digit_03_VRM 0;
BA_ "GenSigTimeoutTime_ECM" SG_ 2651930751 Digit_03_VRM 0;
BA_ "GenSigTimeoutTime_EVCU2" SG_ 2651930751 Digit_03_VRM 0;
BA_ "GenSigTimeoutTime_GNMM" SG_ 2651930751 Digit_03_VRM 0;
BA_ "GenSigTimeoutTime_HCP" SG_ 2651930751 Digit_03_VRM 0;
BA_ "GenSigTimeoutTime_IPC" SG_ 2651930751 Digit_03_VRM 0;
BA_ "GenSigTimeoutTime_RFHM" SG_ 2651930751 Digit_03_VRM 0;
BA_ "GenSigTimeoutTime_SGW" SG_ 2651930751 Digit_03_VRM 0;
BA_ "GenSigTimeoutTime_TCM" SG_ 2651930751 Digit_03_VRM 0;
BA_ "GenSigTimeoutTime_AGSM" SG_ 2651930751 Digit_04_VRM 0;
BA_ "GenSigTimeoutTime_BSM" SG_ 2651930751 Digit_04_VRM 0;
BA_ "GenSigTimeoutTime_CADM" SG_ 2651930751 Digit_04_VRM 0;
BA_ "GenSigTimeoutTime_DMSM" SG_ 2651930751 Digit_04_VRM 0;
BA_ "GenSigTimeoutTime_DTCM" SG_ 2651930751 Digit_04_VRM 0;
BA_ "GenSigTimeoutTime_ECM" SG_ 2651930751 Digit_04_VRM 0;
BA_ "GenSigTimeoutTime_EVCU2" SG_ 2651930751 Digit_04_VRM 0;
BA_ "GenSigTimeoutTime_GNMM" SG_ 2651930751 Digit_04_VRM 0;
BA_ "GenSigTimeoutTime_HCP" SG_ 2651930751 Digit_04_VRM 0;
BA_ "GenSigTimeoutTime_IPC" SG_ 2651930751 Digit_04_VRM 0;
BA_ "GenSigTimeoutTime_RFHM" SG_ 2651930751 Digit_04_VRM 0;
BA_ "GenSigTimeoutTime_SGW" SG_ 2651930751 Digit_04_VRM 0;
BA_ "GenSigTimeoutTime_TCM" SG_ 2651930751 Digit_04_VRM 0;
BA_ "GenSigTimeoutTime_AGSM" SG_ 2651930751 Digit_05_VRM 0;
BA_ "GenSigTimeoutTime_BSM" SG_ 2651930751 Digit_05_VRM 0;
BA_ "GenSigTimeoutTime_CADM" SG_ 2651930751 Digit_05_VRM 0;
BA_ "GenSigTimeoutTime_DMSM" SG_ 2651930751 Digit_05_VRM 0;
BA_ "GenSigTimeoutTime_DTCM" SG_ 2651930751 Digit_05_VRM 0;
BA_ "GenSigTimeoutTime_ECM" SG_ 2651930751 Digit_05_VRM 0;
BA_ "GenSigTimeoutTime_EVCU2" SG_ 2651930751 Digit_05_VRM 0;
BA_ "GenSigTimeoutTime_GNMM" SG_ 2651930751 Digit_05_VRM 0;
BA_ "GenSigTimeoutTime_HCP" SG_ 2651930751 Digit_05_VRM 0;
BA_ "GenSigTimeoutTime_IPC" SG_ 2651930751 Digit_05_VRM 0;
BA_ "GenSigTimeoutTime_RFHM" SG_ 2651930751 Digit_05_VRM 0;
BA_ "GenSigTimeoutTime_SGW" SG_ 2651930751 Digit_05_VRM 0;
BA_ "GenSigTimeoutTime_TCM" SG_ 2651930751 Digit_05_VRM 0;
BA_ "GenSigTimeoutTime_AGSM" SG_ 2651930751 Digit_06_VRM 0;
BA_ "GenSigTimeoutTime_BSM" SG_ 2651930751 Digit_06_VRM 0;
BA_ "GenSigTimeoutTime_CADM" SG_ 2651930751 Digit_06_VRM 0;
BA_ "GenSigTimeoutTime_DMSM" SG_ 2651930751 Digit_06_VRM 0;
BA_ "GenSigTimeoutTime_DTCM" SG_ 2651930751 Digit_06_VRM 0;
BA_ "GenSigTimeoutTime_ECM" SG_ 2651930751 Digit_06_VRM 0;
BA_ "GenSigTimeoutTime_EVCU2" SG_ 2651930751 Digit_06_VRM 0;
BA_ "GenSigTimeoutTime_GNMM" SG_ 2651930751 Digit_06_VRM 0;
BA_ "GenSigTimeoutTime_HCP" SG_ 2651930751 Digit_06_VRM 0;
BA_ "GenSigTimeoutTime_IPC" SG_ 2651930751 Digit_06_VRM 0;
BA_ "GenSigTimeoutTime_RFHM" SG_ 2651930751 Digit_06_VRM 0;
BA_ "GenSigTimeoutTime_SGW" SG_ 2651930751 Digit_06_VRM 0;
BA_ "GenSigTimeoutTime_TCM" SG_ 2651930751 Digit_06_VRM 0;
BA_ "GenSigTimeoutTime_AGSM" SG_ 2651930751 Digit_07_VRM 0;
BA_ "GenSigTimeoutTime_BSM" SG_ 2651930751 Digit_07_VRM 0;
BA_ "GenSigTimeoutTime_CADM" SG_ 2651930751 Digit_07_VRM 0;
BA_ "GenSigTimeoutTime_DMSM" SG_ 2651930751 Digit_07_VRM 0;
BA_ "GenSigTimeoutTime_DTCM" SG_ 2651930751 Digit_07_VRM 0;
BA_ "GenSigTimeoutTime_ECM" SG_ 2651930751 Digit_07_VRM 0;
BA_ "GenSigTimeoutTime_EVCU2" SG_ 2651930751 Digit_07_VRM 0;
BA_ "GenSigTimeoutTime_GNMM" SG_ 2651930751 Digit_07_VRM 0;
BA_ "GenSigTimeoutTime_HCP" SG_ 2651930751 Digit_07_VRM 0;
BA_ "GenSigTimeoutTime_IPC" SG_ 2651930751 Digit_07_VRM 0;
BA_ "GenSigTimeoutTime_RFHM" SG_ 2651930751 Digit_07_VRM 0;
BA_ "GenSigTimeoutTime_SGW" SG_ 2651930751 Digit_07_VRM 0;
BA_ "GenSigTimeoutTime_TCM" SG_ 2651930751 Digit_07_VRM 0;
BA_ "GenSigTimeoutTime_AGSM" SG_ 2651930751 Digit_08_VRM 0;
BA_ "GenSigTimeoutTime_BSM" SG_ 2651930751 Digit_08_VRM 0;
BA_ "GenSigTimeoutTime_CADM" SG_ 2651930751 Digit_08_VRM 0;
BA_ "GenSigTimeoutTime_DMSM" SG_ 2651930751 Digit_08_VRM 0;
BA_ "GenSigTimeoutTime_DTCM" SG_ 2651930751 Digit_08_VRM 0;
BA_ "GenSigTimeoutTime_ECM" SG_ 2651930751 Digit_08_VRM 0;
BA_ "GenSigTimeoutTime_EVCU2" SG_ 2651930751 Digit_08_VRM 0;
BA_ "GenSigTimeoutTime_GNMM" SG_ 2651930751 Digit_08_VRM 0;
BA_ "GenSigTimeoutTime_HCP" SG_ 2651930751 Digit_08_VRM 0;
BA_ "GenSigTimeoutTime_IPC" SG_ 2651930751 Digit_08_VRM 0;
BA_ "GenSigTimeoutTime_RFHM" SG_ 2651930751 Digit_08_VRM 0;
BA_ "GenSigTimeoutTime_SGW" SG_ 2651930751 Digit_08_VRM 0;
BA_ "GenSigTimeoutTime_TCM" SG_ 2651930751 Digit_08_VRM 0;
BA_ "GenSigTimeoutTime_AGSM" SG_ 2651930751 Digit_09_VRM 0;
BA_ "GenSigTimeoutTime_BSM" SG_ 2651930751 Digit_09_VRM 0;
BA_ "GenSigTimeoutTime_CADM" SG_ 2651930751 Digit_09_VRM 0;
BA_ "GenSigTimeoutTime_DMSM" SG_ 2651930751 Digit_09_VRM 0;
BA_ "GenSigTimeoutTime_DTCM" SG_ 2651930751 Digit_09_VRM 0;
BA_ "GenSigTimeoutTime_ECM" SG_ 2651930751 Digit_09_VRM 0;
BA_ "GenSigTimeoutTime_EVCU2" SG_ 2651930751 Digit_09_VRM 0;
BA_ "GenSigTimeoutTime_GNMM" SG_ 2651930751 Digit_09_VRM 0;
BA_ "GenSigTimeoutTime_HCP" SG_ 2651930751 Digit_09_VRM 0;
BA_ "GenSigTimeoutTime_IPC" SG_ 2651930751 Digit_09_VRM 0;
BA_ "GenSigTimeoutTime_RFHM" SG_ 2651930751 Digit_09_VRM 0;
BA_ "GenSigTimeoutTime_SGW" SG_ 2651930751 Digit_09_VRM 0;
BA_ "GenSigTimeoutTime_TCM" SG_ 2651930751 Digit_09_VRM 0;
BA_ "GenSigTimeoutTime_AGSM" SG_ 2651930751 Digit_10_VRM 0;
BA_ "GenSigTimeoutTime_BSM" SG_ 2651930751 Digit_10_VRM 0;
BA_ "GenSigTimeoutTime_CADM" SG_ 2651930751 Digit_10_VRM 0;
BA_ "GenSigTimeoutTime_DMSM" SG_ 2651930751 Digit_10_VRM 0;
BA_ "GenSigTimeoutTime_DTCM" SG_ 2651930751 Digit_10_VRM 0;
BA_ "GenSigTimeoutTime_ECM" SG_ 2651930751 Digit_10_VRM 0;
BA_ "GenSigTimeoutTime_EVCU2" SG_ 2651930751 Digit_10_VRM 0;
BA_ "GenSigTimeoutTime_GNMM" SG_ 2651930751 Digit_10_VRM 0;
BA_ "GenSigTimeoutTime_HCP" SG_ 2651930751 Digit_10_VRM 0;
BA_ "GenSigTimeoutTime_IPC" SG_ 2651930751 Digit_10_VRM 0;
BA_ "GenSigTimeoutTime_RFHM" SG_ 2651930751 Digit_10_VRM 0;
BA_ "GenSigTimeoutTime_SGW" SG_ 2651930751 Digit_10_VRM 0;
BA_ "GenSigTimeoutTime_TCM" SG_ 2651930751 Digit_10_VRM 0;
BA_ "GenSigTimeoutTime_AGSM" SG_ 2651930751 Digit_11_VRM 0;
BA_ "GenSigTimeoutTime_BSM" SG_ 2651930751 Digit_11_VRM 0;
BA_ "GenSigTimeoutTime_CADM" SG_ 2651930751 Digit_11_VRM 0;
BA_ "GenSigTimeoutTime_DMSM" SG_ 2651930751 Digit_11_VRM 0;
BA_ "GenSigTimeoutTime_DTCM" SG_ 2651930751 Digit_11_VRM 0;
BA_ "GenSigTimeoutTime_ECM" SG_ 2651930751 Digit_11_VRM 0;
BA_ "GenSigTimeoutTime_EVCU2" SG_ 2651930751 Digit_11_VRM 0;
BA_ "GenSigTimeoutTime_GNMM" SG_ 2651930751 Digit_11_VRM 0;
BA_ "GenSigTimeoutTime_HCP" SG_ 2651930751 Digit_11_VRM 0;
BA_ "GenSigTimeoutTime_IPC" SG_ 2651930751 Digit_11_VRM 0;
BA_ "GenSigTimeoutTime_RFHM" SG_ 2651930751 Digit_11_VRM 0;
BA_ "GenSigTimeoutTime_SGW" SG_ 2651930751 Digit_11_VRM 0;
BA_ "GenSigTimeoutTime_TCM" SG_ 2651930751 Digit_11_VRM 0;
BA_ "GenSigSendType" SG_ 1457 Charge_Schedule_Type1_Sts 3;
BA_ "GenSigTimeoutTime_AGSM" SG_ 1457 Charge_Schedule_Type1_Sts 0;
BA_ "GenSigTimeoutTime_BCM" SG_ 1457 Charge_Schedule_Type1_Sts 0;
BA_ "GenSigTimeoutTime_BSM" SG_ 1457 Charge_Schedule_Type1_Sts 0;
BA_ "GenSigTimeoutTime_CADM" SG_ 1457 Charge_Schedule_Type1_Sts 0;
BA_ "GenSigTimeoutTime_DMSM" SG_ 1457 Charge_Schedule_Type1_Sts 0;
BA_ "GenSigTimeoutTime_DTCM" SG_ 1457 Charge_Schedule_Type1_Sts 0;
BA_ "GenSigTimeoutTime_ECM" SG_ 1457 Charge_Schedule_Type1_Sts 0;
BA_ "GenSigTimeoutTime_EVCU2" SG_ 1457 Charge_Schedule_Type1_Sts 0;
BA_ "GenSigTimeoutTime_GNMM" SG_ 1457 Charge_Schedule_Type1_Sts 0;
BA_ "GenSigTimeoutTime_HCP" SG_ 1457 Charge_Schedule_Type1_Sts 0;
BA_ "GenSigTimeoutTime_IPC" SG_ 1457 Charge_Schedule_Type1_Sts 0;
BA_ "GenSigTimeoutTime_RFHM" SG_ 1457 Charge_Schedule_Type1_Sts 0;
BA_ "GenSigTimeoutTime_TCM" SG_ 1457 Charge_Schedule_Type1_Sts 0;
BA_ "GenSigSendType" SG_ 1457 Charge_Schedule_Type2_Sts 3;
BA_ "GenSigTimeoutTime_AGSM" SG_ 1457 Charge_Schedule_Type2_Sts 0;
BA_ "GenSigTimeoutTime_BCM" SG_ 1457 Charge_Schedule_Type2_Sts 0;
BA_ "GenSigTimeoutTime_BSM" SG_ 1457 Charge_Schedule_Type2_Sts 0;
BA_ "GenSigTimeoutTime_CADM" SG_ 1457 Charge_Schedule_Type2_Sts 0;
BA_ "GenSigTimeoutTime_DMSM" SG_ 1457 Charge_Schedule_Type2_Sts 0;
BA_ "GenSigTimeoutTime_DTCM" SG_ 1457 Charge_Schedule_Type2_Sts 0;
BA_ "GenSigTimeoutTime_ECM" SG_ 1457 Charge_Schedule_Type2_Sts 0;
BA_ "GenSigTimeoutTime_EVCU2" SG_ 1457 Charge_Schedule_Type2_Sts 0;
BA_ "GenSigTimeoutTime_GNMM" SG_ 1457 Charge_Schedule_Type2_Sts 0;
BA_ "GenSigTimeoutTime_HCP" SG_ 1457 Charge_Schedule_Type2_Sts 0;
BA_ "GenSigTimeoutTime_IPC" SG_ 1457 Charge_Schedule_Type2_Sts 0;
BA_ "GenSigTimeoutTime_RFHM" SG_ 1457 Charge_Schedule_Type2_Sts 0;
BA_ "GenSigTimeoutTime_TCM" SG_ 1457 Charge_Schedule_Type2_Sts 0;
BA_ "GenSigSendType" SG_ 1457 ChargeUntilFull1_Sts 3;
BA_ "GenSigTimeoutTime_AGSM" SG_ 1457 ChargeUntilFull1_Sts 0;
BA_ "GenSigTimeoutTime_BCM" SG_ 1457 ChargeUntilFull1_Sts 0;
BA_ "GenSigTimeoutTime_BSM" SG_ 1457 ChargeUntilFull1_Sts 0;
BA_ "GenSigTimeoutTime_CADM" SG_ 1457 ChargeUntilFull1_Sts 0;
BA_ "GenSigTimeoutTime_DMSM" SG_ 1457 ChargeUntilFull1_Sts 0;
BA_ "GenSigTimeoutTime_DTCM" SG_ 1457 ChargeUntilFull1_Sts 0;
BA_ "GenSigTimeoutTime_ECM" SG_ 1457 ChargeUntilFull1_Sts 0;
BA_ "GenSigTimeoutTime_EVCU2" SG_ 1457 ChargeUntilFull1_Sts 0;
BA_ "GenSigTimeoutTime_GNMM" SG_ 1457 ChargeUntilFull1_Sts 0;
BA_ "GenSigTimeoutTime_HCP" SG_ 1457 ChargeUntilFull1_Sts 0;
BA_ "GenSigTimeoutTime_IPC" SG_ 1457 ChargeUntilFull1_Sts 0;
BA_ "GenSigTimeoutTime_RFHM" SG_ 1457 ChargeUntilFull1_Sts 0;
BA_ "GenSigTimeoutTime_TCM" SG_ 1457 ChargeUntilFull1_Sts 0;
BA_ "GenSigSendType" SG_ 1457 ChargeUntilFull2_Sts 3;
BA_ "GenSigTimeoutTime_AGSM" SG_ 1457 ChargeUntilFull2_Sts 0;
BA_ "GenSigTimeoutTime_BCM" SG_ 1457 ChargeUntilFull2_Sts 0;
BA_ "GenSigTimeoutTime_BSM" SG_ 1457 ChargeUntilFull2_Sts 0;
BA_ "GenSigTimeoutTime_CADM" SG_ 1457 ChargeUntilFull2_Sts 0;
BA_ "GenSigTimeoutTime_DMSM" SG_ 1457 ChargeUntilFull2_Sts 0;
BA_ "GenSigTimeoutTime_DTCM" SG_ 1457 ChargeUntilFull2_Sts 0;
BA_ "GenSigTimeoutTime_ECM" SG_ 1457 ChargeUntilFull2_Sts 0;
BA_ "GenSigTimeoutTime_EVCU2" SG_ 1457 ChargeUntilFull2_Sts 0;
BA_ "GenSigTimeoutTime_GNMM" SG_ 1457 ChargeUntilFull2_Sts 0;
BA_ "GenSigTimeoutTime_HCP" SG_ 1457 ChargeUntilFull2_Sts 0;
BA_ "GenSigTimeoutTime_IPC" SG_ 1457 ChargeUntilFull2_Sts 0;
BA_ "GenSigTimeoutTime_RFHM" SG_ 1457 ChargeUntilFull2_Sts 0;
BA_ "GenSigTimeoutTime_TCM" SG_ 1457 ChargeUntilFull2_Sts 0;
BA_ "GenSigSendType" SG_ 1457 End_Time_Hr1_Sts 3;
BA_ "GenSigTimeoutTime_AGSM" SG_ 1457 End_Time_Hr1_Sts 0;
BA_ "GenSigTimeoutTime_BCM" SG_ 1457 End_Time_Hr1_Sts 0;
BA_ "GenSigTimeoutTime_BSM" SG_ 1457 End_Time_Hr1_Sts 0;
BA_ "GenSigTimeoutTime_CADM" SG_ 1457 End_Time_Hr1_Sts 0;
BA_ "GenSigTimeoutTime_DMSM" SG_ 1457 End_Time_Hr1_Sts 0;
BA_ "GenSigTimeoutTime_DTCM" SG_ 1457 End_Time_Hr1_Sts 0;
BA_ "GenSigTimeoutTime_ECM" SG_ 1457 End_Time_Hr1_Sts 0;
BA_ "GenSigTimeoutTime_EVCU2" SG_ 1457 End_Time_Hr1_Sts 0;
BA_ "GenSigTimeoutTime_GNMM" SG_ 1457 End_Time_Hr1_Sts 0;
BA_ "GenSigTimeoutTime_HCP" SG_ 1457 End_Time_Hr1_Sts 0;
BA_ "GenSigTimeoutTime_IPC" SG_ 1457 End_Time_Hr1_Sts 0;
BA_ "GenSigTimeoutTime_RFHM" SG_ 1457 End_Time_Hr1_Sts 0;
BA_ "GenSigTimeoutTime_TCM" SG_ 1457 End_Time_Hr1_Sts 0;
BA_ "GenSigSendType" SG_ 1457 End_Time_Hr2_Sts 3;
BA_ "GenSigTimeoutTime_AGSM" SG_ 1457 End_Time_Hr2_Sts 0;
BA_ "GenSigTimeoutTime_BCM" SG_ 1457 End_Time_Hr2_Sts 0;
BA_ "GenSigTimeoutTime_BSM" SG_ 1457 End_Time_Hr2_Sts 0;
BA_ "GenSigTimeoutTime_CADM" SG_ 1457 End_Time_Hr2_Sts 0;
BA_ "GenSigTimeoutTime_DMSM" SG_ 1457 End_Time_Hr2_Sts 0;
BA_ "GenSigTimeoutTime_DTCM" SG_ 1457 End_Time_Hr2_Sts 0;
BA_ "GenSigTimeoutTime_ECM" SG_ 1457 End_Time_Hr2_Sts 0;
BA_ "GenSigTimeoutTime_EVCU2" SG_ 1457 End_Time_Hr2_Sts 0;
BA_ "GenSigTimeoutTime_GNMM" SG_ 1457 End_Time_Hr2_Sts 0;
BA_ "GenSigTimeoutTime_HCP" SG_ 1457 End_Time_Hr2_Sts 0;
BA_ "GenSigTimeoutTime_IPC" SG_ 1457 End_Time_Hr2_Sts 0;
BA_ "GenSigTimeoutTime_RFHM" SG_ 1457 End_Time_Hr2_Sts 0;
BA_ "GenSigTimeoutTime_TCM" SG_ 1457 End_Time_Hr2_Sts 0;
BA_ "GenSigSendType" SG_ 1457 End_Time_Min1_Sts 3;
BA_ "GenSigTimeoutTime_AGSM" SG_ 1457 End_Time_Min1_Sts 0;
BA_ "GenSigTimeoutTime_BCM" SG_ 1457 End_Time_Min1_Sts 0;
BA_ "GenSigTimeoutTime_BSM" SG_ 1457 End_Time_Min1_Sts 0;
BA_ "GenSigTimeoutTime_CADM" SG_ 1457 End_Time_Min1_Sts 0;
BA_ "GenSigTimeoutTime_DMSM" SG_ 1457 End_Time_Min1_Sts 0;
BA_ "GenSigTimeoutTime_DTCM" SG_ 1457 End_Time_Min1_Sts 0;
BA_ "GenSigTimeoutTime_ECM" SG_ 1457 End_Time_Min1_Sts 0;
BA_ "GenSigTimeoutTime_EVCU2" SG_ 1457 End_Time_Min1_Sts 0;
BA_ "GenSigTimeoutTime_GNMM" SG_ 1457 End_Time_Min1_Sts 0;
BA_ "GenSigTimeoutTime_HCP" SG_ 1457 End_Time_Min1_Sts 0;
BA_ "GenSigTimeoutTime_IPC" SG_ 1457 End_Time_Min1_Sts 0;
BA_ "GenSigTimeoutTime_RFHM" SG_ 1457 End_Time_Min1_Sts 0;
BA_ "GenSigTimeoutTime_TCM" SG_ 1457 End_Time_Min1_Sts 0;
BA_ "GenSigSendType" SG_ 1457 End_Time_Min2_Sts 3;
BA_ "GenSigTimeoutTime_AGSM" SG_ 1457 End_Time_Min2_Sts 0;
BA_ "GenSigTimeoutTime_BCM" SG_ 1457 End_Time_Min2_Sts 0;
BA_ "GenSigTimeoutTime_BSM" SG_ 1457 End_Time_Min2_Sts 0;
BA_ "GenSigTimeoutTime_CADM" SG_ 1457 End_Time_Min2_Sts 0;
BA_ "GenSigTimeoutTime_DMSM" SG_ 1457 End_Time_Min2_Sts 0;
BA_ "GenSigTimeoutTime_DTCM" SG_ 1457 End_Time_Min2_Sts 0;
BA_ "GenSigTimeoutTime_ECM" SG_ 1457 End_Time_Min2_Sts 0;
BA_ "GenSigTimeoutTime_EVCU2" SG_ 1457 End_Time_Min2_Sts 0;
BA_ "GenSigTimeoutTime_GNMM" SG_ 1457 End_Time_Min2_Sts 0;
BA_ "GenSigTimeoutTime_HCP" SG_ 1457 End_Time_Min2_Sts 0;
BA_ "GenSigTimeoutTime_IPC" SG_ 1457 End_Time_Min2_Sts 0;
BA_ "GenSigTimeoutTime_RFHM" SG_ 1457 End_Time_Min2_Sts 0;
BA_ "GenSigTimeoutTime_TCM" SG_ 1457 End_Time_Min2_Sts 0;
BA_ "GenSigSendType" SG_ 1457 External_ChargeTarget1_Sts 3;
BA_ "GenSigTimeoutTime_AGSM" SG_ 1457 External_ChargeTarget1_Sts 0;
BA_ "GenSigTimeoutTime_BCM" SG_ 1457 External_ChargeTarget1_Sts 0;
BA_ "GenSigTimeoutTime_BSM" SG_ 1457 External_ChargeTarget1_Sts 0;
BA_ "GenSigTimeoutTime_CADM" SG_ 1457 External_ChargeTarget1_Sts 0;
BA_ "GenSigTimeoutTime_DMSM" SG_ 1457 External_ChargeTarget1_Sts 0;
BA_ "GenSigTimeoutTime_DTCM" SG_ 1457 External_ChargeTarget1_Sts 0;
BA_ "GenSigTimeoutTime_ECM" SG_ 1457 External_ChargeTarget1_Sts 0;
BA_ "GenSigTimeoutTime_EVCU2" SG_ 1457 External_ChargeTarget1_Sts 0;
BA_ "GenSigTimeoutTime_GNMM" SG_ 1457 External_ChargeTarget1_Sts 0;
BA_ "GenSigTimeoutTime_HCP" SG_ 1457 External_ChargeTarget1_Sts 0;
BA_ "GenSigTimeoutTime_IPC" SG_ 1457 External_ChargeTarget1_Sts 0;
BA_ "GenSigTimeoutTime_RFHM" SG_ 1457 External_ChargeTarget1_Sts 0;
BA_ "GenSigTimeoutTime_TCM" SG_ 1457 External_ChargeTarget1_Sts 0;
BA_ "GenSigStartValue" SG_ 1457 External_ChargeTarget2_Sts 15;
BA_ "GenSigSendType" SG_ 1457 External_ChargeTarget2_Sts 3;
BA_ "GenSigTimeoutTime_AGSM" SG_ 1457 External_ChargeTarget2_Sts 0;
BA_ "GenSigTimeoutTime_BCM" SG_ 1457 External_ChargeTarget2_Sts 0;
BA_ "GenSigTimeoutTime_BSM" SG_ 1457 External_ChargeTarget2_Sts 0;
BA_ "GenSigTimeoutTime_CADM" SG_ 1457 External_ChargeTarget2_Sts 0;
BA_ "GenSigTimeoutTime_DMSM" SG_ 1457 External_ChargeTarget2_Sts 0;
BA_ "GenSigTimeoutTime_DTCM" SG_ 1457 External_ChargeTarget2_Sts 0;
BA_ "GenSigTimeoutTime_ECM" SG_ 1457 External_ChargeTarget2_Sts 0;
BA_ "GenSigTimeoutTime_EVCU2" SG_ 1457 External_ChargeTarget2_Sts 0;
BA_ "GenSigTimeoutTime_GNMM" SG_ 1457 External_ChargeTarget2_Sts 0;
BA_ "GenSigTimeoutTime_HCP" SG_ 1457 External_ChargeTarget2_Sts 0;
BA_ "GenSigTimeoutTime_IPC" SG_ 1457 External_ChargeTarget2_Sts 0;
BA_ "GenSigTimeoutTime_RFHM" SG_ 1457 External_ChargeTarget2_Sts 0;
BA_ "GenSigTimeoutTime_TCM" SG_ 1457 External_ChargeTarget2_Sts 0;
BA_ "GenSigStartValue" SG_ 1457 Immediate_ChargeTarget1_Sts 15;
BA_ "GenSigSendType" SG_ 1457 Immediate_ChargeTarget1_Sts 3;
BA_ "GenSigTimeoutTime_AGSM" SG_ 1457 Immediate_ChargeTarget1_Sts 0;
BA_ "GenSigTimeoutTime_BCM" SG_ 1457 Immediate_ChargeTarget1_Sts 0;
BA_ "GenSigTimeoutTime_BSM" SG_ 1457 Immediate_ChargeTarget1_Sts 0;
BA_ "GenSigTimeoutTime_CADM" SG_ 1457 Immediate_ChargeTarget1_Sts 0;
BA_ "GenSigTimeoutTime_DMSM" SG_ 1457 Immediate_ChargeTarget1_Sts 0;
BA_ "GenSigTimeoutTime_DTCM" SG_ 1457 Immediate_ChargeTarget1_Sts 0;
BA_ "GenSigTimeoutTime_ECM" SG_ 1457 Immediate_ChargeTarget1_Sts 0;
BA_ "GenSigTimeoutTime_EVCU2" SG_ 1457 Immediate_ChargeTarget1_Sts 0;
BA_ "GenSigTimeoutTime_GNMM" SG_ 1457 Immediate_ChargeTarget1_Sts 0;
BA_ "GenSigTimeoutTime_HCP" SG_ 1457 Immediate_ChargeTarget1_Sts 0;
BA_ "GenSigTimeoutTime_IPC" SG_ 1457 Immediate_ChargeTarget1_Sts 0;
BA_ "GenSigTimeoutTime_RFHM" SG_ 1457 Immediate_ChargeTarget1_Sts 0;
BA_ "GenSigTimeoutTime_TCM" SG_ 1457 Immediate_ChargeTarget1_Sts 0;
BA_ "GenSigStartValue" SG_ 1457 Immediate_ChargeTarget2_Sts 15;
BA_ "GenSigSendType" SG_ 1457 Immediate_ChargeTarget2_Sts 3;
BA_ "GenSigTimeoutTime_AGSM" SG_ 1457 Immediate_ChargeTarget2_Sts 0;
BA_ "GenSigTimeoutTime_BCM" SG_ 1457 Immediate_ChargeTarget2_Sts 0;
BA_ "GenSigTimeoutTime_BSM" SG_ 1457 Immediate_ChargeTarget2_Sts 0;
BA_ "GenSigTimeoutTime_CADM" SG_ 1457 Immediate_ChargeTarget2_Sts 0;
BA_ "GenSigTimeoutTime_DMSM" SG_ 1457 Immediate_ChargeTarget2_Sts 0;
BA_ "GenSigTimeoutTime_DTCM" SG_ 1457 Immediate_ChargeTarget2_Sts 0;
BA_ "GenSigTimeoutTime_ECM" SG_ 1457 Immediate_ChargeTarget2_Sts 0;
BA_ "GenSigTimeoutTime_EVCU2" SG_ 1457 Immediate_ChargeTarget2_Sts 0;
BA_ "GenSigTimeoutTime_GNMM" SG_ 1457 Immediate_ChargeTarget2_Sts 0;
BA_ "GenSigTimeoutTime_HCP" SG_ 1457 Immediate_ChargeTarget2_Sts 0;
BA_ "GenSigTimeoutTime_IPC" SG_ 1457 Immediate_ChargeTarget2_Sts 0;
BA_ "GenSigTimeoutTime_RFHM" SG_ 1457 Immediate_ChargeTarget2_Sts 0;
BA_ "GenSigTimeoutTime_TCM" SG_ 1457 Immediate_ChargeTarget2_Sts 0;
BA_ "GenSigSendType" SG_ 1457 Schedule_Confirmed1 3;
BA_ "GenSigTimeoutTime_AGSM" SG_ 1457 Schedule_Confirmed1 0;
BA_ "GenSigTimeoutTime_BCM" SG_ 1457 Schedule_Confirmed1 0;
BA_ "GenSigTimeoutTime_BSM" SG_ 1457 Schedule_Confirmed1 0;
BA_ "GenSigTimeoutTime_CADM" SG_ 1457 Schedule_Confirmed1 0;
BA_ "GenSigTimeoutTime_DMSM" SG_ 1457 Schedule_Confirmed1 0;
BA_ "GenSigTimeoutTime_DTCM" SG_ 1457 Schedule_Confirmed1 0;
BA_ "GenSigTimeoutTime_ECM" SG_ 1457 Schedule_Confirmed1 0;
BA_ "GenSigTimeoutTime_EVCU2" SG_ 1457 Schedule_Confirmed1 0;
BA_ "GenSigTimeoutTime_GNMM" SG_ 1457 Schedule_Confirmed1 0;
BA_ "GenSigTimeoutTime_HCP" SG_ 1457 Schedule_Confirmed1 0;
BA_ "GenSigTimeoutTime_IPC" SG_ 1457 Schedule_Confirmed1 0;
BA_ "GenSigTimeoutTime_RFHM" SG_ 1457 Schedule_Confirmed1 0;
BA_ "GenSigTimeoutTime_TCM" SG_ 1457 Schedule_Confirmed1 0;
BA_ "GenSigSendType" SG_ 1457 Schedule_Confirmed2 3;
BA_ "GenSigTimeoutTime_AGSM" SG_ 1457 Schedule_Confirmed2 0;
BA_ "GenSigTimeoutTime_BCM" SG_ 1457 Schedule_Confirmed2 0;
BA_ "GenSigTimeoutTime_BSM" SG_ 1457 Schedule_Confirmed2 0;
BA_ "GenSigTimeoutTime_CADM" SG_ 1457 Schedule_Confirmed2 0;
BA_ "GenSigTimeoutTime_DMSM" SG_ 1457 Schedule_Confirmed2 0;
BA_ "GenSigTimeoutTime_DTCM" SG_ 1457 Schedule_Confirmed2 0;
BA_ "GenSigTimeoutTime_ECM" SG_ 1457 Schedule_Confirmed2 0;
BA_ "GenSigTimeoutTime_EVCU2" SG_ 1457 Schedule_Confirmed2 0;
BA_ "GenSigTimeoutTime_GNMM" SG_ 1457 Schedule_Confirmed2 0;
BA_ "GenSigTimeoutTime_HCP" SG_ 1457 Schedule_Confirmed2 0;
BA_ "GenSigTimeoutTime_IPC" SG_ 1457 Schedule_Confirmed2 0;
BA_ "GenSigTimeoutTime_RFHM" SG_ 1457 Schedule_Confirmed2 0;
BA_ "GenSigTimeoutTime_TCM" SG_ 1457 Schedule_Confirmed2 0;
BA_ "GenSigSendType" SG_ 1457 Schedule_Day1_Sts 3;
BA_ "GenSigTimeoutTime_AGSM" SG_ 1457 Schedule_Day1_Sts 0;
BA_ "GenSigTimeoutTime_BCM" SG_ 1457 Schedule_Day1_Sts 0;
BA_ "GenSigTimeoutTime_BSM" SG_ 1457 Schedule_Day1_Sts 0;
BA_ "GenSigTimeoutTime_CADM" SG_ 1457 Schedule_Day1_Sts 0;
BA_ "GenSigTimeoutTime_DMSM" SG_ 1457 Schedule_Day1_Sts 0;
BA_ "GenSigTimeoutTime_DTCM" SG_ 1457 Schedule_Day1_Sts 0;
BA_ "GenSigTimeoutTime_ECM" SG_ 1457 Schedule_Day1_Sts 0;
BA_ "GenSigTimeoutTime_EVCU2" SG_ 1457 Schedule_Day1_Sts 0;
BA_ "GenSigTimeoutTime_GNMM" SG_ 1457 Schedule_Day1_Sts 0;
BA_ "GenSigTimeoutTime_HCP" SG_ 1457 Schedule_Day1_Sts 0;
BA_ "GenSigTimeoutTime_IPC" SG_ 1457 Schedule_Day1_Sts 0;
BA_ "GenSigTimeoutTime_RFHM" SG_ 1457 Schedule_Day1_Sts 0;
BA_ "GenSigTimeoutTime_TCM" SG_ 1457 Schedule_Day1_Sts 0;
BA_ "GenSigSendType" SG_ 1457 Schedule_Day2_Sts 3;
BA_ "GenSigTimeoutTime_AGSM" SG_ 1457 Schedule_Day2_Sts 0;
BA_ "GenSigTimeoutTime_BCM" SG_ 1457 Schedule_Day2_Sts 0;
BA_ "GenSigTimeoutTime_BSM" SG_ 1457 Schedule_Day2_Sts 0;
BA_ "GenSigTimeoutTime_CADM" SG_ 1457 Schedule_Day2_Sts 0;
BA_ "GenSigTimeoutTime_DMSM" SG_ 1457 Schedule_Day2_Sts 0;
BA_ "GenSigTimeoutTime_DTCM" SG_ 1457 Schedule_Day2_Sts 0;
BA_ "GenSigTimeoutTime_ECM" SG_ 1457 Schedule_Day2_Sts 0;
BA_ "GenSigTimeoutTime_EVCU2" SG_ 1457 Schedule_Day2_Sts 0;
BA_ "GenSigTimeoutTime_GNMM" SG_ 1457 Schedule_Day2_Sts 0;
BA_ "GenSigTimeoutTime_HCP" SG_ 1457 Schedule_Day2_Sts 0;
BA_ "GenSigTimeoutTime_IPC" SG_ 1457 Schedule_Day2_Sts 0;
BA_ "GenSigTimeoutTime_RFHM" SG_ 1457 Schedule_Day2_Sts 0;
BA_ "GenSigTimeoutTime_TCM" SG_ 1457 Schedule_Day2_Sts 0;
BA_ "GenSigSendType" SG_ 1457 Start_Time_Hr1_Sts 3;
BA_ "GenSigTimeoutTime_AGSM" SG_ 1457 Start_Time_Hr1_Sts 0;
BA_ "GenSigTimeoutTime_BCM" SG_ 1457 Start_Time_Hr1_Sts 0;
BA_ "GenSigTimeoutTime_BSM" SG_ 1457 Start_Time_Hr1_Sts 0;
BA_ "GenSigTimeoutTime_CADM" SG_ 1457 Start_Time_Hr1_Sts 0;
BA_ "GenSigTimeoutTime_DMSM" SG_ 1457 Start_Time_Hr1_Sts 0;
BA_ "GenSigTimeoutTime_DTCM" SG_ 1457 Start_Time_Hr1_Sts 0;
BA_ "GenSigTimeoutTime_ECM" SG_ 1457 Start_Time_Hr1_Sts 0;
BA_ "GenSigTimeoutTime_EVCU2" SG_ 1457 Start_Time_Hr1_Sts 0;
BA_ "GenSigTimeoutTime_GNMM" SG_ 1457 Start_Time_Hr1_Sts 0;
BA_ "GenSigTimeoutTime_HCP" SG_ 1457 Start_Time_Hr1_Sts 0;
BA_ "GenSigTimeoutTime_IPC" SG_ 1457 Start_Time_Hr1_Sts 0;
BA_ "GenSigTimeoutTime_RFHM" SG_ 1457 Start_Time_Hr1_Sts 0;
BA_ "GenSigTimeoutTime_TCM" SG_ 1457 Start_Time_Hr1_Sts 0;
BA_ "GenSigSendType" SG_ 1457 Start_Time_Hr2_Sts 3;
BA_ "GenSigTimeoutTime_AGSM" SG_ 1457 Start_Time_Hr2_Sts 0;
BA_ "GenSigTimeoutTime_BCM" SG_ 1457 Start_Time_Hr2_Sts 0;
BA_ "GenSigTimeoutTime_BSM" SG_ 1457 Start_Time_Hr2_Sts 0;
BA_ "GenSigTimeoutTime_CADM" SG_ 1457 Start_Time_Hr2_Sts 0;
BA_ "GenSigTimeoutTime_DMSM" SG_ 1457 Start_Time_Hr2_Sts 0;
BA_ "GenSigTimeoutTime_DTCM" SG_ 1457 Start_Time_Hr2_Sts 0;
BA_ "GenSigTimeoutTime_ECM" SG_ 1457 Start_Time_Hr2_Sts 0;
BA_ "GenSigTimeoutTime_EVCU2" SG_ 1457 Start_Time_Hr2_Sts 0;
BA_ "GenSigTimeoutTime_GNMM" SG_ 1457 Start_Time_Hr2_Sts 0;
BA_ "GenSigTimeoutTime_HCP" SG_ 1457 Start_Time_Hr2_Sts 0;
BA_ "GenSigTimeoutTime_IPC" SG_ 1457 Start_Time_Hr2_Sts 0;
BA_ "GenSigTimeoutTime_RFHM" SG_ 1457 Start_Time_Hr2_Sts 0;
BA_ "GenSigTimeoutTime_TCM" SG_ 1457 Start_Time_Hr2_Sts 0;
BA_ "GenSigSendType" SG_ 1457 Start_Time_Min1_Sts 3;
BA_ "GenSigTimeoutTime_AGSM" SG_ 1457 Start_Time_Min1_Sts 0;
BA_ "GenSigTimeoutTime_BCM" SG_ 1457 Start_Time_Min1_Sts 0;
BA_ "GenSigTimeoutTime_BSM" SG_ 1457 Start_Time_Min1_Sts 0;
BA_ "GenSigTimeoutTime_CADM" SG_ 1457 Start_Time_Min1_Sts 0;
BA_ "GenSigTimeoutTime_DMSM" SG_ 1457 Start_Time_Min1_Sts 0;
BA_ "GenSigTimeoutTime_DTCM" SG_ 1457 Start_Time_Min1_Sts 0;
BA_ "GenSigTimeoutTime_ECM" SG_ 1457 Start_Time_Min1_Sts 0;
BA_ "GenSigTimeoutTime_EVCU2" SG_ 1457 Start_Time_Min1_Sts 0;
BA_ "GenSigTimeoutTime_GNMM" SG_ 1457 Start_Time_Min1_Sts 0;
BA_ "GenSigTimeoutTime_HCP" SG_ 1457 Start_Time_Min1_Sts 0;
BA_ "GenSigTimeoutTime_IPC" SG_ 1457 Start_Time_Min1_Sts 0;
BA_ "GenSigTimeoutTime_RFHM" SG_ 1457 Start_Time_Min1_Sts 0;
BA_ "GenSigTimeoutTime_TCM" SG_ 1457 Start_Time_Min1_Sts 0;
BA_ "GenSigSendType" SG_ 1457 Start_Time_Min2_Sts 3;
BA_ "GenSigTimeoutTime_AGSM" SG_ 1457 Start_Time_Min2_Sts 0;
BA_ "GenSigTimeoutTime_BCM" SG_ 1457 Start_Time_Min2_Sts 0;
BA_ "GenSigTimeoutTime_BSM" SG_ 1457 Start_Time_Min2_Sts 0;
BA_ "GenSigTimeoutTime_CADM" SG_ 1457 Start_Time_Min2_Sts 0;
BA_ "GenSigTimeoutTime_DMSM" SG_ 1457 Start_Time_Min2_Sts 0;
BA_ "GenSigTimeoutTime_DTCM" SG_ 1457 Start_Time_Min2_Sts 0;
BA_ "GenSigTimeoutTime_ECM" SG_ 1457 Start_Time_Min2_Sts 0;
BA_ "GenSigTimeoutTime_EVCU2" SG_ 1457 Start_Time_Min2_Sts 0;
BA_ "GenSigTimeoutTime_GNMM" SG_ 1457 Start_Time_Min2_Sts 0;
BA_ "GenSigTimeoutTime_HCP" SG_ 1457 Start_Time_Min2_Sts 0;
BA_ "GenSigTimeoutTime_IPC" SG_ 1457 Start_Time_Min2_Sts 0;
BA_ "GenSigTimeoutTime_RFHM" SG_ 1457 Start_Time_Min2_Sts 0;
BA_ "GenSigTimeoutTime_TCM" SG_ 1457 Start_Time_Min2_Sts 0;
BA_ "GenSigSendType" SG_ 1464 Charge_Schedule_Type1 3;
BA_ "GenSigTimeoutTime_AGSM" SG_ 1464 Charge_Schedule_Type1 0;
BA_ "GenSigTimeoutTime_BCM" SG_ 1464 Charge_Schedule_Type1 0;
BA_ "GenSigTimeoutTime_BSM" SG_ 1464 Charge_Schedule_Type1 0;
BA_ "GenSigTimeoutTime_CADM" SG_ 1464 Charge_Schedule_Type1 0;
BA_ "GenSigTimeoutTime_DMSM" SG_ 1464 Charge_Schedule_Type1 0;
BA_ "GenSigTimeoutTime_DTCM" SG_ 1464 Charge_Schedule_Type1 0;
BA_ "GenSigTimeoutTime_ECM" SG_ 1464 Charge_Schedule_Type1 0;
BA_ "GenSigTimeoutTime_GNMM" SG_ 1464 Charge_Schedule_Type1 0;
BA_ "GenSigTimeoutTime_HCP" SG_ 1464 Charge_Schedule_Type1 0;
BA_ "GenSigTimeoutTime_IPC" SG_ 1464 Charge_Schedule_Type1 0;
BA_ "GenSigTimeoutTime_RFHM" SG_ 1464 Charge_Schedule_Type1 0;
BA_ "GenSigTimeoutTime_SGW" SG_ 1464 Charge_Schedule_Type1 0;
BA_ "GenSigTimeoutTime_TCM" SG_ 1464 Charge_Schedule_Type1 0;
BA_ "GenSigSendType" SG_ 1464 Charge_Schedule_Type2 3;
BA_ "GenSigTimeoutTime_AGSM" SG_ 1464 Charge_Schedule_Type2 0;
BA_ "GenSigTimeoutTime_BCM" SG_ 1464 Charge_Schedule_Type2 0;
BA_ "GenSigTimeoutTime_BSM" SG_ 1464 Charge_Schedule_Type2 0;
BA_ "GenSigTimeoutTime_CADM" SG_ 1464 Charge_Schedule_Type2 0;
BA_ "GenSigTimeoutTime_DMSM" SG_ 1464 Charge_Schedule_Type2 0;
BA_ "GenSigTimeoutTime_DTCM" SG_ 1464 Charge_Schedule_Type2 0;
BA_ "GenSigTimeoutTime_ECM" SG_ 1464 Charge_Schedule_Type2 0;
BA_ "GenSigTimeoutTime_GNMM" SG_ 1464 Charge_Schedule_Type2 0;
BA_ "GenSigTimeoutTime_HCP" SG_ 1464 Charge_Schedule_Type2 0;
BA_ "GenSigTimeoutTime_IPC" SG_ 1464 Charge_Schedule_Type2 0;
BA_ "GenSigTimeoutTime_RFHM" SG_ 1464 Charge_Schedule_Type2 0;
BA_ "GenSigTimeoutTime_SGW" SG_ 1464 Charge_Schedule_Type2 0;
BA_ "GenSigTimeoutTime_TCM" SG_ 1464 Charge_Schedule_Type2 0;
BA_ "GenSigSendType" SG_ 1464 ChargeUntilFull1 3;
BA_ "GenSigTimeoutTime_AGSM" SG_ 1464 ChargeUntilFull1 0;
BA_ "GenSigTimeoutTime_BCM" SG_ 1464 ChargeUntilFull1 0;
BA_ "GenSigTimeoutTime_BSM" SG_ 1464 ChargeUntilFull1 0;
BA_ "GenSigTimeoutTime_CADM" SG_ 1464 ChargeUntilFull1 0;
BA_ "GenSigTimeoutTime_DMSM" SG_ 1464 ChargeUntilFull1 0;
BA_ "GenSigTimeoutTime_DTCM" SG_ 1464 ChargeUntilFull1 0;
BA_ "GenSigTimeoutTime_ECM" SG_ 1464 ChargeUntilFull1 0;
BA_ "GenSigTimeoutTime_GNMM" SG_ 1464 ChargeUntilFull1 0;
BA_ "GenSigTimeoutTime_HCP" SG_ 1464 ChargeUntilFull1 0;
BA_ "GenSigTimeoutTime_IPC" SG_ 1464 ChargeUntilFull1 0;
BA_ "GenSigTimeoutTime_RFHM" SG_ 1464 ChargeUntilFull1 0;
BA_ "GenSigTimeoutTime_SGW" SG_ 1464 ChargeUntilFull1 0;
BA_ "GenSigTimeoutTime_TCM" SG_ 1464 ChargeUntilFull1 0;
BA_ "GenSigSendType" SG_ 1464 ChargeUntilFull2 3;
BA_ "GenSigTimeoutTime_AGSM" SG_ 1464 ChargeUntilFull2 0;
BA_ "GenSigTimeoutTime_BCM" SG_ 1464 ChargeUntilFull2 0;
BA_ "GenSigTimeoutTime_BSM" SG_ 1464 ChargeUntilFull2 0;
BA_ "GenSigTimeoutTime_CADM" SG_ 1464 ChargeUntilFull2 0;
BA_ "GenSigTimeoutTime_DMSM" SG_ 1464 ChargeUntilFull2 0;
BA_ "GenSigTimeoutTime_DTCM" SG_ 1464 ChargeUntilFull2 0;
BA_ "GenSigTimeoutTime_ECM" SG_ 1464 ChargeUntilFull2 0;
BA_ "GenSigTimeoutTime_GNMM" SG_ 1464 ChargeUntilFull2 0;
BA_ "GenSigTimeoutTime_HCP" SG_ 1464 ChargeUntilFull2 0;
BA_ "GenSigTimeoutTime_IPC" SG_ 1464 ChargeUntilFull2 0;
BA_ "GenSigTimeoutTime_RFHM" SG_ 1464 ChargeUntilFull2 0;
BA_ "GenSigTimeoutTime_SGW" SG_ 1464 ChargeUntilFull2 0;
BA_ "GenSigTimeoutTime_TCM" SG_ 1464 ChargeUntilFull2 0;
BA_ "GenSigSendType" SG_ 1464 Enable_Schedule1 3;
BA_ "GenSigTimeoutTime_AGSM" SG_ 1464 Enable_Schedule1 0;
BA_ "GenSigTimeoutTime_BCM" SG_ 1464 Enable_Schedule1 0;
BA_ "GenSigTimeoutTime_BSM" SG_ 1464 Enable_Schedule1 0;
BA_ "GenSigTimeoutTime_CADM" SG_ 1464 Enable_Schedule1 0;
BA_ "GenSigTimeoutTime_DMSM" SG_ 1464 Enable_Schedule1 0;
BA_ "GenSigTimeoutTime_DTCM" SG_ 1464 Enable_Schedule1 0;
BA_ "GenSigTimeoutTime_ECM" SG_ 1464 Enable_Schedule1 0;
BA_ "GenSigTimeoutTime_GNMM" SG_ 1464 Enable_Schedule1 0;
BA_ "GenSigTimeoutTime_HCP" SG_ 1464 Enable_Schedule1 0;
BA_ "GenSigTimeoutTime_IPC" SG_ 1464 Enable_Schedule1 0;
BA_ "GenSigTimeoutTime_RFHM" SG_ 1464 Enable_Schedule1 0;
BA_ "GenSigTimeoutTime_SGW" SG_ 1464 Enable_Schedule1 0;
BA_ "GenSigTimeoutTime_TCM" SG_ 1464 Enable_Schedule1 0;
BA_ "GenSigSendType" SG_ 1464 Enable_Schedule2 3;
BA_ "GenSigTimeoutTime_AGSM" SG_ 1464 Enable_Schedule2 0;
BA_ "GenSigTimeoutTime_BCM" SG_ 1464 Enable_Schedule2 0;
BA_ "GenSigTimeoutTime_BSM" SG_ 1464 Enable_Schedule2 0;
BA_ "GenSigTimeoutTime_CADM" SG_ 1464 Enable_Schedule2 0;
BA_ "GenSigTimeoutTime_DMSM" SG_ 1464 Enable_Schedule2 0;
BA_ "GenSigTimeoutTime_DTCM" SG_ 1464 Enable_Schedule2 0;
BA_ "GenSigTimeoutTime_ECM" SG_ 1464 Enable_Schedule2 0;
BA_ "GenSigTimeoutTime_GNMM" SG_ 1464 Enable_Schedule2 0;
BA_ "GenSigTimeoutTime_HCP" SG_ 1464 Enable_Schedule2 0;
BA_ "GenSigTimeoutTime_IPC" SG_ 1464 Enable_Schedule2 0;
BA_ "GenSigTimeoutTime_RFHM" SG_ 1464 Enable_Schedule2 0;
BA_ "GenSigTimeoutTime_SGW" SG_ 1464 Enable_Schedule2 0;
BA_ "GenSigTimeoutTime_TCM" SG_ 1464 Enable_Schedule2 0;
BA_ "GenSigSendType" SG_ 1464 End_Time_Hr1 3;
BA_ "GenSigTimeoutTime_AGSM" SG_ 1464 End_Time_Hr1 0;
BA_ "GenSigTimeoutTime_BCM" SG_ 1464 End_Time_Hr1 0;
BA_ "GenSigTimeoutTime_BSM" SG_ 1464 End_Time_Hr1 0;
BA_ "GenSigTimeoutTime_CADM" SG_ 1464 End_Time_Hr1 0;
BA_ "GenSigTimeoutTime_DMSM" SG_ 1464 End_Time_Hr1 0;
BA_ "GenSigTimeoutTime_DTCM" SG_ 1464 End_Time_Hr1 0;
BA_ "GenSigTimeoutTime_ECM" SG_ 1464 End_Time_Hr1 0;
BA_ "GenSigTimeoutTime_GNMM" SG_ 1464 End_Time_Hr1 0;
BA_ "GenSigTimeoutTime_HCP" SG_ 1464 End_Time_Hr1 0;
BA_ "GenSigTimeoutTime_IPC" SG_ 1464 End_Time_Hr1 0;
BA_ "GenSigTimeoutTime_RFHM" SG_ 1464 End_Time_Hr1 0;
BA_ "GenSigTimeoutTime_SGW" SG_ 1464 End_Time_Hr1 0;
BA_ "GenSigTimeoutTime_TCM" SG_ 1464 End_Time_Hr1 0;
BA_ "GenSigSendType" SG_ 1464 End_Time_Hr2 3;
BA_ "GenSigTimeoutTime_AGSM" SG_ 1464 End_Time_Hr2 0;
BA_ "GenSigTimeoutTime_BCM" SG_ 1464 End_Time_Hr2 0;
BA_ "GenSigTimeoutTime_BSM" SG_ 1464 End_Time_Hr2 0;
BA_ "GenSigTimeoutTime_CADM" SG_ 1464 End_Time_Hr2 0;
BA_ "GenSigTimeoutTime_DMSM" SG_ 1464 End_Time_Hr2 0;
BA_ "GenSigTimeoutTime_DTCM" SG_ 1464 End_Time_Hr2 0;
BA_ "GenSigTimeoutTime_ECM" SG_ 1464 End_Time_Hr2 0;
BA_ "GenSigTimeoutTime_GNMM" SG_ 1464 End_Time_Hr2 0;
BA_ "GenSigTimeoutTime_HCP" SG_ 1464 End_Time_Hr2 0;
BA_ "GenSigTimeoutTime_IPC" SG_ 1464 End_Time_Hr2 0;
BA_ "GenSigTimeoutTime_RFHM" SG_ 1464 End_Time_Hr2 0;
BA_ "GenSigTimeoutTime_SGW" SG_ 1464 End_Time_Hr2 0;
BA_ "GenSigTimeoutTime_TCM" SG_ 1464 End_Time_Hr2 0;
BA_ "GenSigSendType" SG_ 1464 End_Time_Min1 3;
BA_ "GenSigTimeoutTime_AGSM" SG_ 1464 End_Time_Min1 0;
BA_ "GenSigTimeoutTime_BCM" SG_ 1464 End_Time_Min1 0;
BA_ "GenSigTimeoutTime_BSM" SG_ 1464 End_Time_Min1 0;
BA_ "GenSigTimeoutTime_CADM" SG_ 1464 End_Time_Min1 0;
BA_ "GenSigTimeoutTime_DMSM" SG_ 1464 End_Time_Min1 0;
BA_ "GenSigTimeoutTime_DTCM" SG_ 1464 End_Time_Min1 0;
BA_ "GenSigTimeoutTime_ECM" SG_ 1464 End_Time_Min1 0;
BA_ "GenSigTimeoutTime_GNMM" SG_ 1464 End_Time_Min1 0;
BA_ "GenSigTimeoutTime_HCP" SG_ 1464 End_Time_Min1 0;
BA_ "GenSigTimeoutTime_IPC" SG_ 1464 End_Time_Min1 0;
BA_ "GenSigTimeoutTime_RFHM" SG_ 1464 End_Time_Min1 0;
BA_ "GenSigTimeoutTime_SGW" SG_ 1464 End_Time_Min1 0;
BA_ "GenSigTimeoutTime_TCM" SG_ 1464 End_Time_Min1 0;
BA_ "GenSigSendType" SG_ 1464 End_Time_Min2 3;
BA_ "GenSigTimeoutTime_AGSM" SG_ 1464 End_Time_Min2 0;
BA_ "GenSigTimeoutTime_BCM" SG_ 1464 End_Time_Min2 0;
BA_ "GenSigTimeoutTime_BSM" SG_ 1464 End_Time_Min2 0;
BA_ "GenSigTimeoutTime_CADM" SG_ 1464 End_Time_Min2 0;
BA_ "GenSigTimeoutTime_DMSM" SG_ 1464 End_Time_Min2 0;
BA_ "GenSigTimeoutTime_DTCM" SG_ 1464 End_Time_Min2 0;
BA_ "GenSigTimeoutTime_ECM" SG_ 1464 End_Time_Min2 0;
BA_ "GenSigTimeoutTime_GNMM" SG_ 1464 End_Time_Min2 0;
BA_ "GenSigTimeoutTime_HCP" SG_ 1464 End_Time_Min2 0;
BA_ "GenSigTimeoutTime_IPC" SG_ 1464 End_Time_Min2 0;
BA_ "GenSigTimeoutTime_RFHM" SG_ 1464 End_Time_Min2 0;
BA_ "GenSigTimeoutTime_SGW" SG_ 1464 End_Time_Min2 0;
BA_ "GenSigTimeoutTime_TCM" SG_ 1464 End_Time_Min2 0;
BA_ "GenSigStartValue" SG_ 1464 External_ChargeTarget1 15;
BA_ "GenSigSendType" SG_ 1464 External_ChargeTarget1 3;
BA_ "GenSigTimeoutTime_AGSM" SG_ 1464 External_ChargeTarget1 0;
BA_ "GenSigTimeoutTime_BCM" SG_ 1464 External_ChargeTarget1 0;
BA_ "GenSigTimeoutTime_BSM" SG_ 1464 External_ChargeTarget1 0;
BA_ "GenSigTimeoutTime_CADM" SG_ 1464 External_ChargeTarget1 0;
BA_ "GenSigTimeoutTime_DMSM" SG_ 1464 External_ChargeTarget1 0;
BA_ "GenSigTimeoutTime_DTCM" SG_ 1464 External_ChargeTarget1 0;
BA_ "GenSigTimeoutTime_ECM" SG_ 1464 External_ChargeTarget1 0;
BA_ "GenSigTimeoutTime_GNMM" SG_ 1464 External_ChargeTarget1 0;
BA_ "GenSigTimeoutTime_HCP" SG_ 1464 External_ChargeTarget1 0;
BA_ "GenSigTimeoutTime_IPC" SG_ 1464 External_ChargeTarget1 0;
BA_ "GenSigTimeoutTime_RFHM" SG_ 1464 External_ChargeTarget1 0;
BA_ "GenSigTimeoutTime_SGW" SG_ 1464 External_ChargeTarget1 0;
BA_ "GenSigTimeoutTime_TCM" SG_ 1464 External_ChargeTarget1 0;
BA_ "GenSigStartValue" SG_ 1464 External_ChargeTarget2 15;
BA_ "GenSigSendType" SG_ 1464 External_ChargeTarget2 3;
BA_ "GenSigTimeoutTime_AGSM" SG_ 1464 External_ChargeTarget2 0;
BA_ "GenSigTimeoutTime_BCM" SG_ 1464 External_ChargeTarget2 0;
BA_ "GenSigTimeoutTime_BSM" SG_ 1464 External_ChargeTarget2 0;
BA_ "GenSigTimeoutTime_CADM" SG_ 1464 External_ChargeTarget2 0;
BA_ "GenSigTimeoutTime_DMSM" SG_ 1464 External_ChargeTarget2 0;
BA_ "GenSigTimeoutTime_DTCM" SG_ 1464 External_ChargeTarget2 0;
BA_ "GenSigTimeoutTime_ECM" SG_ 1464 External_ChargeTarget2 0;
BA_ "GenSigTimeoutTime_GNMM" SG_ 1464 External_ChargeTarget2 0;
BA_ "GenSigTimeoutTime_HCP" SG_ 1464 External_ChargeTarget2 0;
BA_ "GenSigTimeoutTime_IPC" SG_ 1464 External_ChargeTarget2 0;
BA_ "GenSigTimeoutTime_RFHM" SG_ 1464 External_ChargeTarget2 0;
BA_ "GenSigTimeoutTime_SGW" SG_ 1464 External_ChargeTarget2 0;
BA_ "GenSigTimeoutTime_TCM" SG_ 1464 External_ChargeTarget2 0;
BA_ "GenSigStartValue" SG_ 1464 Immediate_ChargeTarget1 15;
BA_ "GenSigSendType" SG_ 1464 Immediate_ChargeTarget1 3;
BA_ "GenSigTimeoutTime_AGSM" SG_ 1464 Immediate_ChargeTarget1 0;
BA_ "GenSigTimeoutTime_BCM" SG_ 1464 Immediate_ChargeTarget1 0;
BA_ "GenSigTimeoutTime_BSM" SG_ 1464 Immediate_ChargeTarget1 0;
BA_ "GenSigTimeoutTime_CADM" SG_ 1464 Immediate_ChargeTarget1 0;
BA_ "GenSigTimeoutTime_DMSM" SG_ 1464 Immediate_ChargeTarget1 0;
BA_ "GenSigTimeoutTime_DTCM" SG_ 1464 Immediate_ChargeTarget1 0;
BA_ "GenSigTimeoutTime_ECM" SG_ 1464 Immediate_ChargeTarget1 0;
BA_ "GenSigTimeoutTime_GNMM" SG_ 1464 Immediate_ChargeTarget1 0;
BA_ "GenSigTimeoutTime_HCP" SG_ 1464 Immediate_ChargeTarget1 0;
BA_ "GenSigTimeoutTime_IPC" SG_ 1464 Immediate_ChargeTarget1 0;
BA_ "GenSigTimeoutTime_RFHM" SG_ 1464 Immediate_ChargeTarget1 0;
BA_ "GenSigTimeoutTime_SGW" SG_ 1464 Immediate_ChargeTarget1 0;
BA_ "GenSigTimeoutTime_TCM" SG_ 1464 Immediate_ChargeTarget1 0;
BA_ "GenSigStartValue" SG_ 1464 Immediate_ChargeTarget2 15;
BA_ "GenSigSendType" SG_ 1464 Immediate_ChargeTarget2 3;
BA_ "GenSigTimeoutTime_AGSM" SG_ 1464 Immediate_ChargeTarget2 0;
BA_ "GenSigTimeoutTime_BCM" SG_ 1464 Immediate_ChargeTarget2 0;
BA_ "GenSigTimeoutTime_BSM" SG_ 1464 Immediate_ChargeTarget2 0;
BA_ "GenSigTimeoutTime_CADM" SG_ 1464 Immediate_ChargeTarget2 0;
BA_ "GenSigTimeoutTime_DMSM" SG_ 1464 Immediate_ChargeTarget2 0;
BA_ "GenSigTimeoutTime_DTCM" SG_ 1464 Immediate_ChargeTarget2 0;
BA_ "GenSigTimeoutTime_ECM" SG_ 1464 Immediate_ChargeTarget2 0;
BA_ "GenSigTimeoutTime_GNMM" SG_ 1464 Immediate_ChargeTarget2 0;
BA_ "GenSigTimeoutTime_HCP" SG_ 1464 Immediate_ChargeTarget2 0;
BA_ "GenSigTimeoutTime_IPC" SG_ 1464 Immediate_ChargeTarget2 0;
BA_ "GenSigTimeoutTime_RFHM" SG_ 1464 Immediate_ChargeTarget2 0;
BA_ "GenSigTimeoutTime_SGW" SG_ 1464 Immediate_ChargeTarget2 0;
BA_ "GenSigTimeoutTime_TCM" SG_ 1464 Immediate_ChargeTarget2 0;
BA_ "GenSigSendType" SG_ 1464 Schedule_Day1 3;
BA_ "GenSigTimeoutTime_AGSM" SG_ 1464 Schedule_Day1 0;
BA_ "GenSigTimeoutTime_BCM" SG_ 1464 Schedule_Day1 0;
BA_ "GenSigTimeoutTime_BSM" SG_ 1464 Schedule_Day1 0;
BA_ "GenSigTimeoutTime_CADM" SG_ 1464 Schedule_Day1 0;
BA_ "GenSigTimeoutTime_DMSM" SG_ 1464 Schedule_Day1 0;
BA_ "GenSigTimeoutTime_DTCM" SG_ 1464 Schedule_Day1 0;
BA_ "GenSigTimeoutTime_ECM" SG_ 1464 Schedule_Day1 0;
BA_ "GenSigTimeoutTime_GNMM" SG_ 1464 Schedule_Day1 0;
BA_ "GenSigTimeoutTime_HCP" SG_ 1464 Schedule_Day1 0;
BA_ "GenSigTimeoutTime_IPC" SG_ 1464 Schedule_Day1 0;
BA_ "GenSigTimeoutTime_RFHM" SG_ 1464 Schedule_Day1 0;
BA_ "GenSigTimeoutTime_SGW" SG_ 1464 Schedule_Day1 0;
BA_ "GenSigTimeoutTime_TCM" SG_ 1464 Schedule_Day1 0;
BA_ "GenSigSendType" SG_ 1464 Schedule_Day2 3;
BA_ "GenSigTimeoutTime_AGSM" SG_ 1464 Schedule_Day2 0;
BA_ "GenSigTimeoutTime_BCM" SG_ 1464 Schedule_Day2 0;
BA_ "GenSigTimeoutTime_BSM" SG_ 1464 Schedule_Day2 0;
BA_ "GenSigTimeoutTime_CADM" SG_ 1464 Schedule_Day2 0;
BA_ "GenSigTimeoutTime_DMSM" SG_ 1464 Schedule_Day2 0;
BA_ "GenSigTimeoutTime_DTCM" SG_ 1464 Schedule_Day2 0;
BA_ "GenSigTimeoutTime_ECM" SG_ 1464 Schedule_Day2 0;
BA_ "GenSigTimeoutTime_GNMM" SG_ 1464 Schedule_Day2 0;
BA_ "GenSigTimeoutTime_HCP" SG_ 1464 Schedule_Day2 0;
BA_ "GenSigTimeoutTime_IPC" SG_ 1464 Schedule_Day2 0;
BA_ "GenSigTimeoutTime_RFHM" SG_ 1464 Schedule_Day2 0;
BA_ "GenSigTimeoutTime_SGW" SG_ 1464 Schedule_Day2 0;
BA_ "GenSigTimeoutTime_TCM" SG_ 1464 Schedule_Day2 0;
BA_ "GenSigSendType" SG_ 1464 Start_Time_Hr1 3;
BA_ "GenSigTimeoutTime_AGSM" SG_ 1464 Start_Time_Hr1 0;
BA_ "GenSigTimeoutTime_BCM" SG_ 1464 Start_Time_Hr1 0;
BA_ "GenSigTimeoutTime_BSM" SG_ 1464 Start_Time_Hr1 0;
BA_ "GenSigTimeoutTime_CADM" SG_ 1464 Start_Time_Hr1 0;
BA_ "GenSigTimeoutTime_DMSM" SG_ 1464 Start_Time_Hr1 0;
BA_ "GenSigTimeoutTime_DTCM" SG_ 1464 Start_Time_Hr1 0;
BA_ "GenSigTimeoutTime_ECM" SG_ 1464 Start_Time_Hr1 0;
BA_ "GenSigTimeoutTime_GNMM" SG_ 1464 Start_Time_Hr1 0;
BA_ "GenSigTimeoutTime_HCP" SG_ 1464 Start_Time_Hr1 0;
BA_ "GenSigTimeoutTime_IPC" SG_ 1464 Start_Time_Hr1 0;
BA_ "GenSigTimeoutTime_RFHM" SG_ 1464 Start_Time_Hr1 0;
BA_ "GenSigTimeoutTime_SGW" SG_ 1464 Start_Time_Hr1 0;
BA_ "GenSigTimeoutTime_TCM" SG_ 1464 Start_Time_Hr1 0;
BA_ "GenSigSendType" SG_ 1464 Start_Time_Hr2 3;
BA_ "GenSigTimeoutTime_AGSM" SG_ 1464 Start_Time_Hr2 0;
BA_ "GenSigTimeoutTime_BCM" SG_ 1464 Start_Time_Hr2 0;
BA_ "GenSigTimeoutTime_BSM" SG_ 1464 Start_Time_Hr2 0;
BA_ "GenSigTimeoutTime_CADM" SG_ 1464 Start_Time_Hr2 0;
BA_ "GenSigTimeoutTime_DMSM" SG_ 1464 Start_Time_Hr2 0;
BA_ "GenSigTimeoutTime_DTCM" SG_ 1464 Start_Time_Hr2 0;
BA_ "GenSigTimeoutTime_ECM" SG_ 1464 Start_Time_Hr2 0;
BA_ "GenSigTimeoutTime_GNMM" SG_ 1464 Start_Time_Hr2 0;
BA_ "GenSigTimeoutTime_HCP" SG_ 1464 Start_Time_Hr2 0;
BA_ "GenSigTimeoutTime_IPC" SG_ 1464 Start_Time_Hr2 0;
BA_ "GenSigTimeoutTime_RFHM" SG_ 1464 Start_Time_Hr2 0;
BA_ "GenSigTimeoutTime_SGW" SG_ 1464 Start_Time_Hr2 0;
BA_ "GenSigTimeoutTime_TCM" SG_ 1464 Start_Time_Hr2 0;
BA_ "GenSigSendType" SG_ 1464 Start_Time_Min1 3;
BA_ "GenSigTimeoutTime_AGSM" SG_ 1464 Start_Time_Min1 0;
BA_ "GenSigTimeoutTime_BCM" SG_ 1464 Start_Time_Min1 0;
BA_ "GenSigTimeoutTime_BSM" SG_ 1464 Start_Time_Min1 0;
BA_ "GenSigTimeoutTime_CADM" SG_ 1464 Start_Time_Min1 0;
BA_ "GenSigTimeoutTime_DMSM" SG_ 1464 Start_Time_Min1 0;
BA_ "GenSigTimeoutTime_DTCM" SG_ 1464 Start_Time_Min1 0;
BA_ "GenSigTimeoutTime_ECM" SG_ 1464 Start_Time_Min1 0;
BA_ "GenSigTimeoutTime_GNMM" SG_ 1464 Start_Time_Min1 0;
BA_ "GenSigTimeoutTime_HCP" SG_ 1464 Start_Time_Min1 0;
BA_ "GenSigTimeoutTime_IPC" SG_ 1464 Start_Time_Min1 0;
BA_ "GenSigTimeoutTime_RFHM" SG_ 1464 Start_Time_Min1 0;
BA_ "GenSigTimeoutTime_SGW" SG_ 1464 Start_Time_Min1 0;
BA_ "GenSigTimeoutTime_TCM" SG_ 1464 Start_Time_Min1 0;
BA_ "GenSigSendType" SG_ 1464 Start_Time_Min2 3;
BA_ "GenSigTimeoutTime_AGSM" SG_ 1464 Start_Time_Min2 0;
BA_ "GenSigTimeoutTime_BCM" SG_ 1464 Start_Time_Min2 0;
BA_ "GenSigTimeoutTime_BSM" SG_ 1464 Start_Time_Min2 0;
BA_ "GenSigTimeoutTime_CADM" SG_ 1464 Start_Time_Min2 0;
BA_ "GenSigTimeoutTime_DMSM" SG_ 1464 Start_Time_Min2 0;
BA_ "GenSigTimeoutTime_DTCM" SG_ 1464 Start_Time_Min2 0;
BA_ "GenSigTimeoutTime_ECM" SG_ 1464 Start_Time_Min2 0;
BA_ "GenSigTimeoutTime_GNMM" SG_ 1464 Start_Time_Min2 0;
BA_ "GenSigTimeoutTime_HCP" SG_ 1464 Start_Time_Min2 0;
BA_ "GenSigTimeoutTime_IPC" SG_ 1464 Start_Time_Min2 0;
BA_ "GenSigTimeoutTime_RFHM" SG_ 1464 Start_Time_Min2 0;
BA_ "GenSigTimeoutTime_SGW" SG_ 1464 Start_Time_Min2 0;
BA_ "GenSigTimeoutTime_TCM" SG_ 1464 Start_Time_Min2 0;
BA_ "GenSigSendType" SG_ 1464 Submit_Schedule1 3;
BA_ "GenSigTimeoutTime_AGSM" SG_ 1464 Submit_Schedule1 0;
BA_ "GenSigTimeoutTime_BCM" SG_ 1464 Submit_Schedule1 0;
BA_ "GenSigTimeoutTime_BSM" SG_ 1464 Submit_Schedule1 0;
BA_ "GenSigTimeoutTime_CADM" SG_ 1464 Submit_Schedule1 0;
BA_ "GenSigTimeoutTime_DMSM" SG_ 1464 Submit_Schedule1 0;
BA_ "GenSigTimeoutTime_DTCM" SG_ 1464 Submit_Schedule1 0;
BA_ "GenSigTimeoutTime_ECM" SG_ 1464 Submit_Schedule1 0;
BA_ "GenSigTimeoutTime_GNMM" SG_ 1464 Submit_Schedule1 0;
BA_ "GenSigTimeoutTime_HCP" SG_ 1464 Submit_Schedule1 0;
BA_ "GenSigTimeoutTime_IPC" SG_ 1464 Submit_Schedule1 0;
BA_ "GenSigTimeoutTime_RFHM" SG_ 1464 Submit_Schedule1 0;
BA_ "GenSigTimeoutTime_SGW" SG_ 1464 Submit_Schedule1 0;
BA_ "GenSigTimeoutTime_TCM" SG_ 1464 Submit_Schedule1 0;
BA_ "GenSigSendType" SG_ 1464 Submit_Schedule2 3;
BA_ "GenSigTimeoutTime_AGSM" SG_ 1464 Submit_Schedule2 0;
BA_ "GenSigTimeoutTime_BCM" SG_ 1464 Submit_Schedule2 0;
BA_ "GenSigTimeoutTime_BSM" SG_ 1464 Submit_Schedule2 0;
BA_ "GenSigTimeoutTime_CADM" SG_ 1464 Submit_Schedule2 0;
BA_ "GenSigTimeoutTime_DMSM" SG_ 1464 Submit_Schedule2 0;
BA_ "GenSigTimeoutTime_DTCM" SG_ 1464 Submit_Schedule2 0;
BA_ "GenSigTimeoutTime_ECM" SG_ 1464 Submit_Schedule2 0;
BA_ "GenSigTimeoutTime_GNMM" SG_ 1464 Submit_Schedule2 0;
BA_ "GenSigTimeoutTime_HCP" SG_ 1464 Submit_Schedule2 0;
BA_ "GenSigTimeoutTime_IPC" SG_ 1464 Submit_Schedule2 0;
BA_ "GenSigTimeoutTime_RFHM" SG_ 1464 Submit_Schedule2 0;
BA_ "GenSigTimeoutTime_SGW" SG_ 1464 Submit_Schedule2 0;
BA_ "GenSigTimeoutTime_TCM" SG_ 1464 Submit_Schedule2 0;
BA_ "GenSigSendType" SG_ 1459 Next_Charge_End_Time_Hr 3;
BA_ "GenSigTimeoutTime_AGSM" SG_ 1459 Next_Charge_End_Time_Hr 0;
BA_ "GenSigTimeoutTime_BCM" SG_ 1459 Next_Charge_End_Time_Hr 0;
BA_ "GenSigTimeoutTime_BSM" SG_ 1459 Next_Charge_End_Time_Hr 0;
BA_ "GenSigTimeoutTime_CADM" SG_ 1459 Next_Charge_End_Time_Hr 0;
BA_ "GenSigTimeoutTime_DMSM" SG_ 1459 Next_Charge_End_Time_Hr 0;
BA_ "GenSigTimeoutTime_DTCM" SG_ 1459 Next_Charge_End_Time_Hr 0;
BA_ "GenSigTimeoutTime_ECM" SG_ 1459 Next_Charge_End_Time_Hr 0;
BA_ "GenSigTimeoutTime_EVCU2" SG_ 1459 Next_Charge_End_Time_Hr 0;
BA_ "GenSigTimeoutTime_GNMM" SG_ 1459 Next_Charge_End_Time_Hr 0;
BA_ "GenSigTimeoutTime_HCP" SG_ 1459 Next_Charge_End_Time_Hr 0;
BA_ "GenSigTimeoutTime_RFHM" SG_ 1459 Next_Charge_End_Time_Hr 0;
BA_ "GenSigTimeoutTime_TCM" SG_ 1459 Next_Charge_End_Time_Hr 0;
BA_ "GenSigTimeoutTime_AGSM" SG_ 1459 Next_Charge_End_Time_Min 0;
BA_ "GenSigTimeoutTime_BCM" SG_ 1459 Next_Charge_End_Time_Min 0;
BA_ "GenSigTimeoutTime_BSM" SG_ 1459 Next_Charge_End_Time_Min 0;
BA_ "GenSigTimeoutTime_CADM" SG_ 1459 Next_Charge_End_Time_Min 0;
BA_ "GenSigTimeoutTime_DMSM" SG_ 1459 Next_Charge_End_Time_Min 0;
BA_ "GenSigTimeoutTime_DTCM" SG_ 1459 Next_Charge_End_Time_Min 0;
BA_ "GenSigTimeoutTime_ECM" SG_ 1459 Next_Charge_End_Time_Min 0;
BA_ "GenSigTimeoutTime_EVCU2" SG_ 1459 Next_Charge_End_Time_Min 0;
BA_ "GenSigTimeoutTime_GNMM" SG_ 1459 Next_Charge_End_Time_Min 0;
BA_ "GenSigTimeoutTime_HCP" SG_ 1459 Next_Charge_End_Time_Min 0;
BA_ "GenSigTimeoutTime_RFHM" SG_ 1459 Next_Charge_End_Time_Min 0;
BA_ "GenSigTimeoutTime_TCM" SG_ 1459 Next_Charge_End_Time_Min 0;
BA_ "GenSigTimeoutTime_AGSM" SG_ 1459 Next_Charge_EndDay 0;
BA_ "GenSigTimeoutTime_BCM" SG_ 1459 Next_Charge_EndDay 0;
BA_ "GenSigTimeoutTime_BSM" SG_ 1459 Next_Charge_EndDay 0;
BA_ "GenSigTimeoutTime_CADM" SG_ 1459 Next_Charge_EndDay 0;
BA_ "GenSigTimeoutTime_DMSM" SG_ 1459 Next_Charge_EndDay 0;
BA_ "GenSigTimeoutTime_DTCM" SG_ 1459 Next_Charge_EndDay 0;
BA_ "GenSigTimeoutTime_ECM" SG_ 1459 Next_Charge_EndDay 0;
BA_ "GenSigTimeoutTime_EVCU2" SG_ 1459 Next_Charge_EndDay 0;
BA_ "GenSigTimeoutTime_GNMM" SG_ 1459 Next_Charge_EndDay 0;
BA_ "GenSigTimeoutTime_HCP" SG_ 1459 Next_Charge_EndDay 0;
BA_ "GenSigTimeoutTime_RFHM" SG_ 1459 Next_Charge_EndDay 0;
BA_ "GenSigTimeoutTime_TCM" SG_ 1459 Next_Charge_EndDay 0;
BA_ "GenSigTimeoutTime_AGSM" SG_ 1459 Next_Charge_Start_Time_Hr 0;
BA_ "GenSigTimeoutTime_BCM" SG_ 1459 Next_Charge_Start_Time_Hr 0;
BA_ "GenSigTimeoutTime_BSM" SG_ 1459 Next_Charge_Start_Time_Hr 0;
BA_ "GenSigTimeoutTime_CADM" SG_ 1459 Next_Charge_Start_Time_Hr 0;
BA_ "GenSigTimeoutTime_DMSM" SG_ 1459 Next_Charge_Start_Time_Hr 0;
BA_ "GenSigTimeoutTime_DTCM" SG_ 1459 Next_Charge_Start_Time_Hr 0;
BA_ "GenSigTimeoutTime_ECM" SG_ 1459 Next_Charge_Start_Time_Hr 0;
BA_ "GenSigTimeoutTime_EVCU2" SG_ 1459 Next_Charge_Start_Time_Hr 0;
BA_ "GenSigTimeoutTime_GNMM" SG_ 1459 Next_Charge_Start_Time_Hr 0;
BA_ "GenSigTimeoutTime_HCP" SG_ 1459 Next_Charge_Start_Time_Hr 0;
BA_ "GenSigTimeoutTime_RFHM" SG_ 1459 Next_Charge_Start_Time_Hr 0;
BA_ "GenSigTimeoutTime_TCM" SG_ 1459 Next_Charge_Start_Time_Hr 0;
BA_ "GenSigTimeoutTime_AGSM" SG_ 1459 Next_Charge_Start_Time_Min 0;
BA_ "GenSigTimeoutTime_BCM" SG_ 1459 Next_Charge_Start_Time_Min 0;
BA_ "GenSigTimeoutTime_BSM" SG_ 1459 Next_Charge_Start_Time_Min 0;
BA_ "GenSigTimeoutTime_CADM" SG_ 1459 Next_Charge_Start_Time_Min 0;
BA_ "GenSigTimeoutTime_DMSM" SG_ 1459 Next_Charge_Start_Time_Min 0;
BA_ "GenSigTimeoutTime_DTCM" SG_ 1459 Next_Charge_Start_Time_Min 0;
BA_ "GenSigTimeoutTime_ECM" SG_ 1459 Next_Charge_Start_Time_Min 0;
BA_ "GenSigTimeoutTime_EVCU2" SG_ 1459 Next_Charge_Start_Time_Min 0;
BA_ "GenSigTimeoutTime_GNMM" SG_ 1459 Next_Charge_Start_Time_Min 0;
BA_ "GenSigTimeoutTime_HCP" SG_ 1459 Next_Charge_Start_Time_Min 0;
BA_ "GenSigTimeoutTime_RFHM" SG_ 1459 Next_Charge_Start_Time_Min 0;
BA_ "GenSigTimeoutTime_TCM" SG_ 1459 Next_Charge_Start_Time_Min 0;
BA_ "GenSigTimeoutTime_AGSM" SG_ 1459 Next_Charge_StartDay 0;
BA_ "GenSigTimeoutTime_BCM" SG_ 1459 Next_Charge_StartDay 0;
BA_ "GenSigTimeoutTime_BSM" SG_ 1459 Next_Charge_StartDay 0;
BA_ "GenSigTimeoutTime_CADM" SG_ 1459 Next_Charge_StartDay 0;
BA_ "GenSigTimeoutTime_DMSM" SG_ 1459 Next_Charge_StartDay 0;
BA_ "GenSigTimeoutTime_DTCM" SG_ 1459 Next_Charge_StartDay 0;
BA_ "GenSigTimeoutTime_ECM" SG_ 1459 Next_Charge_StartDay 0;
BA_ "GenSigTimeoutTime_EVCU2" SG_ 1459 Next_Charge_StartDay 0;
BA_ "GenSigTimeoutTime_GNMM" SG_ 1459 Next_Charge_StartDay 0;
BA_ "GenSigTimeoutTime_HCP" SG_ 1459 Next_Charge_StartDay 0;
BA_ "GenSigTimeoutTime_RFHM" SG_ 1459 Next_Charge_StartDay 0;
BA_ "GenSigTimeoutTime_TCM" SG_ 1459 Next_Charge_StartDay 0;
BA_ "GenSigTimeoutTime_AGSM" SG_ 1459 Next_Climate_Day 0;
BA_ "GenSigTimeoutTime_BCM" SG_ 1459 Next_Climate_Day 0;
BA_ "GenSigTimeoutTime_BSM" SG_ 1459 Next_Climate_Day 0;
BA_ "GenSigTimeoutTime_CADM" SG_ 1459 Next_Climate_Day 0;
BA_ "GenSigTimeoutTime_DMSM" SG_ 1459 Next_Climate_Day 0;
BA_ "GenSigTimeoutTime_DTCM" SG_ 1459 Next_Climate_Day 0;
BA_ "GenSigTimeoutTime_ECM" SG_ 1459 Next_Climate_Day 0;
BA_ "GenSigTimeoutTime_EVCU2" SG_ 1459 Next_Climate_Day 0;
BA_ "GenSigTimeoutTime_GNMM" SG_ 1459 Next_Climate_Day 0;
BA_ "GenSigTimeoutTime_HCP" SG_ 1459 Next_Climate_Day 0;
BA_ "GenSigTimeoutTime_IPC" SG_ 1459 Next_Climate_Day 0;
BA_ "GenSigTimeoutTime_RFHM" SG_ 1459 Next_Climate_Day 0;
BA_ "GenSigTimeoutTime_TCM" SG_ 1459 Next_Climate_Day 0;
BA_ "GenSigTimeoutTime_AGSM" SG_ 1459 Next_Climate_Time_Hr 0;
BA_ "GenSigTimeoutTime_BCM" SG_ 1459 Next_Climate_Time_Hr 0;
BA_ "GenSigTimeoutTime_BSM" SG_ 1459 Next_Climate_Time_Hr 0;
BA_ "GenSigTimeoutTime_CADM" SG_ 1459 Next_Climate_Time_Hr 0;
BA_ "GenSigTimeoutTime_DMSM" SG_ 1459 Next_Climate_Time_Hr 0;
BA_ "GenSigTimeoutTime_DTCM" SG_ 1459 Next_Climate_Time_Hr 0;
BA_ "GenSigTimeoutTime_ECM" SG_ 1459 Next_Climate_Time_Hr 0;
BA_ "GenSigTimeoutTime_EVCU2" SG_ 1459 Next_Climate_Time_Hr 0;
BA_ "GenSigTimeoutTime_GNMM" SG_ 1459 Next_Climate_Time_Hr 0;
BA_ "GenSigTimeoutTime_HCP" SG_ 1459 Next_Climate_Time_Hr 0;
BA_ "GenSigTimeoutTime_IPC" SG_ 1459 Next_Climate_Time_Hr 0;
BA_ "GenSigTimeoutTime_RFHM" SG_ 1459 Next_Climate_Time_Hr 0;
BA_ "GenSigTimeoutTime_TCM" SG_ 1459 Next_Climate_Time_Hr 0;
BA_ "GenSigTimeoutTime_AGSM" SG_ 1459 Next_Climate_Time_Min 0;
BA_ "GenSigTimeoutTime_BCM" SG_ 1459 Next_Climate_Time_Min 0;
BA_ "GenSigTimeoutTime_BSM" SG_ 1459 Next_Climate_Time_Min 0;
BA_ "GenSigTimeoutTime_CADM" SG_ 1459 Next_Climate_Time_Min 0;
BA_ "GenSigTimeoutTime_DMSM" SG_ 1459 Next_Climate_Time_Min 0;
BA_ "GenSigTimeoutTime_DTCM" SG_ 1459 Next_Climate_Time_Min 0;
BA_ "GenSigTimeoutTime_ECM" SG_ 1459 Next_Climate_Time_Min 0;
BA_ "GenSigTimeoutTime_EVCU2" SG_ 1459 Next_Climate_Time_Min 0;
BA_ "GenSigTimeoutTime_GNMM" SG_ 1459 Next_Climate_Time_Min 0;
BA_ "GenSigTimeoutTime_HCP" SG_ 1459 Next_Climate_Time_Min 0;
BA_ "GenSigTimeoutTime_IPC" SG_ 1459 Next_Climate_Time_Min 0;
BA_ "GenSigTimeoutTime_RFHM" SG_ 1459 Next_Climate_Time_Min 0;
BA_ "GenSigTimeoutTime_TCM" SG_ 1459 Next_Climate_Time_Min 0;
BA_ "GenSigStartValue" SG_ 1459 Next_SchCabin_Temp 12;
BA_ "GenSigTimeoutTime_AGSM" SG_ 1459 Next_SchCabin_Temp 0;
BA_ "GenSigTimeoutTime_BCM" SG_ 1459 Next_SchCabin_Temp 0;
BA_ "GenSigTimeoutTime_BSM" SG_ 1459 Next_SchCabin_Temp 0;
BA_ "GenSigTimeoutTime_CADM" SG_ 1459 Next_SchCabin_Temp 0;
BA_ "GenSigTimeoutTime_DMSM" SG_ 1459 Next_SchCabin_Temp 0;
BA_ "GenSigTimeoutTime_DTCM" SG_ 1459 Next_SchCabin_Temp 0;
BA_ "GenSigTimeoutTime_ECM" SG_ 1459 Next_SchCabin_Temp 0;
BA_ "GenSigTimeoutTime_EVCU2" SG_ 1459 Next_SchCabin_Temp 0;
BA_ "GenSigTimeoutTime_GNMM" SG_ 1459 Next_SchCabin_Temp 0;
BA_ "GenSigTimeoutTime_HCP" SG_ 1459 Next_SchCabin_Temp 0;
BA_ "GenSigTimeoutTime_IPC" SG_ 1459 Next_SchCabin_Temp 0;
BA_ "GenSigTimeoutTime_RFHM" SG_ 1459 Next_SchCabin_Temp 0;
BA_ "GenSigTimeoutTime_SGW" SG_ 1459 Next_SchCabin_Temp 0;
BA_ "GenSigTimeoutTime_TCM" SG_ 1459 Next_SchCabin_Temp 0;
BA_ "GenSigSendType" SG_ 1459 Nxt_Charge_Schedule_Type 3;
BA_ "GenSigTimeoutTime_AGSM" SG_ 1459 Nxt_Charge_Schedule_Type 0;
BA_ "GenSigTimeoutTime_BCM" SG_ 1459 Nxt_Charge_Schedule_Type 0;
BA_ "GenSigTimeoutTime_BSM" SG_ 1459 Nxt_Charge_Schedule_Type 0;
BA_ "GenSigTimeoutTime_CADM" SG_ 1459 Nxt_Charge_Schedule_Type 0;
BA_ "GenSigTimeoutTime_DMSM" SG_ 1459 Nxt_Charge_Schedule_Type 0;
BA_ "GenSigTimeoutTime_DTCM" SG_ 1459 Nxt_Charge_Schedule_Type 0;
BA_ "GenSigTimeoutTime_ECM" SG_ 1459 Nxt_Charge_Schedule_Type 0;
BA_ "GenSigTimeoutTime_EVCU2" SG_ 1459 Nxt_Charge_Schedule_Type 0;
BA_ "GenSigTimeoutTime_GNMM" SG_ 1459 Nxt_Charge_Schedule_Type 0;
BA_ "GenSigTimeoutTime_HCP" SG_ 1459 Nxt_Charge_Schedule_Type 0;
BA_ "GenSigTimeoutTime_IPC" SG_ 1459 Nxt_Charge_Schedule_Type 0;
BA_ "GenSigTimeoutTime_RFHM" SG_ 1459 Nxt_Charge_Schedule_Type 0;
BA_ "GenSigTimeoutTime_TCM" SG_ 1459 Nxt_Charge_Schedule_Type 0;
BA_ "GenSigSendType" SG_ 1459 Nxt_Ext_Charge_End_Time_Hr 3;
BA_ "GenSigTimeoutTime_AGSM" SG_ 1459 Nxt_Ext_Charge_End_Time_Hr 0;
BA_ "GenSigTimeoutTime_BCM" SG_ 1459 Nxt_Ext_Charge_End_Time_Hr 0;
BA_ "GenSigTimeoutTime_BSM" SG_ 1459 Nxt_Ext_Charge_End_Time_Hr 0;
BA_ "GenSigTimeoutTime_CADM" SG_ 1459 Nxt_Ext_Charge_End_Time_Hr 0;
BA_ "GenSigTimeoutTime_DMSM" SG_ 1459 Nxt_Ext_Charge_End_Time_Hr 0;
BA_ "GenSigTimeoutTime_DTCM" SG_ 1459 Nxt_Ext_Charge_End_Time_Hr 0;
BA_ "GenSigTimeoutTime_ECM" SG_ 1459 Nxt_Ext_Charge_End_Time_Hr 0;
BA_ "GenSigTimeoutTime_EVCU2" SG_ 1459 Nxt_Ext_Charge_End_Time_Hr 0;
BA_ "GenSigTimeoutTime_GNMM" SG_ 1459 Nxt_Ext_Charge_End_Time_Hr 0;
BA_ "GenSigTimeoutTime_HCP" SG_ 1459 Nxt_Ext_Charge_End_Time_Hr 0;
BA_ "GenSigTimeoutTime_IPC" SG_ 1459 Nxt_Ext_Charge_End_Time_Hr 0;
BA_ "GenSigTimeoutTime_RFHM" SG_ 1459 Nxt_Ext_Charge_End_Time_Hr 0;
BA_ "GenSigTimeoutTime_TCM" SG_ 1459 Nxt_Ext_Charge_End_Time_Hr 0;
BA_ "GenSigStartValue" SG_ 1459 Nxt_Ext_Charge_End_Time_Min 15;
BA_ "GenSigSendType" SG_ 1459 Nxt_Ext_Charge_End_Time_Min 3;
BA_ "GenSigTimeoutTime_AGSM" SG_ 1459 Nxt_Ext_Charge_End_Time_Min 0;
BA_ "GenSigTimeoutTime_BCM" SG_ 1459 Nxt_Ext_Charge_End_Time_Min 0;
BA_ "GenSigTimeoutTime_BSM" SG_ 1459 Nxt_Ext_Charge_End_Time_Min 0;
BA_ "GenSigTimeoutTime_CADM" SG_ 1459 Nxt_Ext_Charge_End_Time_Min 0;
BA_ "GenSigTimeoutTime_DMSM" SG_ 1459 Nxt_Ext_Charge_End_Time_Min 0;
BA_ "GenSigTimeoutTime_DTCM" SG_ 1459 Nxt_Ext_Charge_End_Time_Min 0;
BA_ "GenSigTimeoutTime_ECM" SG_ 1459 Nxt_Ext_Charge_End_Time_Min 0;
BA_ "GenSigTimeoutTime_EVCU2" SG_ 1459 Nxt_Ext_Charge_End_Time_Min 0;
BA_ "GenSigTimeoutTime_GNMM" SG_ 1459 Nxt_Ext_Charge_End_Time_Min 0;
BA_ "GenSigTimeoutTime_HCP" SG_ 1459 Nxt_Ext_Charge_End_Time_Min 0;
BA_ "GenSigTimeoutTime_IPC" SG_ 1459 Nxt_Ext_Charge_End_Time_Min 0;
BA_ "GenSigTimeoutTime_RFHM" SG_ 1459 Nxt_Ext_Charge_End_Time_Min 0;
BA_ "GenSigTimeoutTime_TCM" SG_ 1459 Nxt_Ext_Charge_End_Time_Min 0;
BA_ "GenSigStartValue" SG_ 1459 Nxt_External_Charge_EndDay 15;
BA_ "GenSigSendType" SG_ 1459 Nxt_External_Charge_EndDay 3;
BA_ "GenSigTimeoutTime_AGSM" SG_ 1459 Nxt_External_Charge_EndDay 0;
BA_ "GenSigTimeoutTime_BCM" SG_ 1459 Nxt_External_Charge_EndDay 0;
BA_ "GenSigTimeoutTime_BSM" SG_ 1459 Nxt_External_Charge_EndDay 0;
BA_ "GenSigTimeoutTime_CADM" SG_ 1459 Nxt_External_Charge_EndDay 0;
BA_ "GenSigTimeoutTime_DMSM" SG_ 1459 Nxt_External_Charge_EndDay 0;
BA_ "GenSigTimeoutTime_DTCM" SG_ 1459 Nxt_External_Charge_EndDay 0;
BA_ "GenSigTimeoutTime_ECM" SG_ 1459 Nxt_External_Charge_EndDay 0;
BA_ "GenSigTimeoutTime_EVCU2" SG_ 1459 Nxt_External_Charge_EndDay 0;
BA_ "GenSigTimeoutTime_GNMM" SG_ 1459 Nxt_External_Charge_EndDay 0;
BA_ "GenSigTimeoutTime_HCP" SG_ 1459 Nxt_External_Charge_EndDay 0;
BA_ "GenSigTimeoutTime_IPC" SG_ 1459 Nxt_External_Charge_EndDay 0;
BA_ "GenSigTimeoutTime_RFHM" SG_ 1459 Nxt_External_Charge_EndDay 0;
BA_ "GenSigTimeoutTime_TCM" SG_ 1459 Nxt_External_Charge_EndDay 0;
BA_ "GenSigStartValue" SG_ 1459 Nxt_External_Charge_ExternalTgt 15;
BA_ "GenSigSendType" SG_ 1459 Nxt_External_Charge_ExternalTgt 3;
BA_ "GenSigTimeoutTime_AGSM" SG_ 1459 Nxt_External_Charge_ExternalTgt 0;
BA_ "GenSigTimeoutTime_BCM" SG_ 1459 Nxt_External_Charge_ExternalTgt 0;
BA_ "GenSigTimeoutTime_BSM" SG_ 1459 Nxt_External_Charge_ExternalTgt 0;
BA_ "GenSigTimeoutTime_CADM" SG_ 1459 Nxt_External_Charge_ExternalTgt 0;
BA_ "GenSigTimeoutTime_DMSM" SG_ 1459 Nxt_External_Charge_ExternalTgt 0;
BA_ "GenSigTimeoutTime_DTCM" SG_ 1459 Nxt_External_Charge_ExternalTgt 0;
BA_ "GenSigTimeoutTime_ECM" SG_ 1459 Nxt_External_Charge_ExternalTgt 0;
BA_ "GenSigTimeoutTime_EVCU2" SG_ 1459 Nxt_External_Charge_ExternalTgt 0;
BA_ "GenSigTimeoutTime_GNMM" SG_ 1459 Nxt_External_Charge_ExternalTgt 0;
BA_ "GenSigTimeoutTime_HCP" SG_ 1459 Nxt_External_Charge_ExternalTgt 0;
BA_ "GenSigTimeoutTime_IPC" SG_ 1459 Nxt_External_Charge_ExternalTgt 0;
BA_ "GenSigTimeoutTime_RFHM" SG_ 1459 Nxt_External_Charge_ExternalTgt 0;
BA_ "GenSigTimeoutTime_TCM" SG_ 1459 Nxt_External_Charge_ExternalTgt 0;
BA_ "GenSigStartValue" SG_ 1459 Nxt_External_Charge_ImmediateTgt 15;
BA_ "GenSigSendType" SG_ 1459 Nxt_External_Charge_ImmediateTgt 3;
BA_ "GenSigTimeoutTime_AGSM" SG_ 1459 Nxt_External_Charge_ImmediateTgt 0;
BA_ "GenSigTimeoutTime_BCM" SG_ 1459 Nxt_External_Charge_ImmediateTgt 0;
BA_ "GenSigTimeoutTime_BSM" SG_ 1459 Nxt_External_Charge_ImmediateTgt 0;
BA_ "GenSigTimeoutTime_CADM" SG_ 1459 Nxt_External_Charge_ImmediateTgt 0;
BA_ "GenSigTimeoutTime_DMSM" SG_ 1459 Nxt_External_Charge_ImmediateTgt 0;
BA_ "GenSigTimeoutTime_DTCM" SG_ 1459 Nxt_External_Charge_ImmediateTgt 0;
BA_ "GenSigTimeoutTime_ECM" SG_ 1459 Nxt_External_Charge_ImmediateTgt 0;
BA_ "GenSigTimeoutTime_EVCU2" SG_ 1459 Nxt_External_Charge_ImmediateTgt 0;
BA_ "GenSigTimeoutTime_GNMM" SG_ 1459 Nxt_External_Charge_ImmediateTgt 0;
BA_ "GenSigTimeoutTime_HCP" SG_ 1459 Nxt_External_Charge_ImmediateTgt 0;
BA_ "GenSigTimeoutTime_IPC" SG_ 1459 Nxt_External_Charge_ImmediateTgt 0;
BA_ "GenSigTimeoutTime_RFHM" SG_ 1459 Nxt_External_Charge_ImmediateTgt 0;
BA_ "GenSigTimeoutTime_TCM" SG_ 1459 Nxt_External_Charge_ImmediateTgt 0;
BA_ "GenSigSendType" SG_ 1468 AllowClimateSchd1_Sts 3;
BA_ "GenSigTimeoutTime_AGSM" SG_ 1468 AllowClimateSchd1_Sts 0;
BA_ "GenSigTimeoutTime_BCM" SG_ 1468 AllowClimateSchd1_Sts 0;
BA_ "GenSigTimeoutTime_BSM" SG_ 1468 AllowClimateSchd1_Sts 0;
BA_ "GenSigTimeoutTime_CADM" SG_ 1468 AllowClimateSchd1_Sts 0;
BA_ "GenSigTimeoutTime_DMSM" SG_ 1468 AllowClimateSchd1_Sts 0;
BA_ "GenSigTimeoutTime_DTCM" SG_ 1468 AllowClimateSchd1_Sts 0;
BA_ "GenSigTimeoutTime_ECM" SG_ 1468 AllowClimateSchd1_Sts 0;
BA_ "GenSigTimeoutTime_EVCU2" SG_ 1468 AllowClimateSchd1_Sts 0;
BA_ "GenSigTimeoutTime_GNMM" SG_ 1468 AllowClimateSchd1_Sts 0;
BA_ "GenSigTimeoutTime_HCP" SG_ 1468 AllowClimateSchd1_Sts 0;
BA_ "GenSigTimeoutTime_IPC" SG_ 1468 AllowClimateSchd1_Sts 0;
BA_ "GenSigTimeoutTime_RFHM" SG_ 1468 AllowClimateSchd1_Sts 0;
BA_ "GenSigTimeoutTime_TCM" SG_ 1468 AllowClimateSchd1_Sts 0;
BA_ "GenSigSendType" SG_ 1468 AllowClimateSchd2_Sts 3;
BA_ "GenSigTimeoutTime_AGSM" SG_ 1468 AllowClimateSchd2_Sts 0;
BA_ "GenSigTimeoutTime_BCM" SG_ 1468 AllowClimateSchd2_Sts 0;
BA_ "GenSigTimeoutTime_BSM" SG_ 1468 AllowClimateSchd2_Sts 0;
BA_ "GenSigTimeoutTime_CADM" SG_ 1468 AllowClimateSchd2_Sts 0;
BA_ "GenSigTimeoutTime_DMSM" SG_ 1468 AllowClimateSchd2_Sts 0;
BA_ "GenSigTimeoutTime_DTCM" SG_ 1468 AllowClimateSchd2_Sts 0;
BA_ "GenSigTimeoutTime_ECM" SG_ 1468 AllowClimateSchd2_Sts 0;
BA_ "GenSigTimeoutTime_EVCU2" SG_ 1468 AllowClimateSchd2_Sts 0;
BA_ "GenSigTimeoutTime_GNMM" SG_ 1468 AllowClimateSchd2_Sts 0;
BA_ "GenSigTimeoutTime_HCP" SG_ 1468 AllowClimateSchd2_Sts 0;
BA_ "GenSigTimeoutTime_IPC" SG_ 1468 AllowClimateSchd2_Sts 0;
BA_ "GenSigTimeoutTime_RFHM" SG_ 1468 AllowClimateSchd2_Sts 0;
BA_ "GenSigTimeoutTime_TCM" SG_ 1468 AllowClimateSchd2_Sts 0;
BA_ "GenSigStartValue" SG_ 1468 Climate_Cabin_Temp1_Sts 12;
BA_ "GenSigSendType" SG_ 1468 Climate_Cabin_Temp1_Sts 3;
BA_ "GenSigTimeoutTime_AGSM" SG_ 1468 Climate_Cabin_Temp1_Sts 0;
BA_ "GenSigTimeoutTime_BCM" SG_ 1468 Climate_Cabin_Temp1_Sts 0;
BA_ "GenSigTimeoutTime_BSM" SG_ 1468 Climate_Cabin_Temp1_Sts 0;
BA_ "GenSigTimeoutTime_CADM" SG_ 1468 Climate_Cabin_Temp1_Sts 0;
BA_ "GenSigTimeoutTime_DMSM" SG_ 1468 Climate_Cabin_Temp1_Sts 0;
BA_ "GenSigTimeoutTime_DTCM" SG_ 1468 Climate_Cabin_Temp1_Sts 0;
BA_ "GenSigTimeoutTime_ECM" SG_ 1468 Climate_Cabin_Temp1_Sts 0;
BA_ "GenSigTimeoutTime_EVCU2" SG_ 1468 Climate_Cabin_Temp1_Sts 0;
BA_ "GenSigTimeoutTime_GNMM" SG_ 1468 Climate_Cabin_Temp1_Sts 0;
BA_ "GenSigTimeoutTime_HCP" SG_ 1468 Climate_Cabin_Temp1_Sts 0;
BA_ "GenSigTimeoutTime_IPC" SG_ 1468 Climate_Cabin_Temp1_Sts 0;
BA_ "GenSigTimeoutTime_RFHM" SG_ 1468 Climate_Cabin_Temp1_Sts 0;
BA_ "GenSigTimeoutTime_TCM" SG_ 1468 Climate_Cabin_Temp1_Sts 0;
BA_ "GenSigStartValue" SG_ 1468 Climate_Cabin_Temp2_Sts 12;
BA_ "GenSigSendType" SG_ 1468 Climate_Cabin_Temp2_Sts 3;
BA_ "GenSigTimeoutTime_AGSM" SG_ 1468 Climate_Cabin_Temp2_Sts 0;
BA_ "GenSigTimeoutTime_BCM" SG_ 1468 Climate_Cabin_Temp2_Sts 0;
BA_ "GenSigTimeoutTime_BSM" SG_ 1468 Climate_Cabin_Temp2_Sts 0;
BA_ "GenSigTimeoutTime_CADM" SG_ 1468 Climate_Cabin_Temp2_Sts 0;
BA_ "GenSigTimeoutTime_DMSM" SG_ 1468 Climate_Cabin_Temp2_Sts 0;
BA_ "GenSigTimeoutTime_DTCM" SG_ 1468 Climate_Cabin_Temp2_Sts 0;
BA_ "GenSigTimeoutTime_ECM" SG_ 1468 Climate_Cabin_Temp2_Sts 0;
BA_ "GenSigTimeoutTime_EVCU2" SG_ 1468 Climate_Cabin_Temp2_Sts 0;
BA_ "GenSigTimeoutTime_GNMM" SG_ 1468 Climate_Cabin_Temp2_Sts 0;
BA_ "GenSigTimeoutTime_HCP" SG_ 1468 Climate_Cabin_Temp2_Sts 0;
BA_ "GenSigTimeoutTime_IPC" SG_ 1468 Climate_Cabin_Temp2_Sts 0;
BA_ "GenSigTimeoutTime_RFHM" SG_ 1468 Climate_Cabin_Temp2_Sts 0;
BA_ "GenSigTimeoutTime_TCM" SG_ 1468 Climate_Cabin_Temp2_Sts 0;
BA_ "GenSigSendType" SG_ 1468 ClimateSchd1_Day_Sts 3;
BA_ "GenSigTimeoutTime_AGSM" SG_ 1468 ClimateSchd1_Day_Sts 0;
BA_ "GenSigTimeoutTime_BCM" SG_ 1468 ClimateSchd1_Day_Sts 0;
BA_ "GenSigTimeoutTime_BSM" SG_ 1468 ClimateSchd1_Day_Sts 0;
BA_ "GenSigTimeoutTime_CADM" SG_ 1468 ClimateSchd1_Day_Sts 0;
BA_ "GenSigTimeoutTime_DMSM" SG_ 1468 ClimateSchd1_Day_Sts 0;
BA_ "GenSigTimeoutTime_DTCM" SG_ 1468 ClimateSchd1_Day_Sts 0;
BA_ "GenSigTimeoutTime_ECM" SG_ 1468 ClimateSchd1_Day_Sts 0;
BA_ "GenSigTimeoutTime_EVCU2" SG_ 1468 ClimateSchd1_Day_Sts 0;
BA_ "GenSigTimeoutTime_GNMM" SG_ 1468 ClimateSchd1_Day_Sts 0;
BA_ "GenSigTimeoutTime_HCP" SG_ 1468 ClimateSchd1_Day_Sts 0;
BA_ "GenSigTimeoutTime_IPC" SG_ 1468 ClimateSchd1_Day_Sts 0;
BA_ "GenSigTimeoutTime_RFHM" SG_ 1468 ClimateSchd1_Day_Sts 0;
BA_ "GenSigTimeoutTime_TCM" SG_ 1468 ClimateSchd1_Day_Sts 0;
BA_ "GenSigSendType" SG_ 1468 ClimateSchd1_Departure_Hr_Sts 3;
BA_ "GenSigTimeoutTime_AGSM" SG_ 1468 ClimateSchd1_Departure_Hr_Sts 0;
BA_ "GenSigTimeoutTime_BCM" SG_ 1468 ClimateSchd1_Departure_Hr_Sts 0;
BA_ "GenSigTimeoutTime_BSM" SG_ 1468 ClimateSchd1_Departure_Hr_Sts 0;
BA_ "GenSigTimeoutTime_CADM" SG_ 1468 ClimateSchd1_Departure_Hr_Sts 0;
BA_ "GenSigTimeoutTime_DMSM" SG_ 1468 ClimateSchd1_Departure_Hr_Sts 0;
BA_ "GenSigTimeoutTime_DTCM" SG_ 1468 ClimateSchd1_Departure_Hr_Sts 0;
BA_ "GenSigTimeoutTime_ECM" SG_ 1468 ClimateSchd1_Departure_Hr_Sts 0;
BA_ "GenSigTimeoutTime_EVCU2" SG_ 1468 ClimateSchd1_Departure_Hr_Sts 0;
BA_ "GenSigTimeoutTime_GNMM" SG_ 1468 ClimateSchd1_Departure_Hr_Sts 0;
BA_ "GenSigTimeoutTime_HCP" SG_ 1468 ClimateSchd1_Departure_Hr_Sts 0;
BA_ "GenSigTimeoutTime_IPC" SG_ 1468 ClimateSchd1_Departure_Hr_Sts 0;
BA_ "GenSigTimeoutTime_RFHM" SG_ 1468 ClimateSchd1_Departure_Hr_Sts 0;
BA_ "GenSigTimeoutTime_TCM" SG_ 1468 ClimateSchd1_Departure_Hr_Sts 0;
BA_ "GenSigSendType" SG_ 1468 ClimateSchd1_Departure_Min_Sts 3;
BA_ "GenSigTimeoutTime_AGSM" SG_ 1468 ClimateSchd1_Departure_Min_Sts 0;
BA_ "GenSigTimeoutTime_BCM" SG_ 1468 ClimateSchd1_Departure_Min_Sts 0;
BA_ "GenSigTimeoutTime_BSM" SG_ 1468 ClimateSchd1_Departure_Min_Sts 0;
BA_ "GenSigTimeoutTime_CADM" SG_ 1468 ClimateSchd1_Departure_Min_Sts 0;
BA_ "GenSigTimeoutTime_DMSM" SG_ 1468 ClimateSchd1_Departure_Min_Sts 0;
BA_ "GenSigTimeoutTime_DTCM" SG_ 1468 ClimateSchd1_Departure_Min_Sts 0;
BA_ "GenSigTimeoutTime_ECM" SG_ 1468 ClimateSchd1_Departure_Min_Sts 0;
BA_ "GenSigTimeoutTime_EVCU2" SG_ 1468 ClimateSchd1_Departure_Min_Sts 0;
BA_ "GenSigTimeoutTime_GNMM" SG_ 1468 ClimateSchd1_Departure_Min_Sts 0;
BA_ "GenSigTimeoutTime_HCP" SG_ 1468 ClimateSchd1_Departure_Min_Sts 0;
BA_ "GenSigTimeoutTime_IPC" SG_ 1468 ClimateSchd1_Departure_Min_Sts 0;
BA_ "GenSigTimeoutTime_RFHM" SG_ 1468 ClimateSchd1_Departure_Min_Sts 0;
BA_ "GenSigTimeoutTime_TCM" SG_ 1468 ClimateSchd1_Departure_Min_Sts 0;
BA_ "GenSigSendType" SG_ 1468 ClimateSchd2_Day_Sts 3;
BA_ "GenSigTimeoutTime_AGSM" SG_ 1468 ClimateSchd2_Day_Sts 0;
BA_ "GenSigTimeoutTime_BCM" SG_ 1468 ClimateSchd2_Day_Sts 0;
BA_ "GenSigTimeoutTime_BSM" SG_ 1468 ClimateSchd2_Day_Sts 0;
BA_ "GenSigTimeoutTime_CADM" SG_ 1468 ClimateSchd2_Day_Sts 0;
BA_ "GenSigTimeoutTime_DMSM" SG_ 1468 ClimateSchd2_Day_Sts 0;
BA_ "GenSigTimeoutTime_DTCM" SG_ 1468 ClimateSchd2_Day_Sts 0;
BA_ "GenSigTimeoutTime_ECM" SG_ 1468 ClimateSchd2_Day_Sts 0;
BA_ "GenSigTimeoutTime_EVCU2" SG_ 1468 ClimateSchd2_Day_Sts 0;
BA_ "GenSigTimeoutTime_GNMM" SG_ 1468 ClimateSchd2_Day_Sts 0;
BA_ "GenSigTimeoutTime_HCP" SG_ 1468 ClimateSchd2_Day_Sts 0;
BA_ "GenSigTimeoutTime_IPC" SG_ 1468 ClimateSchd2_Day_Sts 0;
BA_ "GenSigTimeoutTime_RFHM" SG_ 1468 ClimateSchd2_Day_Sts 0;
BA_ "GenSigTimeoutTime_TCM" SG_ 1468 ClimateSchd2_Day_Sts 0;
BA_ "GenSigSendType" SG_ 1468 ClimateSchd2_Departure_Hr_Sts 3;
BA_ "GenSigTimeoutTime_AGSM" SG_ 1468 ClimateSchd2_Departure_Hr_Sts 0;
BA_ "GenSigTimeoutTime_BCM" SG_ 1468 ClimateSchd2_Departure_Hr_Sts 0;
BA_ "GenSigTimeoutTime_BSM" SG_ 1468 ClimateSchd2_Departure_Hr_Sts 0;
BA_ "GenSigTimeoutTime_CADM" SG_ 1468 ClimateSchd2_Departure_Hr_Sts 0;
BA_ "GenSigTimeoutTime_DMSM" SG_ 1468 ClimateSchd2_Departure_Hr_Sts 0;
BA_ "GenSigTimeoutTime_DTCM" SG_ 1468 ClimateSchd2_Departure_Hr_Sts 0;
BA_ "GenSigTimeoutTime_ECM" SG_ 1468 ClimateSchd2_Departure_Hr_Sts 0;
BA_ "GenSigTimeoutTime_EVCU2" SG_ 1468 ClimateSchd2_Departure_Hr_Sts 0;
BA_ "GenSigTimeoutTime_GNMM" SG_ 1468 ClimateSchd2_Departure_Hr_Sts 0;
BA_ "GenSigTimeoutTime_HCP" SG_ 1468 ClimateSchd2_Departure_Hr_Sts 0;
BA_ "GenSigTimeoutTime_IPC" SG_ 1468 ClimateSchd2_Departure_Hr_Sts 0;
BA_ "GenSigTimeoutTime_RFHM" SG_ 1468 ClimateSchd2_Departure_Hr_Sts 0;
BA_ "GenSigTimeoutTime_TCM" SG_ 1468 ClimateSchd2_Departure_Hr_Sts 0;
BA_ "GenSigSendType" SG_ 1468 ClimateSchd2_Departure_Min_Sts 3;
BA_ "GenSigTimeoutTime_AGSM" SG_ 1468 ClimateSchd2_Departure_Min_Sts 0;
BA_ "GenSigTimeoutTime_BCM" SG_ 1468 ClimateSchd2_Departure_Min_Sts 0;
BA_ "GenSigTimeoutTime_BSM" SG_ 1468 ClimateSchd2_Departure_Min_Sts 0;
BA_ "GenSigTimeoutTime_CADM" SG_ 1468 ClimateSchd2_Departure_Min_Sts 0;
BA_ "GenSigTimeoutTime_DMSM" SG_ 1468 ClimateSchd2_Departure_Min_Sts 0;
BA_ "GenSigTimeoutTime_DTCM" SG_ 1468 ClimateSchd2_Departure_Min_Sts 0;
BA_ "GenSigTimeoutTime_ECM" SG_ 1468 ClimateSchd2_Departure_Min_Sts 0;
BA_ "GenSigTimeoutTime_EVCU2" SG_ 1468 ClimateSchd2_Departure_Min_Sts 0;
BA_ "GenSigTimeoutTime_GNMM" SG_ 1468 ClimateSchd2_Departure_Min_Sts 0;
BA_ "GenSigTimeoutTime_HCP" SG_ 1468 ClimateSchd2_Departure_Min_Sts 0;
BA_ "GenSigTimeoutTime_IPC" SG_ 1468 ClimateSchd2_Departure_Min_Sts 0;
BA_ "GenSigTimeoutTime_RFHM" SG_ 1468 ClimateSchd2_Departure_Min_Sts 0;
BA_ "GenSigTimeoutTime_TCM" SG_ 1468 ClimateSchd2_Departure_Min_Sts 0;
BA_ "GenSigSendType" SG_ 1468 Enable_ClimateSchd1_Sts 3;
BA_ "GenSigTimeoutTime_AGSM" SG_ 1468 Enable_ClimateSchd1_Sts 0;
BA_ "GenSigTimeoutTime_BCM" SG_ 1468 Enable_ClimateSchd1_Sts 0;
BA_ "GenSigTimeoutTime_BSM" SG_ 1468 Enable_ClimateSchd1_Sts 0;
BA_ "GenSigTimeoutTime_CADM" SG_ 1468 Enable_ClimateSchd1_Sts 0;
BA_ "GenSigTimeoutTime_DMSM" SG_ 1468 Enable_ClimateSchd1_Sts 0;
BA_ "GenSigTimeoutTime_DTCM" SG_ 1468 Enable_ClimateSchd1_Sts 0;
BA_ "GenSigTimeoutTime_ECM" SG_ 1468 Enable_ClimateSchd1_Sts 0;
BA_ "GenSigTimeoutTime_EVCU2" SG_ 1468 Enable_ClimateSchd1_Sts 0;
BA_ "GenSigTimeoutTime_GNMM" SG_ 1468 Enable_ClimateSchd1_Sts 0;
BA_ "GenSigTimeoutTime_HCP" SG_ 1468 Enable_ClimateSchd1_Sts 0;
BA_ "GenSigTimeoutTime_IPC" SG_ 1468 Enable_ClimateSchd1_Sts 0;
BA_ "GenSigTimeoutTime_RFHM" SG_ 1468 Enable_ClimateSchd1_Sts 0;
BA_ "GenSigTimeoutTime_TCM" SG_ 1468 Enable_ClimateSchd1_Sts 0;
BA_ "GenSigSendType" SG_ 1468 Enable_ClimateSchd2_Sts 3;
BA_ "GenSigTimeoutTime_AGSM" SG_ 1468 Enable_ClimateSchd2_Sts 0;
BA_ "GenSigTimeoutTime_BCM" SG_ 1468 Enable_ClimateSchd2_Sts 0;
BA_ "GenSigTimeoutTime_BSM" SG_ 1468 Enable_ClimateSchd2_Sts 0;
BA_ "GenSigTimeoutTime_CADM" SG_ 1468 Enable_ClimateSchd2_Sts 0;
BA_ "GenSigTimeoutTime_DMSM" SG_ 1468 Enable_ClimateSchd2_Sts 0;
BA_ "GenSigTimeoutTime_DTCM" SG_ 1468 Enable_ClimateSchd2_Sts 0;
BA_ "GenSigTimeoutTime_ECM" SG_ 1468 Enable_ClimateSchd2_Sts 0;
BA_ "GenSigTimeoutTime_EVCU2" SG_ 1468 Enable_ClimateSchd2_Sts 0;
BA_ "GenSigTimeoutTime_GNMM" SG_ 1468 Enable_ClimateSchd2_Sts 0;
BA_ "GenSigTimeoutTime_HCP" SG_ 1468 Enable_ClimateSchd2_Sts 0;
BA_ "GenSigTimeoutTime_IPC" SG_ 1468 Enable_ClimateSchd2_Sts 0;
BA_ "GenSigTimeoutTime_RFHM" SG_ 1468 Enable_ClimateSchd2_Sts 0;
BA_ "GenSigTimeoutTime_TCM" SG_ 1468 Enable_ClimateSchd2_Sts 0;
BA_ "GenSigSendType" SG_ 1471 AllowClimateSchd1 3;
BA_ "GenSigTimeoutTime_AGSM" SG_ 1471 AllowClimateSchd1 0;
BA_ "GenSigTimeoutTime_BCM" SG_ 1471 AllowClimateSchd1 0;
BA_ "GenSigTimeoutTime_BSM" SG_ 1471 AllowClimateSchd1 0;
BA_ "GenSigTimeoutTime_CADM" SG_ 1471 AllowClimateSchd1 0;
BA_ "GenSigTimeoutTime_DMSM" SG_ 1471 AllowClimateSchd1 0;
BA_ "GenSigTimeoutTime_DTCM" SG_ 1471 AllowClimateSchd1 0;
BA_ "GenSigTimeoutTime_ECM" SG_ 1471 AllowClimateSchd1 0;
BA_ "GenSigTimeoutTime_GNMM" SG_ 1471 AllowClimateSchd1 0;
BA_ "GenSigTimeoutTime_HCP" SG_ 1471 AllowClimateSchd1 0;
BA_ "GenSigTimeoutTime_IPC" SG_ 1471 AllowClimateSchd1 0;
BA_ "GenSigTimeoutTime_RFHM" SG_ 1471 AllowClimateSchd1 0;
BA_ "GenSigTimeoutTime_SGW" SG_ 1471 AllowClimateSchd1 0;
BA_ "GenSigTimeoutTime_TCM" SG_ 1471 AllowClimateSchd1 0;
BA_ "GenSigSendType" SG_ 1471 AllowClimateSchd2 3;
BA_ "GenSigTimeoutTime_AGSM" SG_ 1471 AllowClimateSchd2 0;
BA_ "GenSigTimeoutTime_BCM" SG_ 1471 AllowClimateSchd2 0;
BA_ "GenSigTimeoutTime_BSM" SG_ 1471 AllowClimateSchd2 0;
BA_ "GenSigTimeoutTime_CADM" SG_ 1471 AllowClimateSchd2 0;
BA_ "GenSigTimeoutTime_DMSM" SG_ 1471 AllowClimateSchd2 0;
BA_ "GenSigTimeoutTime_DTCM" SG_ 1471 AllowClimateSchd2 0;
BA_ "GenSigTimeoutTime_ECM" SG_ 1471 AllowClimateSchd2 0;
BA_ "GenSigTimeoutTime_GNMM" SG_ 1471 AllowClimateSchd2 0;
BA_ "GenSigTimeoutTime_HCP" SG_ 1471 AllowClimateSchd2 0;
BA_ "GenSigTimeoutTime_IPC" SG_ 1471 AllowClimateSchd2 0;
BA_ "GenSigTimeoutTime_RFHM" SG_ 1471 AllowClimateSchd2 0;
BA_ "GenSigTimeoutTime_SGW" SG_ 1471 AllowClimateSchd2 0;
BA_ "GenSigTimeoutTime_TCM" SG_ 1471 AllowClimateSchd2 0;
BA_ "GenSigStartValue" SG_ 1471 Climate_Cabin_Temp1 12;
BA_ "GenSigSendType" SG_ 1471 Climate_Cabin_Temp1 3;
BA_ "GenSigTimeoutTime_AGSM" SG_ 1471 Climate_Cabin_Temp1 0;
BA_ "GenSigTimeoutTime_BCM" SG_ 1471 Climate_Cabin_Temp1 0;
BA_ "GenSigTimeoutTime_BSM" SG_ 1471 Climate_Cabin_Temp1 0;
BA_ "GenSigTimeoutTime_CADM" SG_ 1471 Climate_Cabin_Temp1 0;
BA_ "GenSigTimeoutTime_DMSM" SG_ 1471 Climate_Cabin_Temp1 0;
BA_ "GenSigTimeoutTime_DTCM" SG_ 1471 Climate_Cabin_Temp1 0;
BA_ "GenSigTimeoutTime_ECM" SG_ 1471 Climate_Cabin_Temp1 0;
BA_ "GenSigTimeoutTime_GNMM" SG_ 1471 Climate_Cabin_Temp1 0;
BA_ "GenSigTimeoutTime_HCP" SG_ 1471 Climate_Cabin_Temp1 0;
BA_ "GenSigTimeoutTime_IPC" SG_ 1471 Climate_Cabin_Temp1 0;
BA_ "GenSigTimeoutTime_RFHM" SG_ 1471 Climate_Cabin_Temp1 0;
BA_ "GenSigTimeoutTime_SGW" SG_ 1471 Climate_Cabin_Temp1 0;
BA_ "GenSigTimeoutTime_TCM" SG_ 1471 Climate_Cabin_Temp1 0;
BA_ "GenSigStartValue" SG_ 1471 Climate_Cabin_Temp2 12;
BA_ "GenSigSendType" SG_ 1471 Climate_Cabin_Temp2 3;
BA_ "GenSigTimeoutTime_AGSM" SG_ 1471 Climate_Cabin_Temp2 0;
BA_ "GenSigTimeoutTime_BCM" SG_ 1471 Climate_Cabin_Temp2 0;
BA_ "GenSigTimeoutTime_BSM" SG_ 1471 Climate_Cabin_Temp2 0;
BA_ "GenSigTimeoutTime_CADM" SG_ 1471 Climate_Cabin_Temp2 0;
BA_ "GenSigTimeoutTime_DMSM" SG_ 1471 Climate_Cabin_Temp2 0;
BA_ "GenSigTimeoutTime_DTCM" SG_ 1471 Climate_Cabin_Temp2 0;
BA_ "GenSigTimeoutTime_ECM" SG_ 1471 Climate_Cabin_Temp2 0;
BA_ "GenSigTimeoutTime_GNMM" SG_ 1471 Climate_Cabin_Temp2 0;
BA_ "GenSigTimeoutTime_HCP" SG_ 1471 Climate_Cabin_Temp2 0;
BA_ "GenSigTimeoutTime_IPC" SG_ 1471 Climate_Cabin_Temp2 0;
BA_ "GenSigTimeoutTime_RFHM" SG_ 1471 Climate_Cabin_Temp2 0;
BA_ "GenSigTimeoutTime_SGW" SG_ 1471 Climate_Cabin_Temp2 0;
BA_ "GenSigTimeoutTime_TCM" SG_ 1471 Climate_Cabin_Temp2 0;
BA_ "GenSigSendType" SG_ 1471 ClimateSchd1_Day 3;
BA_ "GenSigTimeoutTime_AGSM" SG_ 1471 ClimateSchd1_Day 0;
BA_ "GenSigTimeoutTime_BCM" SG_ 1471 ClimateSchd1_Day 0;
BA_ "GenSigTimeoutTime_BSM" SG_ 1471 ClimateSchd1_Day 0;
BA_ "GenSigTimeoutTime_CADM" SG_ 1471 ClimateSchd1_Day 0;
BA_ "GenSigTimeoutTime_DMSM" SG_ 1471 ClimateSchd1_Day 0;
BA_ "GenSigTimeoutTime_DTCM" SG_ 1471 ClimateSchd1_Day 0;
BA_ "GenSigTimeoutTime_ECM" SG_ 1471 ClimateSchd1_Day 0;
BA_ "GenSigTimeoutTime_GNMM" SG_ 1471 ClimateSchd1_Day 0;
BA_ "GenSigTimeoutTime_HCP" SG_ 1471 ClimateSchd1_Day 0;
BA_ "GenSigTimeoutTime_IPC" SG_ 1471 ClimateSchd1_Day 0;
BA_ "GenSigTimeoutTime_RFHM" SG_ 1471 ClimateSchd1_Day 0;
BA_ "GenSigTimeoutTime_SGW" SG_ 1471 ClimateSchd1_Day 0;
BA_ "GenSigTimeoutTime_TCM" SG_ 1471 ClimateSchd1_Day 0;
BA_ "GenSigSendType" SG_ 1471 ClimateSchd1_Departure_Hr 3;
BA_ "GenSigTimeoutTime_AGSM" SG_ 1471 ClimateSchd1_Departure_Hr 0;
BA_ "GenSigTimeoutTime_BCM" SG_ 1471 ClimateSchd1_Departure_Hr 0;
BA_ "GenSigTimeoutTime_BSM" SG_ 1471 ClimateSchd1_Departure_Hr 0;
BA_ "GenSigTimeoutTime_CADM" SG_ 1471 ClimateSchd1_Departure_Hr 0;
BA_ "GenSigTimeoutTime_DMSM" SG_ 1471 ClimateSchd1_Departure_Hr 0;
BA_ "GenSigTimeoutTime_DTCM" SG_ 1471 ClimateSchd1_Departure_Hr 0;
BA_ "GenSigTimeoutTime_ECM" SG_ 1471 ClimateSchd1_Departure_Hr 0;
BA_ "GenSigTimeoutTime_GNMM" SG_ 1471 ClimateSchd1_Departure_Hr 0;
BA_ "GenSigTimeoutTime_HCP" SG_ 1471 ClimateSchd1_Departure_Hr 0;
BA_ "GenSigTimeoutTime_IPC" SG_ 1471 ClimateSchd1_Departure_Hr 0;
BA_ "GenSigTimeoutTime_RFHM" SG_ 1471 ClimateSchd1_Departure_Hr 0;
BA_ "GenSigTimeoutTime_SGW" SG_ 1471 ClimateSchd1_Departure_Hr 0;
BA_ "GenSigTimeoutTime_TCM" SG_ 1471 ClimateSchd1_Departure_Hr 0;
BA_ "GenSigSendType" SG_ 1471 ClimateSchd1_Departure_Min 3;
BA_ "GenSigTimeoutTime_AGSM" SG_ 1471 ClimateSchd1_Departure_Min 0;
BA_ "GenSigTimeoutTime_BCM" SG_ 1471 ClimateSchd1_Departure_Min 0;
BA_ "GenSigTimeoutTime_BSM" SG_ 1471 ClimateSchd1_Departure_Min 0;
BA_ "GenSigTimeoutTime_CADM" SG_ 1471 ClimateSchd1_Departure_Min 0;
BA_ "GenSigTimeoutTime_DMSM" SG_ 1471 ClimateSchd1_Departure_Min 0;
BA_ "GenSigTimeoutTime_DTCM" SG_ 1471 ClimateSchd1_Departure_Min 0;
BA_ "GenSigTimeoutTime_ECM" SG_ 1471 ClimateSchd1_Departure_Min 0;
BA_ "GenSigTimeoutTime_GNMM" SG_ 1471 ClimateSchd1_Departure_Min 0;
BA_ "GenSigTimeoutTime_HCP" SG_ 1471 ClimateSchd1_Departure_Min 0;
BA_ "GenSigTimeoutTime_IPC" SG_ 1471 ClimateSchd1_Departure_Min 0;
BA_ "GenSigTimeoutTime_RFHM" SG_ 1471 ClimateSchd1_Departure_Min 0;
BA_ "GenSigTimeoutTime_SGW" SG_ 1471 ClimateSchd1_Departure_Min 0;
BA_ "GenSigTimeoutTime_TCM" SG_ 1471 ClimateSchd1_Departure_Min 0;
BA_ "GenSigSendType" SG_ 1471 ClimateSchd2_Day 3;
BA_ "GenSigTimeoutTime_AGSM" SG_ 1471 ClimateSchd2_Day 0;
BA_ "GenSigTimeoutTime_BCM" SG_ 1471 ClimateSchd2_Day 0;
BA_ "GenSigTimeoutTime_BSM" SG_ 1471 ClimateSchd2_Day 0;
BA_ "GenSigTimeoutTime_CADM" SG_ 1471 ClimateSchd2_Day 0;
BA_ "GenSigTimeoutTime_DMSM" SG_ 1471 ClimateSchd2_Day 0;
BA_ "GenSigTimeoutTime_DTCM" SG_ 1471 ClimateSchd2_Day 0;
BA_ "GenSigTimeoutTime_ECM" SG_ 1471 ClimateSchd2_Day 0;
BA_ "GenSigTimeoutTime_GNMM" SG_ 1471 ClimateSchd2_Day 0;
BA_ "GenSigTimeoutTime_HCP" SG_ 1471 ClimateSchd2_Day 0;
BA_ "GenSigTimeoutTime_IPC" SG_ 1471 ClimateSchd2_Day 0;
BA_ "GenSigTimeoutTime_RFHM" SG_ 1471 ClimateSchd2_Day 0;
BA_ "GenSigTimeoutTime_SGW" SG_ 1471 ClimateSchd2_Day 0;
BA_ "GenSigTimeoutTime_TCM" SG_ 1471 ClimateSchd2_Day 0;
BA_ "GenSigSendType" SG_ 1471 ClimateSchd2_Departure_Hr 3;
BA_ "GenSigTimeoutTime_AGSM" SG_ 1471 ClimateSchd2_Departure_Hr 0;
BA_ "GenSigTimeoutTime_BCM" SG_ 1471 ClimateSchd2_Departure_Hr 0;
BA_ "GenSigTimeoutTime_BSM" SG_ 1471 ClimateSchd2_Departure_Hr 0;
BA_ "GenSigTimeoutTime_CADM" SG_ 1471 ClimateSchd2_Departure_Hr 0;
BA_ "GenSigTimeoutTime_DMSM" SG_ 1471 ClimateSchd2_Departure_Hr 0;
BA_ "GenSigTimeoutTime_DTCM" SG_ 1471 ClimateSchd2_Departure_Hr 0;
BA_ "GenSigTimeoutTime_ECM" SG_ 1471 ClimateSchd2_Departure_Hr 0;
BA_ "GenSigTimeoutTime_GNMM" SG_ 1471 ClimateSchd2_Departure_Hr 0;
BA_ "GenSigTimeoutTime_HCP" SG_ 1471 ClimateSchd2_Departure_Hr 0;
BA_ "GenSigTimeoutTime_IPC" SG_ 1471 ClimateSchd2_Departure_Hr 0;
BA_ "GenSigTimeoutTime_RFHM" SG_ 1471 ClimateSchd2_Departure_Hr 0;
BA_ "GenSigTimeoutTime_SGW" SG_ 1471 ClimateSchd2_Departure_Hr 0;
BA_ "GenSigTimeoutTime_TCM" SG_ 1471 ClimateSchd2_Departure_Hr 0;
BA_ "GenSigSendType" SG_ 1471 ClimateSchd2_Departure_Min 3;
BA_ "GenSigTimeoutTime_AGSM" SG_ 1471 ClimateSchd2_Departure_Min 0;
BA_ "GenSigTimeoutTime_BCM" SG_ 1471 ClimateSchd2_Departure_Min 0;
BA_ "GenSigTimeoutTime_BSM" SG_ 1471 ClimateSchd2_Departure_Min 0;
BA_ "GenSigTimeoutTime_CADM" SG_ 1471 ClimateSchd2_Departure_Min 0;
BA_ "GenSigTimeoutTime_DMSM" SG_ 1471 ClimateSchd2_Departure_Min 0;
BA_ "GenSigTimeoutTime_DTCM" SG_ 1471 ClimateSchd2_Departure_Min 0;
BA_ "GenSigTimeoutTime_ECM" SG_ 1471 ClimateSchd2_Departure_Min 0;
BA_ "GenSigTimeoutTime_GNMM" SG_ 1471 ClimateSchd2_Departure_Min 0;
BA_ "GenSigTimeoutTime_HCP" SG_ 1471 ClimateSchd2_Departure_Min 0;
BA_ "GenSigTimeoutTime_IPC" SG_ 1471 ClimateSchd2_Departure_Min 0;
BA_ "GenSigTimeoutTime_RFHM" SG_ 1471 ClimateSchd2_Departure_Min 0;
BA_ "GenSigTimeoutTime_SGW" SG_ 1471 ClimateSchd2_Departure_Min 0;
BA_ "GenSigTimeoutTime_TCM" SG_ 1471 ClimateSchd2_Departure_Min 0;
BA_ "GenSigSendType" SG_ 1471 Enable_ClimateSchd1 3;
BA_ "GenSigTimeoutTime_AGSM" SG_ 1471 Enable_ClimateSchd1 0;
BA_ "GenSigTimeoutTime_BCM" SG_ 1471 Enable_ClimateSchd1 0;
BA_ "GenSigTimeoutTime_BSM" SG_ 1471 Enable_ClimateSchd1 0;
BA_ "GenSigTimeoutTime_CADM" SG_ 1471 Enable_ClimateSchd1 0;
BA_ "GenSigTimeoutTime_DMSM" SG_ 1471 Enable_ClimateSchd1 0;
BA_ "GenSigTimeoutTime_DTCM" SG_ 1471 Enable_ClimateSchd1 0;
BA_ "GenSigTimeoutTime_ECM" SG_ 1471 Enable_ClimateSchd1 0;
BA_ "GenSigTimeoutTime_GNMM" SG_ 1471 Enable_ClimateSchd1 0;
BA_ "GenSigTimeoutTime_HCP" SG_ 1471 Enable_ClimateSchd1 0;
BA_ "GenSigTimeoutTime_IPC" SG_ 1471 Enable_ClimateSchd1 0;
BA_ "GenSigTimeoutTime_RFHM" SG_ 1471 Enable_ClimateSchd1 0;
BA_ "GenSigTimeoutTime_SGW" SG_ 1471 Enable_ClimateSchd1 0;
BA_ "GenSigTimeoutTime_TCM" SG_ 1471 Enable_ClimateSchd1 0;
BA_ "GenSigSendType" SG_ 1471 Enable_ClimateSchd2 3;
BA_ "GenSigTimeoutTime_AGSM" SG_ 1471 Enable_ClimateSchd2 0;
BA_ "GenSigTimeoutTime_BCM" SG_ 1471 Enable_ClimateSchd2 0;
BA_ "GenSigTimeoutTime_BSM" SG_ 1471 Enable_ClimateSchd2 0;
BA_ "GenSigTimeoutTime_CADM" SG_ 1471 Enable_ClimateSchd2 0;
BA_ "GenSigTimeoutTime_DMSM" SG_ 1471 Enable_ClimateSchd2 0;
BA_ "GenSigTimeoutTime_DTCM" SG_ 1471 Enable_ClimateSchd2 0;
BA_ "GenSigTimeoutTime_ECM" SG_ 1471 Enable_ClimateSchd2 0;
BA_ "GenSigTimeoutTime_GNMM" SG_ 1471 Enable_ClimateSchd2 0;
BA_ "GenSigTimeoutTime_HCP" SG_ 1471 Enable_ClimateSchd2 0;
BA_ "GenSigTimeoutTime_IPC" SG_ 1471 Enable_ClimateSchd2 0;
BA_ "GenSigTimeoutTime_RFHM" SG_ 1471 Enable_ClimateSchd2 0;
BA_ "GenSigTimeoutTime_SGW" SG_ 1471 Enable_ClimateSchd2 0;
BA_ "GenSigTimeoutTime_TCM" SG_ 1471 Enable_ClimateSchd2 0;
BA_ "GenSigSendType" SG_ 1471 Submit_ClimateSchd1 3;
BA_ "GenSigTimeoutTime_AGSM" SG_ 1471 Submit_ClimateSchd1 0;
BA_ "GenSigTimeoutTime_BCM" SG_ 1471 Submit_ClimateSchd1 0;
BA_ "GenSigTimeoutTime_BSM" SG_ 1471 Submit_ClimateSchd1 0;
BA_ "GenSigTimeoutTime_CADM" SG_ 1471 Submit_ClimateSchd1 0;
BA_ "GenSigTimeoutTime_DMSM" SG_ 1471 Submit_ClimateSchd1 0;
BA_ "GenSigTimeoutTime_DTCM" SG_ 1471 Submit_ClimateSchd1 0;
BA_ "GenSigTimeoutTime_ECM" SG_ 1471 Submit_ClimateSchd1 0;
BA_ "GenSigTimeoutTime_GNMM" SG_ 1471 Submit_ClimateSchd1 0;
BA_ "GenSigTimeoutTime_HCP" SG_ 1471 Submit_ClimateSchd1 0;
BA_ "GenSigTimeoutTime_IPC" SG_ 1471 Submit_ClimateSchd1 0;
BA_ "GenSigTimeoutTime_RFHM" SG_ 1471 Submit_ClimateSchd1 0;
BA_ "GenSigTimeoutTime_SGW" SG_ 1471 Submit_ClimateSchd1 0;
BA_ "GenSigTimeoutTime_TCM" SG_ 1471 Submit_ClimateSchd1 0;
BA_ "GenSigSendType" SG_ 1471 Submit_ClimateSchd2 3;
BA_ "GenSigTimeoutTime_AGSM" SG_ 1471 Submit_ClimateSchd2 0;
BA_ "GenSigTimeoutTime_BCM" SG_ 1471 Submit_ClimateSchd2 0;
BA_ "GenSigTimeoutTime_BSM" SG_ 1471 Submit_ClimateSchd2 0;
BA_ "GenSigTimeoutTime_CADM" SG_ 1471 Submit_ClimateSchd2 0;
BA_ "GenSigTimeoutTime_DMSM" SG_ 1471 Submit_ClimateSchd2 0;
BA_ "GenSigTimeoutTime_DTCM" SG_ 1471 Submit_ClimateSchd2 0;
BA_ "GenSigTimeoutTime_ECM" SG_ 1471 Submit_ClimateSchd2 0;
BA_ "GenSigTimeoutTime_GNMM" SG_ 1471 Submit_ClimateSchd2 0;
BA_ "GenSigTimeoutTime_HCP" SG_ 1471 Submit_ClimateSchd2 0;
BA_ "GenSigTimeoutTime_IPC" SG_ 1471 Submit_ClimateSchd2 0;
BA_ "GenSigTimeoutTime_RFHM" SG_ 1471 Submit_ClimateSchd2 0;
BA_ "GenSigTimeoutTime_SGW" SG_ 1471 Submit_ClimateSchd2 0;
BA_ "GenSigTimeoutTime_TCM" SG_ 1471 Submit_ClimateSchd2 0;
VAL_ 1457 Charge_Schedule_Type1_Sts 0 "No_Selection" 1 "Standard_Charge" 2 "External_Charge" 3 "Reserved";
VAL_ 1457 Charge_Schedule_Type2_Sts 0 "No_Selection" 1 "Standard_Charge" 2 "External_Charge" 3 "Reserved";
VAL_ 1457 ChargeUntilFull1_Sts 0 "Charge Until Full Not selected" 1 "Charge Until Full";
VAL_ 1457 ChargeUntilFull2_Sts 0 "Charge Until Full Not selected" 1 "Charge Until Full";
VAL_ 1457 End_Time_Hr1_Sts 31 "SNA";
VAL_ 1457 End_Time_Hr2_Sts 31 "SNA";
VAL_ 1457 End_Time_Min1_Sts 15 "SNA";
VAL_ 1457 End_Time_Min2_Sts 15 "SNA";
VAL_ 1457 External_ChargeTarget1_Sts 15 "No_Selection";
VAL_ 1457 External_ChargeTarget2_Sts 15 "No_Selection";
VAL_ 1457 Immediate_ChargeTarget1_Sts 15 "No_Selection";
VAL_ 1457 Immediate_ChargeTarget2_Sts 15 "No_Selection";
VAL_ 1457 Schedule_Confirmed1 0 "Disable" 1 "Enable";
VAL_ 1457 Schedule_Confirmed2 0 "Disable" 1 "Enable";
VAL_ 1457 Schedule_Day1_Sts 0 "No Selection" 1 "M" 2 "T" 3 "TM" 4 "W" 5 "WM" 6 "WT" 7 "WTM" 8 "Th" 9 "ThM" 10 "ThT" 11 "ThTM" 12 "ThW" 13 "ThWM" 14 "ThWT" 15 "ThWTM" 16 "F" 17 "FM" 18 "FT" 19 "FTM" 20 "FW" 21 "FWM" 22 "FWT" 23 "FWTM" 24 "FTh" 25 "FThM" 26 "FThT" 27 "FThTM" 28 "FThW" 29 "FThWM" 30 "FThWT" 31 "FThWTM" 32 "S" 33 "SM" 34 "ST" 35 "STM" 36 "SW" 37 "SWM" 38 "SWT" 39 "SWTM" 40 "STh" 41 "SThM" 42 "SThT" 43 "SThTM" 44 "SThW" 45 "SThWM" 46 "SThWT" 47 "SThWTM" 48 "SF" 49 "SFM" 50 "SFT" 51 "SFTM" 52 "SFW" 53 "SFWM" 54 "SFWT" 55 "SFWTM" 56 "SFTh" 57 "SFThM" 58 "SFThT" 59 "SFThTM" 60 "SFThW" 61 "SFThWM" 62 "SFThWT" 63 "SFThWTM" 64 "Sa" 65 "SaM" 66 "SaT" 67 "SaTM" 68 "SaW" 69 "SaWM" 70 "SaWT" 71 "SaWTM" 72 "SaTh" 73 "SaThM" 74 "SaThT" 75 "SaThTM" 76 "SaThW" 77 "SaThWM" 78 "SaThWT" 79 "SaThWTM" 80 "SaF" 81 "SaFM" 82 "SaFT" 83 "SaFTM" 84 "SaFW" 85 "SaFWM" 86 "SaFWT" 87 "SaFWTM" 88 "SaFTh" 89 "SaFThM" 90 "SaFThT" 91 "SaFThTM" 92 "SaFThW" 93 "SaFThWM" 94 "SaFThWT" 95 "SaFThWTM" 96 "SaS" 97 "SaSM" 98 "SaST" 99 "SaSTM" 100 "SaSW" 101 "SaSWM" 102 "SaSWT" 103 "SaSWTM" 104 "SaSTh" 105 "SaSThM" 106 "SaSThT" 107 "SaSThTM" 108 "SaSThW" 109 "SaSThWM" 110 "SaSThWT" 111 "SaSThWTM" 112 "SaSF" 113 "SaSFM" 114 "SaSFT" 115 "SaSFTM" 116 "SaSFW" 117 "SaSFWM" 118 "SaSFWT" 119 "SaSFWTM" 120 "SaSFTh" 121 "SaSFThM" 122 "SaSFThT" 123 "SaSFThTM" 124 "SaSFThW" 125 "SaSFThWM" 126 "SaSFThWT" 127 "SaSFThWTM" 255 "SNA";
VAL_ 1457 Schedule_Day2_Sts 0 "No Selection" 1 "M" 2 "T" 3 "TM" 4 "W" 5 "WM" 6 "WT" 7 "WTM" 8 "Th" 9 "ThM" 10 "ThT" 11 "ThTM" 12 "ThW" 13 "ThWM" 14 "ThWT" 15 "ThWTM" 16 "F" 17 "FM" 18 "FT" 19 "FTM" 20 "FW" 21 "FWM" 22 "FWT" 23 "FWTM" 24 "FTh" 25 "FThM" 26 "FThT" 27 "FThTM" 28 "FThW" 29 "FThWM" 30 "FThWT" 31 "FThWTM" 32 "S" 33 "SM" 34 "ST" 35 "STM" 36 "SW" 37 "SWM" 38 "SWT" 39 "SWTM" 40 "STh" 41 "SThM" 42 "SThT" 43 "SThTM" 44 "SThW" 45 "SThWM" 46 "SThWT" 47 "SThWTM" 48 "SF" 49 "SFM" 50 "SFT" 51 "SFTM" 52 "SFW" 53 "SFWM" 54 "SFWT" 55 "SFWTM" 56 "SFTh" 57 "SFThM" 58 "SFThT" 59 "SFThTM" 60 "SFThW" 61 "SFThWM" 62 "SFThWT" 63 "SFThWTM" 64 "Sa" 65 "SaM" 66 "SaT" 67 "SaTM" 68 "SaW" 69 "SaWM" 70 "SaWT" 71 "SaWTM" 72 "SaTh" 73 "SaThM" 74 "SaThT" 75 "SaThTM" 76 "SaThW" 77 "SaThWM" 78 "SaThWT" 79 "SaThWTM" 80 "SaF" 81 "SaFM" 82 "SaFT" 83 "SaFTM" 84 "SaFW" 85 "SaFWM" 86 "SaFWT" 87 "SaFWTM" 88 "SaFTh" 89 "SaFThM" 90 "SaFThT" 91 "SaFThTM" 92 "SaFThW" 93 "SaFThWM" 94 "SaFThWT" 95 "SaFThWTM" 96 "SaS" 97 "SaSM" 98 "SaST" 99 "SaSTM" 100 "SaSW" 101 "SaSWM" 102 "SaSWT" 103 "SaSWTM" 104 "SaSTh" 105 "SaSThM" 106 "SaSThT" 107 "SaSThTM" 108 "SaSThW" 109 "SaSThWM" 110 "SaSThWT" 111 "SaSThWTM" 112 "SaSF" 113 "SaSFM" 114 "SaSFT" 115 "SaSFTM" 116 "SaSFW" 117 "SaSFWM" 118 "SaSFWT" 119 "SaSFWTM" 120 "SaSFTh" 121 "SaSFThM" 122 "SaSFThT" 123 "SaSFThTM" 124 "SaSFThW" 125 "SaSFThWM" 126 "SaSFThWT" 127 "SaSFThWTM" 255 "SNA";
VAL_ 1457 Start_Time_Hr1_Sts 31 "SNA";
VAL_ 1457 Start_Time_Hr2_Sts 31 "SNA";
VAL_ 1457 Start_Time_Min1_Sts 15 "SNA";
VAL_ 1457 Start_Time_Min2_Sts 15 "SNA";
VAL_ 1464 Charge_Schedule_Type1 0 "No_Selection" 1 "Standard_Charge" 2 "External_Charge" 3 "Reserved";
VAL_ 1464 Charge_Schedule_Type2 0 "No_Selection" 1 "Standard_Charge" 2 "External_Charge" 3 "Reserved";
VAL_ 1464 ChargeUntilFull1 0 "Charge Until Full Not selected" 1 "Charge Until Full";
VAL_ 1464 ChargeUntilFull2 0 "Charge Until Full Not selected" 1 "Charge Until Full";
VAL_ 1464 Enable_Schedule1 0 "Disable schedule1" 1 "Enable schedule1";
VAL_ 1464 Enable_Schedule2 0 "Disable schedule2" 1 "Enable schedule2";
VAL_ 1464 End_Time_Hr1 31 "SNA";
VAL_ 1464 End_Time_Hr2 31 "SNA";
VAL_ 1464 End_Time_Min1 15 "SNA";
VAL_ 1464 End_Time_Min2 15 "SNA";
VAL_ 1464 External_ChargeTarget1 15 "No_Selection";
VAL_ 1464 External_ChargeTarget2 15 "No_Selection";
VAL_ 1464 Immediate_ChargeTarget1 15 "No_Selection";
VAL_ 1464 Immediate_ChargeTarget2 15 "No_Selection";
VAL_ 1464 Schedule_Day1 0 "No Selection" 1 "M" 2 "T" 3 "TM" 4 "W" 5 "WM" 6 "WT" 7 "WTM" 8 "Th" 9 "ThM" 10 "ThT" 11 "ThTM" 12 "ThW" 13 "ThWM" 14 "ThWT" 15 "ThWTM" 16 "F" 17 "FM" 18 "FT" 19 "FTM" 20 "FW" 21 "FWM" 22 "FWT" 23 "FWTM" 24 "FTh" 25 "FThM" 26 "FThT" 27 "FThTM" 28 "FThW" 29 "FThWM" 30 "FThWT" 31 "FThWTM" 32 "S" 33 "SM" 34 "ST" 35 "STM" 36 "SW" 37 "SWM" 38 "SWT" 39 "SWTM" 40 "STh" 41 "SThM" 42 "SThT" 43 "SThTM" 44 "SThW" 45 "SThWM" 46 "SThWT" 47 "SThWTM" 48 "SF" 49 "SFM" 50 "SFT" 51 "SFTM" 52 "SFW" 53 "SFWM" 54 "SFWT" 55 "SFWTM" 56 "SFTh" 57 "SFThM" 58 "SFThT" 59 "SFThTM" 60 "SFThW" 61 "SFThWM" 62 "SFThWT" 63 "SFThWTM" 64 "Sa" 65 "SaM" 66 "SaT" 67 "SaTM" 68 "SaW" 69 "SaWM" 70 "SaWT" 71 "SaWTM" 72 "SaTh" 73 "SaThM" 74 "SaThT" 75 "SaThTM" 76 "SaThW" 77 "SaThWM" 78 "SaThWT" 79 "SaThWTM" 80 "SaF" 81 "SaFM" 82 "SaFT" 83 "SaFTM" 84 "SaFW" 85 "SaFWM" 86 "SaFWT" 87 "SaFWTM" 88 "SaFTh" 89 "SaFThM" 90 "SaFThT" 91 "SaFThTM" 92 "SaFThW" 93 "SaFThWM" 94 "SaFThWT" 95 "SaFThWTM" 96 "SaS" 97 "SaSM" 98 "SaST" 99 "SaSTM" 100 "SaSW" 101 "SaSWM" 102 "SaSWT" 103 "SaSWTM" 104 "SaSTh" 105 "SaSThM" 106 "SaSThT" 107 "SaSThTM" 108 "SaSThW" 109 "SaSThWM" 110 "SaSThWT" 111 "SaSThWTM" 112 "SaSF" 113 "SaSFM" 114 "SaSFT" 115 "SaSFTM" 116 "SaSFW" 117 "SaSFWM" 118 "SaSFWT" 119 "SaSFWTM" 120 "SaSFTh" 121 "SaSFThM" 122 "SaSFThT" 123 "SaSFThTM" 124 "SaSFThW" 125 "SaSFThWM" 126 "SaSFThWT" 127 "SaSFThWTM" 255 "SNA";
VAL_ 1464 Schedule_Day2 0 "No Selection" 1 "M" 2 "T" 3 "TM" 4 "W" 5 "WM" 6 "WT" 7 "WTM" 8 "Th" 9 "ThM" 10 "ThT" 11 "ThTM" 12 "ThW" 13 "ThWM" 14 "ThWT" 15 "ThWTM" 16 "F" 17 "FM" 18 "FT" 19 "FTM" 20 "FW" 21 "FWM" 22 "FWT" 23 "FWTM" 24 "FTh" 25 "FThM" 26 "FThT" 27 "FThTM" 28 "FThW" 29 "FThWM" 30 "FThWT" 31 "FThWTM" 32 "S" 33 "SM" 34 "ST" 35 "STM" 36 "SW" 37 "SWM" 38 "SWT" 39 "SWTM" 40 "STh" 41 "SThM" 42 "SThT" 43 "SThTM" 44 "SThW" 45 "SThWM" 46 "SThWT" 47 "SThWTM" 48 "SF" 49 "SFM" 50 "SFT" 51 "SFTM" 52 "SFW" 53 "SFWM" 54 "SFWT" 55 "SFWTM" 56 "SFTh" 57 "SFThM" 58 "SFThT" 59 "SFThTM" 60 "SFThW" 61 "SFThWM" 62 "SFThWT" 63 "SFThWTM" 64 "Sa" 65 "SaM" 66 "SaT" 67 "SaTM" 68 "SaW" 69 "SaWM" 70 "SaWT" 71 "SaWTM" 72 "SaTh" 73 "SaThM" 74 "SaThT" 75 "SaThTM" 76 "SaThW" 77 "SaThWM" 78 "SaThWT" 79 "SaThWTM" 80 "SaF" 81 "SaFM" 82 "SaFT" 83 "SaFTM" 84 "SaFW" 85 "SaFWM" 86 "SaFWT" 87 "SaFWTM" 88 "SaFTh" 89 "SaFThM" 90 "SaFThT" 91 "SaFThTM" 92 "SaFThW" 93 "SaFThWM" 94 "SaFThWT" 95 "SaFThWTM" 96 "SaS" 97 "SaSM" 98 "SaST" 99 "SaSTM" 100 "SaSW" 101 "SaSWM" 102 "SaSWT" 103 "SaSWTM" 104 "SaSTh" 105 "SaSThM" 106 "SaSThT" 107 "SaSThTM" 108 "SaSThW" 109 "SaSThWM" 110 "SaSThWT" 111 "SaSThWTM" 112 "SaSF" 113 "SaSFM" 114 "SaSFT" 115 "SaSFTM" 116 "SaSFW" 117 "SaSFWM" 118 "SaSFWT" 119 "SaSFWTM" 120 "SaSFTh" 121 "SaSFThM" 122 "SaSFThT" 123 "SaSFThTM" 124 "SaSFThW" 125 "SaSFThWM" 126 "SaSFThWT" 127 "SaSFThWTM" 255 "SNA";
VAL_ 1464 Start_Time_Hr1 31 "SNA";
VAL_ 1464 Start_Time_Hr2 31 "SNA";
VAL_ 1464 Start_Time_Min1 15 "SNA";
VAL_ 1464 Start_Time_Min2 15 "SNA";
VAL_ 1464 Submit_Schedule1 0 "No Change" 1 "Change in schedule 1";
VAL_ 1464 Submit_Schedule2 0 "No Change" 1 "Change in schedule 2";
VAL_ 1459 Next_Charge_End_Time_Hr 0 "Hour_0" 1 "Hour_1" 2 "Hour_2" 3 "Hour_3" 4 "Hour_4" 5 "Hour_5" 6 "Hour_6" 7 "Hour_7" 8 "Hour_8" 9 "Hour_9" 10 "Hour_10" 11 "Hour_11" 12 "Hour_12" 13 "Hour_13" 14 "Hour_14" 15 "Hour_15" 16 "Hour_16" 17 "Hour_17" 18 "Hour_18" 19 "Hour_19" 20 "Hour_20" 21 "Hour_21" 22 "Hour_22" 23 "Hour_23" 25 "Charge_Until_Full" 31 "SNA";
VAL_ 1459 Next_Charge_End_Time_Min 15 "SNA";
VAL_ 1459 Next_Charge_EndDay 0 "No Selection" 1 "M" 2 "T" 3 "W" 4 "Th" 5 "F" 6 "Sa" 7 "S" 15 "SNA";
VAL_ 1459 Next_Charge_Start_Time_Hr 31 "SNA";
VAL_ 1459 Next_Charge_Start_Time_Min 15 "SNA";
VAL_ 1459 Next_Charge_StartDay 0 "No Selection" 1 "M" 2 "T" 3 "W" 4 "Th" 5 "F" 6 "Sa" 7 "S" 9 "No Schedule Set" 15 "SNA";
VAL_ 1459 Next_Climate_Day 0 "No Selection" 1 "M" 2 "T" 3 "W" 4 "Th" 5 "F" 6 "Sa" 7 "S" 9 "No Schedule Set" 15 "SNA";
VAL_ 1459 Next_Climate_Time_Hr 31 "SNA";
VAL_ 1459 Next_Climate_Time_Min 15 "SNA";
VAL_ 1459 Next_SchCabin_Temp 31 "SNA";
VAL_ 1459 Nxt_Charge_Schedule_Type 0 "No_Selection" 1 "Standard_Charge" 2 "External_Charge" 3 "Both";
VAL_ 1459 Nxt_Ext_Charge_End_Time_Hr 31 "SNA";
VAL_ 1459 Nxt_Ext_Charge_End_Time_Min 15 "SNA";
VAL_ 1459 Nxt_External_Charge_EndDay 0 "No_Selection" 1 "Monday" 2 "Tuesday" 3 "Wednesday" 4 "Thursday" 5 "Friday" 6 "Saturday" 7 "Sunday" 15 "SNA";
VAL_ 1459 Nxt_External_Charge_ExternalTgt 15 "No_Selection";
VAL_ 1459 Nxt_External_Charge_ImmediateTgt 15 "No_Selection";
VAL_ 1468 AllowClimateSchd1_Sts 0 "Any_Time " 1 "Plugged_In_Only" 2 "Plugged_In_and_In_Charge_Schd" 3 "SNA";
VAL_ 1468 AllowClimateSchd2_Sts 0 "Any_Time " 1 "Plugged_In_Only" 2 "Plugged_In_and_In_Charge_Schd" 3 "SNA";
VAL_ 1468 Climate_Cabin_Temp1_Sts 31 "SNA";
VAL_ 1468 Climate_Cabin_Temp2_Sts 31 "SNA";
VAL_ 1468 ClimateSchd1_Day_Sts 0 "No Selection" 1 "M" 2 "T" 3 "TM" 4 "W" 5 "WM" 6 "WT" 7 "WTM" 8 "Th" 9 "ThM" 10 "ThT" 11 "ThTM" 12 "ThW" 13 "ThWM" 14 "ThWT" 15 "ThWTM" 16 "F" 17 "FM" 18 "FT" 19 "FTM" 20 "FW" 21 "FWM" 22 "FWT" 23 "FWTM" 24 "FTh" 25 "FThM" 26 "FThT" 27 "FThTM" 28 "FThW" 29 "FThWM" 30 "FThWT" 31 "FThWTM" 32 "S" 33 "SM" 34 "ST" 35 "STM" 36 "SW" 37 "SWM" 38 "SWT" 39 "SWTM" 40 "STh" 41 "SThM" 42 "SThT" 43 "SThTM" 44 "SThW" 45 "SThWM" 46 "SThWT" 47 "SThWTM" 48 "SF" 49 "SFM" 50 "SFT" 51 "SFTM" 52 "SFW" 53 "SFWM" 54 "SFWT" 55 "SFWTM" 56 "SFTh" 57 "SFThM" 58 "SFThT" 59 "SFThTM" 60 "SFThW" 61 "SFThWM" 62 "SFThWT" 63 "SFThWTM" 64 "Su" 65 "SuM" 66 "SuT" 67 "SuTM" 68 "SuW" 69 "SuWM" 70 "SuWT" 71 "SuWTM" 72 "SuTh" 73 "SuThM" 74 "SuThT" 75 "SuThTM" 76 "SuThW" 77 "SuThWM" 78 "SuThWT" 79 "SuThWTM" 80 "SuF" 81 "SuFM" 82 "SuFT" 83 "SuFTM" 84 "SuFW" 85 "SuFWM" 86 "SuFWT" 87 "SuFWTM" 88 "SuFTh" 89 "SuFThM" 90 "SuFThT" 91 "SuFThTM" 92 "SuFThW" 93 "SuFThWM" 94 "SuFThWT" 95 "SuFThWTM" 96 "SuS" 97 "SuSM" 98 "SuST" 99 "SuSTM" 100 "SuSW" 101 "SuSWM" 102 "SuSWT" 103 "SuSWTM" 104 "SuSTh" 105 "SuSThM" 106 "SuSThT" 107 "SuSThTM" 108 "SuSThW" 109 "SuSThWM" 110 "SuSThWT" 111 "SuSThWTM" 112 "SuSF" 113 "SuSFM" 114 "SuSFT" 115 "SuSFTM" 116 "SuSFW" 117 "SuSFWM" 118 "SuSFWT" 119 "SuSFWTM" 120 "SuSFTh" 121 "SuSFThM" 122 "SuSFThT" 123 "SuSFThTM" 124 "SuSFThW" 125 "SuSFThWM" 126 "SuSFThWT" 127 "SuSFThWTM" 255 "SNA";
VAL_ 1468 ClimateSchd1_Departure_Hr_Sts 31 "SNA";
VAL_ 1468 ClimateSchd1_Departure_Min_Sts 15 "SNA";
VAL_ 1468 ClimateSchd2_Day_Sts 0 "No Selection" 1 "M" 2 "T" 3 "TM" 4 "W" 5 "WM" 6 "WT" 7 "WTM" 8 "Th" 9 "ThM" 10 "ThT" 11 "ThTM" 12 "ThW" 13 "ThWM" 14 "ThWT" 15 "ThWTM" 16 "F" 17 "FM" 18 "FT" 19 "FTM" 20 "FW" 21 "FWM" 22 "FWT" 23 "FWTM" 24 "FTh" 25 "FThM" 26 "FThT" 27 "FThTM" 28 "FThW" 29 "FThWM" 30 "FThWT" 31 "FThWTM" 32 "S" 33 "SM" 34 "ST" 35 "STM" 36 "SW" 37 "SWM" 38 "SWT" 39 "SWTM" 40 "STh" 41 "SThM" 42 "SThT" 43 "SThTM" 44 "SThW" 45 "SThWM" 46 "SThWT" 47 "SThWTM" 48 "SF" 49 "SFM" 50 "SFT" 51 "SFTM" 52 "SFW" 53 "SFWM" 54 "SFWT" 55 "SFWTM" 56 "SFTh" 57 "SFThM" 58 "SFThT" 59 "SFThTM" 60 "SFThW" 61 "SFThWM" 62 "SFThWT" 63 "SFThWTM" 64 "Su" 65 "SuM" 66 "SuT" 67 "SuTM" 68 "SuW" 69 "SuWM" 70 "SuWT" 71 "SuWTM" 72 "SuTh" 73 "SuThM" 74 "SuThT" 75 "SuThTM" 76 "SuThW" 77 "SuThWM" 78 "SuThWT" 79 "SuThWTM" 80 "SuF" 81 "SuFM" 82 "SuFT" 83 "SuFTM" 84 "SuFW" 85 "SuFWM" 86 "SuFWT" 87 "SuFWTM" 88 "SuFTh" 89 "SuFThM" 90 "SuFThT" 91 "SuFThTM" 92 "SuFThW" 93 "SuFThWM" 94 "SuFThWT" 95 "SuFThWTM" 96 "SuS" 97 "SuSM" 98 "SuST" 99 "SuSTM" 100 "SuSW" 101 "SuSWM" 102 "SuSWT" 103 "SuSWTM" 104 "SuSTh" 105 "SuSThM" 106 "SuSThT" 107 "SuSThTM" 108 "SuSThW" 109 "SuSThWM" 110 "SuSThWT" 111 "SuSThWTM" 112 "SuSF" 113 "SuSFM" 114 "SuSFT" 115 "SuSFTM" 116 "SuSFW" 117 "SuSFWM" 118 "SuSFWT" 119 "SuSFWTM" 120 "SuSFTh" 121 "SuSFThM" 122 "SuSFThT" 123 "SuSFThTM" 124 "SuSFThW" 125 "SuSFThWM" 126 "SuSFThWT" 127 "SuSFThWTM" 255 "SNA";
VAL_ 1468 ClimateSchd2_Departure_Hr_Sts 31 "SNA";
VAL_ 1468 ClimateSchd2_Departure_Min_Sts 15 "SNA";
VAL_ 1468 Enable_ClimateSchd1_Sts 0 "Disable" 1 "Enable";
VAL_ 1468 Enable_ClimateSchd2_Sts 0 "Disable" 1 "Enable";
VAL_ 1471 AllowClimateSchd1 0 "Any_Time " 1 "Plugged_In_Only" 2 "Plugged_In_and_In_Charge_Schd" 3 "SNA";
VAL_ 1471 AllowClimateSchd2 0 "Any_Time " 1 "Plugged_In_Only" 2 "Plugged_In_and_In_Charge_Schd" 3 "SNA";
VAL_ 1471 Climate_Cabin_Temp1 31 "SNA";
VAL_ 1471 Climate_Cabin_Temp2 31 "SNA";
VAL_ 1471 ClimateSchd1_Day 0 "No Selection" 1 "M" 2 "T" 3 "TM" 4 "W" 5 "WM" 6 "WT" 7 "WTM" 8 "Th" 9 "ThM" 10 "ThT" 11 "ThTM" 12 "ThW" 13 "ThWM" 14 "ThWT" 15 "ThWTM" 16 "F" 17 "FM" 18 "FT" 19 "FTM" 20 "FW" 21 "FWM" 22 "FWT" 23 "FWTM" 24 "FTh" 25 "FThM" 26 "FThT" 27 "FThTM" 28 "FThW" 29 "FThWM" 30 "FThWT" 31 "FThWTM" 32 "S" 33 "SM" 34 "ST" 35 "STM" 36 "SW" 37 "SWM" 38 "SWT" 39 "SWTM" 40 "STh" 41 "SThM" 42 "SThT" 43 "SThTM" 44 "SThW" 45 "SThWM" 46 "SThWT" 47 "SThWTM" 48 "SF" 49 "SFM" 50 "SFT" 51 "SFTM" 52 "SFW" 53 "SFWM" 54 "SFWT" 55 "SFWTM" 56 "SFTh" 57 "SFThM" 58 "SFThT" 59 "SFThTM" 60 "SFThW" 61 "SFThWM" 62 "SFThWT" 63 "SFThWTM" 64 "Su" 65 "SuM" 66 "SuT" 67 "SuTM" 68 "SuW" 69 "SuWM" 70 "SuWT" 71 "SuWTM" 72 "SuTh" 73 "SuThM" 74 "SuThT" 75 "SuThTM" 76 "SuThW" 77 "SuThWM" 78 "SuThWT" 79 "SuThWTM" 80 "SuF" 81 "SuFM" 82 "SuFT" 83 "SuFTM" 84 "SuFW" 85 "SuFWM" 86 "SuFWT" 87 "SuFWTM" 88 "SuFTh" 89 "SuFThM" 90 "SuFThT" 91 "SuFThTM" 92 "SuFThW" 93 "SuFThWM" 94 "SuFThWT" 95 "SuFThWTM" 96 "SuS" 97 "SuSM" 98 "SuST" 99 "SuSTM" 100 "SuSW" 101 "SuSWM" 102 "SuSWT" 103 "SuSWTM" 104 "SuSTh" 105 "SuSThM" 106 "SuSThT" 107 "SuSThTM" 108 "SuSThW" 109 "SuSThWM" 110 "SuSThWT" 111 "SuSThWTM" 112 "SuSF" 113 "SuSFM" 114 "SuSFT" 115 "SuSFTM" 116 "SuSFW" 117 "SuSFWM" 118 "SuSFWT" 119 "SuSFWTM" 120 "SuSFTh" 121 "SuSFThM" 122 "SuSFThT" 123 "SuSFThTM" 124 "SuSFThW" 125 "SuSFThWM" 126 "SuSFThWT" 127 "SuSFThWTM" 255 "SNA";
VAL_ 1471 ClimateSchd1_Departure_Hr 31 "SNA";
VAL_ 1471 ClimateSchd1_Departure_Min 15 "SNA";
VAL_ 1471 ClimateSchd2_Day 0 "No Selection" 1 "M" 2 "T" 3 "TM" 4 "W" 5 "WM" 6 "WT" 7 "WTM" 8 "Th" 9 "ThM" 10 "ThT" 11 "ThTM" 12 "ThW" 13 "ThWM" 14 "ThWT" 15 "ThWTM" 16 "F" 17 "FM" 18 "FT" 19 "FTM" 20 "FW" 21 "FWM" 22 "FWT" 23 "FWTM" 24 "FTh" 25 "FThM" 26 "FThT" 27 "FThTM" 28 "FThW" 29 "FThWM" 30 "FThWT" 31 "FThWTM" 32 "S" 33 "SM" 34 "ST" 35 "STM" 36 "SW" 37 "SWM" 38 "SWT" 39 "SWTM" 40 "STh" 41 "SThM" 42 "SThT" 43 "SThTM" 44 "SThW" 45 "SThWM" 46 "SThWT" 47 "SThWTM" 48 "SF" 49 "SFM" 50 "SFT" 51 "SFTM" 52 "SFW" 53 "SFWM" 54 "SFWT" 55 "SFWTM" 56 "SFTh" 57 "SFThM" 58 "SFThT" 59 "SFThTM" 60 "SFThW" 61 "SFThWM" 62 "SFThWT" 63 "SFThWTM" 64 "Su" 65 "SuM" 66 "SuT" 67 "SuTM" 68 "SuW" 69 "SuWM" 70 "SuWT" 71 "SuWTM" 72 "SuTh" 73 "SuThM" 74 "SuThT" 75 "SuThTM" 76 "SuThW" 77 "SuThWM" 78 "SuThWT" 79 "SuThWTM" 80 "SuF" 81 "SuFM" 82 "SuFT" 83 "SuFTM" 84 "SuFW" 85 "SuFWM" 86 "SuFWT" 87 "SuFWTM" 88 "SuFTh" 89 "SuFThM" 90 "SuFThT" 91 "SuFThTM" 92 "SuFThW" 93 "SuFThWM" 94 "SuFThWT" 95 "SuFThWTM" 96 "SuS" 97 "SuSM" 98 "SuST" 99 "SuSTM" 100 "SuSW" 101 "SuSWM" 102 "SuSWT" 103 "SuSWTM" 104 "SuSTh" 105 "SuSThM" 106 "SuSThT" 107 "SuSThTM" 108 "SuSThW" 109 "SuSThWM" 110 "SuSThWT" 111 "SuSThWTM" 112 "SuSF" 113 "SuSFM" 114 "SuSFT" 115 "SuSFTM" 116 "SuSFW" 117 "SuSFWM" 118 "SuSFWT" 119 "SuSFWTM" 120 "SuSFTh" 121 "SuSFThM" 122 "SuSFThT" 123 "SuSFThTM" 124 "SuSFThW" 125 "SuSFThWM" 126 "SuSFThWT" 127 "SuSFThWTM" 255 "SNA";
VAL_ 1471 ClimateSchd2_Departure_Hr 31 "SNA";
VAL_ 1471 ClimateSchd2_Departure_Min 15 "SNA";
VAL_ 1471 Enable_ClimateSchd1 0 "Disable_schedule1" 1 "Enable_schedule1";
VAL_ 1471 Enable_ClimateSchd2 0 "Disable_schedule2" 1 "Enable_schedule2";
VAL_ 1471 Submit_ClimateSchd1 0 "No_Change" 1 "Change_in_schedule1";
VAL_ 1471 Submit_ClimateSchd2 0 "No_Change" 1 "Change_in_schedule2";
